VERSION "HNNBNNNYNNNNNNNNNNNNNNNNNNNNNNNNNNNNNNNNNN/4/%%%/4/'%**4NNN///"

NS_ :

BS_:

BU_: BAP_Tester FASFrontradar ICAS1_X_Gateway MFK MFK120 MIK MRR2023 NR_1 NR_2

BO_ 258 ESC_50: 48 ICAS1_X_Gateway
 SG_ ESC_50_CRC : 0|8@1+ (1,0) [0|255] ""  FASFrontradar,MFK,MFK120,MRR2023
 SG_ ESC_50_BZ : 8|4@1+ (1,0) [0|15] ""  FASFrontradar,MFK,MFK120,MRR2023
 SG_ ESP_QBit_Gierrate : 12|1@1+ (1.0,0.0) [0.0|1] ""  FASFrontradar,MFK,MFK120,MRR2023
 SG_ ESP_QBit_Laengsbeschl : 13|1@1+ (1.0,0.0) [0.0|1] ""  FASFrontradar,MFK,MFK120,MRR2023
 SG_ ESP_QBit_Querb : 14|1@1+ (1.0,0.0) [0.0|1] ""  FASFrontradar,MFK,MFK120,MRR2023
 SG_ ESP_Querbeschleunigung : 16|8@1+ (0.01,-1.27) [-1.27|1.27] "Unit_ForceOfGravi"  FASFrontradar,MFK,MFK120,MRR2023
 SG_ ESP_Laengsbeschl : 24|10@1+ (0.03125,-16) [-16.00000|15.90625] "Unit_MeterPerSeconSquar"  FASFrontradar,MFK,MFK120,MRR2023
 SG_ ESC_Motorstartverzoegerung : 34|1@1+ (1.0,0.0) [0.0|1] ""  Vector__XXX
 SG_ ESC_SeitenwindAssistent_Eingriff : 35|1@1+ (1.0,0.0) [0.0|1] ""  Vector__XXX
 SG_ ESP_Anschleppstart_Freigabe : 36|2@1+ (1.0,0.0) [0.0|3] ""  Vector__XXX
 SG_ ESC_Unterdruckmangel_erkannt : 38|1@1+ (1.0,0.0) [0.0|1] ""  Vector__XXX
 SG_ ESP_Gierrate : 40|14@1+ (0.01,0) [0.00|163.82] "Unit_DegreOfArcPerSecon"  FASFrontradar,MFK,MFK120,MRR2023
 SG_ ESP_VZ_Gierrate : 54|1@1+ (1.0,0.0) [0.0|1] ""  FASFrontradar,MFK,MFK120,MRR2023
 SG_ ESP_Notbremsanzeige : 55|1@1+ (1.0,0.0) [0.0|1] ""  Vector__XXX
 SG_ ESP_SpannungsAnf : 56|1@1+ (1.0,0.0) [0.0|1] ""  Vector__XXX
 SG_ ESP_PLA_Abbruch : 57|3@1+ (1.0,0.0) [0.0|7] ""  Vector__XXX
 SG_ ESP_Status_ESP_PLA : 60|4@1+ (1.0,0.0) [0.0|15] ""  Vector__XXX
 SG_ ESP_QBit_Bremsdruck : 76|1@1+ (1.0,0.0) [0.0|1] ""  FASFrontradar,MFK,MFK120,MRR2023
 SG_ ESP_QBit_Fahrer_bremst : 77|1@1+ (1.0,0.0) [0.0|1] ""  Vector__XXX
 SG_ ESP_Schwelle_Unterdruck : 78|2@1+ (1.0,0.0) [0.0|3] ""  Vector__XXX
 SG_ ESP_Bremsdruck : 80|10@1+ (0.3,-30) [-30.0|276.6] "Unit_Bar"  FASFrontradar,MFK,MFK120,MRR2023
 SG_ ESP_Fahrer_bremst : 90|1@1+ (1.0,0.0) [0.0|1] ""  MFK,MFK120,MRR2023
 SG_ ESP_Verz_TSK_aktiv : 91|1@1+ (1.0,0.0) [0.0|1] ""  Vector__XXX
 SG_ ESP_Lenkeingriff_ADS : 92|1@1+ (1.0,0.0) [0.0|1] ""  Vector__XXX
 SG_ ESP_Konsistenz_TSK : 93|1@1+ (1.0,0.0) [0.0|1] ""  Vector__XXX
 SG_ ESP_Bremsruck_AWV2 : 94|1@1+ (1.0,0.0) [0.0|1] ""  Vector__XXX
 SG_ ESP_Konsistenz_AWV2 : 95|1@1+ (1.0,0.0) [0.0|1] ""  Vector__XXX
 SG_ ECD_Fehler : 96|1@1+ (1.0,0.0) [0.0|1] ""  Vector__XXX
 SG_ ECD_nicht_verfuegbar : 97|1@1+ (1.0,0.0) [0.0|1] ""  Vector__XXX
 SG_ ESP_Status_Bremsentemp : 98|1@1+ (1.0,0.0) [0.0|1] ""  Vector__XXX
 SG_ ESP_Autohold_Standby : 99|1@1+ (1.0,0.0) [0.0|1] ""  FASFrontradar,MRR2023
 SG_ ESP_HDC_Standby : 100|1@1+ (1.0,0.0) [0.0|1] ""  Vector__XXX
 SG_ ESP_HBA_aktiv : 101|1@1+ (1.0,0.0) [0.0|1] ""  Vector__XXX
 SG_ ESP_Prefill_ausgeloest : 102|1@1+ (1.0,0.0) [0.0|1] ""  MFK,MFK120
 SG_ ESP_Rueckwaertsfahrt_erkannt : 103|1@1+ (1.0,0.0) [0.0|1] ""  Vector__XXX
 SG_ ESP_Status_Anfahrhilfe : 104|1@1+ (1.0,0.0) [0.0|1] ""  Vector__XXX
 SG_ ESP_HDC_aktiv : 105|1@1+ (1.0,0.0) [0.0|1] ""  Vector__XXX
 SG_ ESP_StartStopp_Info : 106|2@1+ (1.0,0.0) [0.0|3] ""  Vector__XXX
 SG_ ESP_Eingr_HL : 108|1@1+ (1.0,0.0) [0.0|1] ""  Vector__XXX
 SG_ ESP_Eingr_HR : 109|1@1+ (1.0,0.0) [0.0|1] ""  Vector__XXX
 SG_ ESP_Eingr_VL : 110|1@1+ (1.0,0.0) [0.0|1] ""  Vector__XXX
 SG_ ESP_Eingr_VR : 111|1@1+ (1.0,0.0) [0.0|1] ""  Vector__XXX
 SG_ ESP_BKV_Unterdruck : 112|8@1+ (4,0) [4|1012] "Unit_MilliBar"  Vector__XXX
 SG_ ESP_Autohold_aktiv : 120|1@1+ (1.0,0.0) [0.0|1] ""  Vector__XXX
 SG_ ESP_FStatus_Anfahrhilfe : 121|1@1+ (1.0,0.0) [0.0|1] ""  Vector__XXX
 SG_ ESP_Verz_EPB_aktiv : 122|1@1+ (1.0,0.0) [0.0|1] ""  Vector__XXX
 SG_ ECD_Bremslicht : 123|1@1+ (1.0,0.0) [0.0|1] ""  MFK,MFK120
 SG_ ESP_Verzoeg_EPB_verf : 124|1@1+ (1.0,0.0) [0.0|1] ""  Vector__XXX
 SG_ ESP_Status_Bremsdruck : 125|1@1+ (1.0,0.0) [0.0|1] ""  Vector__XXX
 SG_ ESP_Anforderung_EPB : 126|2@1+ (1.0,0.0) [0.0|3] ""  Vector__XXX
 SG_ ESC_Fahrerradbremswunschmoment : 128|12@1+ (6,-2400) [-2400|22158] "Unit_NewtoMeter"  Vector__XXX
 SG_ ESP_ANB_CM_Rueckk_Umsetz : 140|1@1+ (1.0,0.0) [0.0|1] ""  Vector__XXX
 SG_ ESP_Konsistenz_ACC_Botschaft : 141|1@1+ (1.0,0.0) [0.0|1] ""  Vector__XXX
 SG_ ESP_Stillstandsphase_erschoepft : 142|1@1+ (1.0,0.0) [0.0|1] ""  Vector__XXX
 SG_ ESP_ZT_Rueckk_Umsetz : 143|1@1+ (1.0,0.0) [0.0|1] ""  Vector__XXX
 SG_ ESP_Tuerkontakt_Fahrertuer : 144|1@1+ (1.0,0.0) [0.0|1] ""  Vector__XXX
 SG_ ESP_Abrutschen_Stillstand : 146|1@1+ (1.0,0.0) [0.0|1] ""  Vector__XXX
 SG_ ESP_Fahrer_tritt_ZBR_Schw : 147|1@1+ (1.0,0.0) [0.0|1] ""  Vector__XXX
 SG_ ESP_Systemstatus_03 : 148|2@1+ (1.0,0.0) [0.0|3] ""  MRR2023
 SG_ ASR_Systemstatus : 150|2@1+ (1.0,0.0) [0.0|3] ""  Vector__XXX
 SG_ ESP_QBit_v_ref : 169|1@1+ (1.0,0.0) [0.0|1] ""  MFK
 SG_ ESP_v_ref_Fahrtrichtung : 170|2@1+ (1.0,0.0) [0.0|3] ""  MFK
 SG_ ESC_Bremsdruckgradient : 172|8@1+ (10,0) [0|2500] "Unit_BarPerSecon"  Vector__XXX
 SG_ ESP_v_ref : 180|12@1+ (0.125,0) [0.000|511.500] "Unit_KiloMeterPerHour"  MFK
 SG_ ESP_HBA_Empfindlichkeit : 220|3@1+ (1.0,0.0) [0.0|7] ""  Vector__XXX
 SG_ ESC_Hydr_Fkt_aktiv : 223|2@1+ (1.0,0.0) [0.0|3] ""  Vector__XXX
 SG_ ESC_QBit_Fahrerbremswunsch : 225|1@1+ (1.0,0.0) [0.0|1] ""  FASFrontradar,MFK,MFK120,MRR2023
 SG_ ESC_Fahrerbremswunsch : 226|10@1+ (0.3,-30) [-30.0|276.6] "Unit_Bar"  FASFrontradar,MFK,MFK120,MRR2023
 SG_ ESCGeneratorSollMoment : 236|12@1+ (3,-12279) [-12279|0] ""  Vector__XXX
 SG_ ESC_Raddruck_max : 248|8@1+ (1,0) [0|250] "Unit_Bar"  Vector__XXX
 SG_ EPB_QBit_Pedalweg_Kuppl : 269|1@1+ (1.0,0.0) [0.0|1] ""  Vector__XXX
 SG_ EPB_Freig_Verzoeg_Anf : 271|1@1+ (1.0,0.0) [0.0|1] ""  Vector__XXX
 SG_ EPB_Verzoeg_Anf : 272|8@1+ (0.048,-7.968) [-7.968|4.224] "Unit_MeterPerSeconSquar"  Vector__XXX
 SG_ EPB_Pedalweg_Kuppl : 288|8@1+ (0.4,0) [8.0|92.0] "Unit_PerCent"  Vector__XXX
 SG_ EPB_DAA_Randbed_erf : 305|1@1+ (1.0,0.0) [0.0|1] ""  Vector__XXX
 SG_ EPB_Fehlerstatus_02 : 306|2@1+ (1.0,0.0) [0.0|3] ""  MFK120
 SG_ EPB_Schalterposition : 308|2@1+ (1.0,0.0) [0.0|3] ""  FASFrontradar,MFK,MFK120,MRR2023
 SG_ EPB_QBit_Schalterpos : 310|1@1+ (1.0,0.0) [0.0|1] ""  FASFrontradar,MFK120,MRR2023
 SG_ EPB_Spannkraft : 312|5@1+ (1,0) [0|29] "Unit_KiloNewto"  Vector__XXX
 SG_ EPB_Status_02 : 317|3@1+ (1.0,0.0) [0.0|7] ""  FASFrontradar,MRR2023
 SG_ EPB_Status : 320|2@1+ (1.0,0.0) [0.0|3] ""  Vector__XXX
 SG_ ESP_Status_Bremsentemp_02 : 322|2@1+ (1.0,0.0) [0.0|3] ""  FASFrontradar,MRR2023
 SG_ SOK_ESC_50_Signatur : 352|32@1+ (1,0) [0|4294967295] ""  Vector__XXX

BO_ 252 ESC_51_Auth: 64 ICAS1_X_Gateway
 SG_ ESC_51_CRC : 0|8@1+ (1,0) [0|255] ""  FASFrontradar,MRR2023
 SG_ ESC_51_BZ : 8|4@1+ (1,0) [0|15] ""  FASFrontradar,MRR2023
 SG_ ESC_aktBR_Modus_02 : 12|2@1+ (1.0,0.0) [0.0|3] ""  Vector__XXX
 SG_ ESC_Blending_Solldruck : 14|10@1+ (0.25,0) [0.00|250.00] "Unit_Bar"  Vector__XXX
 SG_ ESC_aktBr_Volumenstrom : 24|16@1+ (0.0078125,-252) [-252.0000000|252.0000000] "Unit_MilliLiterPerSec"  Vector__XXX
 SG_ ESC_EBKV_Kraftblending_Modus : 40|2@1+ (1.0,0.0) [0.0|3] ""  Vector__XXX
 SG_ ESC_Bremsdruck_Modell : 42|10@1+ (0.25,0) [0.00|250.00] "Unit_Bar"  Vector__XXX
 SG_ ESC_Bremsdruck_02 : 52|10@1+ (0.3,-30) [-30.0|276.6] "Unit_Bar"  Vector__XXX
 SG_ ESC_QBit_Bremsdruck_02 : 62|1@1+ (1.0,0.0) [0.0|1] ""  Vector__XXX
 SG_ ESC_Allradverteilung_aktiv : 63|1@1+ (1.0,0.0) [0.0|1] ""  Vector__XXX
 SG_ ESP_HL_Radgeschw_02 : 64|16@1+ (0.0075,0) [0.0000|491.4900] "Unit_KiloMeterPerHour"  FASFrontradar,MFK,MFK120,MRR2023
 SG_ ESP_HR_Radgeschw_02 : 80|16@1+ (0.0075,0) [0.0000|491.4900] "Unit_KiloMeterPerHour"  FASFrontradar,MFK,MFK120,MRR2023
 SG_ ESP_VL_Radgeschw_02 : 96|16@1+ (0.0075,0) [0.0000|491.4900] "Unit_KiloMeterPerHour"  FASFrontradar,MFK,MFK120,MRR2023
 SG_ ESP_VR_Radgeschw_02 : 112|16@1+ (0.0075,0) [0.0000|491.4900] "Unit_KiloMeterPerHour"  FASFrontradar,MFK,MFK120,MRR2023
 SG_ ESP_FZR_uebersteuern : 128|8@1+ (0.004,0) [0.000|1.000] ""  FASFrontradar,MRR2023
 SG_ ESP_FZR_untersteuern : 136|8@1+ (0.004,0) [0.000|1.000] ""  FASFrontradar,MRR2023
 SG_ ESC_Anf_Mindestreku : 144|1@1+ (1.0,0.0) [0.0|1] ""  Vector__XXX
 SG_ ESC_GMV_aktiv : 145|3@1+ (1.0,0.0) [0.0|7] ""  FASFrontradar,MRR2023
 SG_ ESC_GMV_nicht_verfuegbar : 148|1@1+ (1.0,0.0) [0.0|1] ""  MRR2023
 SG_ ESC_Status_vRef_Stuetzeingriff : 149|1@1+ (1.0,0.0) [0.0|1] ""  Vector__XXX
 SG_ FDR_Allradverteilung_aktiv : 150|1@1+ (1.0,0.0) [0.0|1] ""  Vector__XXX
 SG_ FDR_Anf_Allradbetrieb : 151|1@1+ (1.0,0.0) [0.0|1] ""  Vector__XXX
 SG_ ESP_HL_Bremsmoment : 152|8@1+ (20,0) [0|5060] "Unit_NewtoMeter"  Vector__XXX
 SG_ ESP_HR_Bremsmoment : 160|8@1+ (20,0) [0|5060] "Unit_NewtoMeter"  Vector__XXX
 SG_ ESP_VR_Bremsmoment : 168|8@1+ (40,0) [0|10120] "Unit_NewtoMeter"  Vector__XXX
 SG_ ESP_VL_Bremsmoment : 176|8@1+ (40,0) [0|10120] "Unit_NewtoMeter"  Vector__XXX
 SG_ ESP_FDR_uebersteuern : 184|8@1+ (0.004,0) [0.000|1.000] ""  Vector__XXX
 SG_ ESP_FDR_untersteuern : 192|8@1+ (0.004,0) [0.000|1.000] ""  Vector__XXX
 SG_ TSMomBegrenzung : 268|12@1+ (3,-12279) [-12279|0] ""  Vector__XXX
 SG_ ESC_Allrad_Anteil_max_sek : 280|9@1+ (0.2,0) [0.0|100.0] "Unit_PerCent"  Vector__XXX
 SG_ ESC_Allrad_Anteil_min_sek : 289|9@1+ (0.2,0) [0.0|100.0] "Unit_PerCent"  Vector__XXX
 SG_ ESC_Status_Eingriff : 298|2@1+ (1.0,0.0) [0.0|3] ""  MFK120
 SG_ ESC_Status_Eingriff_sek : 300|2@1+ (1.0,0.0) [0.0|3] ""  Vector__XXX
 SG_ ESC_MomRad_Eingriff : 302|13@1+ (3,-12279) [-12279|12279] "Unit_None"  Vector__XXX
 SG_ ESC_MomRad_Eingriff_sek : 315|13@1+ (3,-12279) [-12279|12279] "Unit_None"  Vector__XXX
 SG_ ESC_Achsdrehzahl_Max : 328|14@1+ (0.4,-800) [-800.0|5752.4] "Unit_MinutInver"  Vector__XXX
 SG_ ESC_Achsdrehzahl_Min : 342|14@1+ (0.4,-800) [-800.0|5752.4] "Unit_MinutInver"  Vector__XXX
 SG_ ESC_Achsdrehzahl_Max_sek : 356|14@1+ (0.4,-800) [-800.0|5752.4] "Unit_MinutInver"  Vector__XXX
 SG_ ESC_Achsdrehzahl_Min_sek : 370|14@1+ (0.4,-800) [-800.0|5752.4] "Unit_MinutInver"  Vector__XXX
 SG_ SOK_ESC_51_Signatur : 480|32@1+ (1,0) [0|4294967295] ""  Vector__XXX

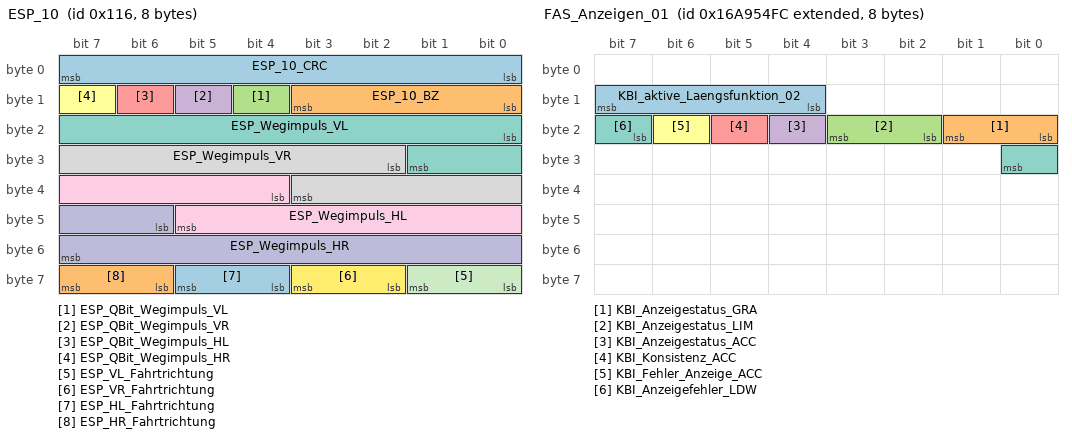
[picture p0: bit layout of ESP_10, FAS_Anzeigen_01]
BO_ 278 ESP_10: 8 ICAS1_X_Gateway
 SG_ ESP_10_CRC : 0|8@1+ (1,0) [0|255] ""  FASFrontradar,MRR2023
 SG_ ESP_10_BZ : 8|4@1+ (1,0) [0|15] ""  FASFrontradar,MRR2023
 SG_ ESP_QBit_Wegimpuls_VL : 12|1@1+ (1.0,0.0) [0.0|1] ""  FASFrontradar,MFK,MFK120,MRR2023
 SG_ ESP_QBit_Wegimpuls_VR : 13|1@1+ (1.0,0.0) [0.0|1] ""  FASFrontradar,MFK,MFK120,MRR2023
 SG_ ESP_QBit_Wegimpuls_HL : 14|1@1+ (1.0,0.0) [0.0|1] ""  FASFrontradar,MFK,MFK120,MRR2023
 SG_ ESP_QBit_Wegimpuls_HR : 15|1@1+ (1.0,0.0) [0.0|1] ""  FASFrontradar,MFK,MFK120,MRR2023
 SG_ ESP_Wegimpuls_VL : 16|10@1+ (1,0) [0|1000] ""  FASFrontradar,MFK,MFK120,MRR2023
 SG_ ESP_Wegimpuls_VR : 26|10@1+ (1,0) [0|1000] ""  FASFrontradar,MFK,MFK120,MRR2023
 SG_ ESP_Wegimpuls_HL : 36|10@1+ (1,0) [0|1000] ""  FASFrontradar,MFK,MFK120,MRR2023
 SG_ ESP_Wegimpuls_HR : 46|10@1+ (1,0) [0|1000] ""  FASFrontradar,MFK,MFK120,MRR2023
 SG_ ESP_VL_Fahrtrichtung : 56|2@1+ (1.0,0.0) [0.0|3] ""  FASFrontradar,MFK,MFK120,MRR2023
 SG_ ESP_VR_Fahrtrichtung : 58|2@1+ (1.0,0.0) [0.0|3] ""  FASFrontradar,MFK,MFK120,MRR2023
 SG_ ESP_HL_Fahrtrichtung : 60|2@1+ (1.0,0.0) [0.0|3] ""  FASFrontradar,MFK,MFK120,MRR2023
 SG_ ESP_HR_Fahrtrichtung : 62|2@1+ (1.0,0.0) [0.0|3] ""  FASFrontradar,MFK,MFK120,MRR2023

BO_ 1629 ESP_20: 8 ICAS1_X_Gateway
 SG_ ESP_20_CRC : 0|8@1+ (1,0) [0|255] ""  MRR2023
 SG_ ESP_20_BZ : 8|4@1+ (1,0) [0|15] ""  MRR2023
 SG_ BR_Systemart : 12|2@1+ (1.0,0.0) [0.0|3] ""  Vector__XXX
 SG_ ESP_SpannungsAnf_02 : 14|2@1+ (1.0,0.0) [0.0|3] ""  Vector__XXX
 SG_ ESP_Zaehnezahl : 16|8@1+ (1,0) [0|255] ""  FASFrontradar,MFK120,MRR2023
 SG_ ESP_Charisma_FahrPr : 24|4@1+ (1.0,0.0) [0.0|15] ""  Vector__XXX
 SG_ ESP_Charisma_Status : 28|2@1+ (1.0,0.0) [0.0|3] ""  Vector__XXX
 SG_ ESP_Wiederstart_Anz_01 : 30|1@1+ (1.0,0.0) [0.0|1] ""  Vector__XXX
 SG_ ESP_Wiederstart_Anz_02 : 31|1@1+ (1.0,0.0) [0.0|1] ""  Vector__XXX
 SG_ ESP_Wiederstart_Anz_03 : 32|1@1+ (1.0,0.0) [0.0|1] ""  Vector__XXX
 SG_ ESP_Wiederstart_Anz_04 : 33|1@1+ (1.0,0.0) [0.0|1] ""  Vector__XXX
 SG_ ESP_Stoppverbot_Anz_01 : 34|1@1+ (1.0,0.0) [0.0|1] ""  Vector__XXX
 SG_ ESP_Stoppverbot_Anz_02 : 35|1@1+ (1.0,0.0) [0.0|1] ""  Vector__XXX
 SG_ ESP_Stoppverbot_Anz_03 : 36|1@1+ (1.0,0.0) [0.0|1] ""  Vector__XXX
 SG_ ESP_Stoppverbot_Anz_04 : 37|1@1+ (1.0,0.0) [0.0|1] ""  Vector__XXX
 SG_ ESP_Stoppverbot_Anz_05 : 38|1@1+ (1.0,0.0) [0.0|1] ""  Vector__XXX
 SG_ ESP_Stoppverbot_Anz_06 : 39|1@1+ (1.0,0.0) [0.0|1] ""  Vector__XXX
 SG_ ESP_Stoppverbot_Anz_07 : 40|1@1+ (1.0,0.0) [0.0|1] ""  Vector__XXX
 SG_ ESP_Stoppverbot_Anz_Std : 41|1@1+ (1.0,0.0) [0.0|1] ""  Vector__XXX
 SG_ ESP_Dachrelingsensor : 42|2@1+ (1.0,0.0) [0.0|3] ""  Vector__XXX
 SG_ ESP_Stoppverbot_Anz_08 : 44|1@1+ (1.0,0.0) [0.0|1] ""  Vector__XXX
 SG_ HDC_Charisma_FahrPr : 45|4@1+ (1.0,0.0) [0.0|15] ""  Vector__XXX
 SG_ HDC_Charisma_Status : 49|2@1+ (1.0,0.0) [0.0|3] ""  Vector__XXX
 SG_ BR_QBit_Reifenumfang : 51|1@1+ (1.0,0.0) [0.0|1] ""  MFK,MFK120
 SG_ BR_Reifenumfang : 52|12@1+ (1,0) [0|4095] "Unit_MilliMeter"  MFK,MFK120

BO_ 253 ESP_21: 8 ICAS1_X_Gateway
 SG_ ESP_21_CRC : 0|8@1+ (1,0) [0|255] ""  FASFrontradar,MFK,MFK120,MRR2023
 SG_ ESP_21_BZ : 8|4@1+ (1,0) [0|15] ""  FASFrontradar,MFK,MFK120,MRR2023
 SG_ BR_Eingriffsmoment : 12|10@1+ (1,-509) [-509|509] ""  Vector__XXX
 SG_ ESP_PLA_Bremseingriff : 22|1@1+ (1.0,0.0) [0.0|1] ""  Vector__XXX
 SG_ ESP_Diagnose : 23|1@1+ (1.0,0.0) [0.0|1] ""  FASFrontradar,MRR2023
 SG_ ESC_Reku_Freigabe : 24|1@1+ (1.0,0.0) [0.0|1] ""  Vector__XXX
 SG_ ESC_v_Signal_Qualifier_High_Low : 25|3@1+ (1.0,0.0) [0.0|7] ""  FASFrontradar,MFK,MFK120,MIK,MRR2023
 SG_ ESP_Vorsteuerung : 28|1@1+ (1.0,0.0) [0.0|1] ""  FASFrontradar,MRR2023
 SG_ ESP_AWV3_Brems_aktiv : 29|1@1+ (1.0,0.0) [0.0|1] ""  Vector__XXX
 SG_ OBD_Schlechtweg : 30|1@1+ (1.0,0.0) [0.0|1] ""  Vector__XXX
 SG_ OBD_QBit_Schlechtweg : 31|1@1+ (1.0,0.0) [0.0|1] ""  Vector__XXX
 SG_ ESP_v_Signal : 32|16@1+ (0.01,0) [0.00|655.32] "Unit_KiloMeterPerHour"  FASFrontradar,MFK,MFK120,MIK,MRR2023
 SG_ ASR_Tastung_passiv : 48|1@1+ (1.0,0.0) [0.0|1] ""  FASFrontradar,MFK,MFK120,MRR2023
 SG_ ESP_Tastung_passiv : 49|1@1+ (1.0,0.0) [0.0|1] ""  FASFrontradar,MFK,MFK120,MRR2023
 SG_ ESP_Systemstatus : 50|1@1+ (1.0,0.0) [0.0|1] ""  FASFrontradar,MFK,MFK120,MRR2023
 SG_ ASR_Schalteingriff : 51|2@1+ (1.0,0.0) [0.0|3] ""  Vector__XXX
 SG_ ESP_Haltebestaetigung : 53|1@1+ (1.0,0.0) [0.0|1] ""  Vector__XXX
 SG_ ESP_MKB_Abbruch_Geschw : 54|1@1+ (1.0,0.0) [0.0|1] ""  Vector__XXX
 SG_ ESP_QBit_v_Signal : 55|1@1+ (1.0,0.0) [0.0|1] ""  FASFrontradar,MFK,MFK120,MIK,MRR2023
 SG_ ABS_Bremsung : 56|1@1+ (1.0,0.0) [0.0|1] ""  FASFrontradar,MFK,MFK120,MRR2023
 SG_ ASR_Anf : 57|1@1+ (1.0,0.0) [0.0|1] ""  FASFrontradar,MFK,MFK120,MRR2023
 SG_ MSR_Anf : 58|1@1+ (1.0,0.0) [0.0|1] ""  FASFrontradar,MFK,MFK120,MRR2023
 SG_ EBV_Eingriff : 59|1@1+ (1.0,0.0) [0.0|1] ""  FASFrontradar,MRR2023
 SG_ EDS_Eingriff : 60|1@1+ (1.0,0.0) [0.0|1] ""  FASFrontradar,MFK,MRR2023
 SG_ ESP_Eingriff : 61|1@1+ (1.0,0.0) [0.0|1] ""  FASFrontradar,MFK,MFK120,MRR2023
 SG_ ESP_ASP : 62|1@1+ (1.0,0.0) [0.0|1] ""  FASFrontradar,MFK,MFK120,MRR2023
 SG_ ESP_Anhaltevorgang_ACC_aktiv : 63|1@1+ (1.0,0.0) [0.0|1] ""  Vector__XXX

BO_ 2527679740 FAS_Anzeigen_01: 8 ICAS1_X_Gateway
 SG_ KBI_aktive_Laengsfunktion_02 : 12|4@1+ (1.0,0.0) [0.0|15] ""  FASFrontradar,MFK,MFK120,MRR2023
 SG_ KBI_Anzeigestatus_GRA : 16|2@1+ (1.0,0.0) [0.0|3] ""  Vector__XXX
 SG_ KBI_Anzeigestatus_LIM : 18|2@1+ (1.0,0.0) [0.0|3] ""  Vector__XXX
 SG_ KBI_Anzeigestatus_ACC : 20|1@1+ (1.0,0.0) [0.0|1] ""  FASFrontradar,MRR2023
 SG_ KBI_Konsistenz_ACC : 21|1@1+ (1.0,0.0) [0.0|1] ""  FASFrontradar,MRR2023
 SG_ KBI_Fehler_Anzeige_ACC : 22|1@1+ (1.0,0.0) [0.0|1] ""  FASFrontradar,MRR2023
 SG_ KBI_Anzeigefehler_LDW : 23|2@1+ (1.0,0.0) [0.0|3] ""  MFK

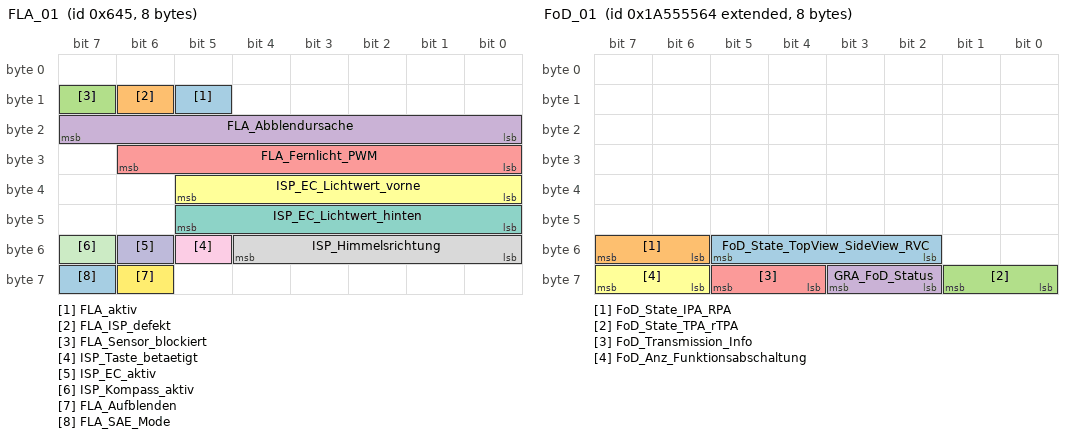
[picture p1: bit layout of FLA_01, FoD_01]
BO_ 1605 FLA_01: 8 MFK
 SG_ FLA_aktiv : 13|1@1+ (1.0,0.0) [0.0|1] ""  ICAS1_X_Gateway
 SG_ FLA_ISP_defekt : 14|1@1+ (1.0,0.0) [0.0|1] ""  ICAS1_X_Gateway
 SG_ FLA_Sensor_blockiert : 15|1@1+ (1.0,0.0) [0.0|1] ""  ICAS1_X_Gateway
 SG_ FLA_Abblendursache : 16|8@1+ (1.0,0.0) [0.0|255] ""  ICAS1_X_Gateway
 SG_ FLA_Fernlicht_PWM : 24|7@1+ (1,0) [0|100] "Unit_PerCent"  ICAS1_X_Gateway
 SG_ ISP_EC_Lichtwert_vorne : 32|6@1+ (1,0) [0|61] "Unit_None"  ICAS1_X_Gateway
 SG_ ISP_EC_Lichtwert_hinten : 40|6@1+ (1,0) [0|61] "Unit_None"  ICAS1_X_Gateway
 SG_ ISP_Himmelsrichtung : 48|5@1+ (12,0) [0|348] "Unit_DegreOfArc"  ICAS1_X_Gateway
 SG_ ISP_Taste_betaetigt : 53|1@1+ (1.0,0.0) [0.0|1] ""  ICAS1_X_Gateway
 SG_ ISP_EC_aktiv : 54|1@1+ (1.0,0.0) [0.0|1] ""  ICAS1_X_Gateway
 SG_ ISP_Kompass_aktiv : 55|1@1+ (1.0,0.0) [0.0|1] ""  ICAS1_X_Gateway
 SG_ FLA_Aufblenden : 62|1@1+ (1.0,0.0) [0.0|1] ""  ICAS1_X_Gateway
 SG_ FLA_SAE_Mode : 63|1@1+ (1.0,0.0) [0.0|1] ""  ICAS1_X_Gateway

BO_ 2589283684 FoD_01: 8 ICAS1_X_Gateway
 SG_ FoD_State_TopView_SideView_RVC : 50|4@1+ (1.0,0.0) [0.0|15] ""  Vector__XXX
 SG_ FoD_State_IPA_RPA : 54|2@1+ (1.0,0.0) [0.0|3] ""  Vector__XXX
 SG_ FoD_State_TPA_rTPA : 56|2@1+ (1.0,0.0) [0.0|3] ""  MFK,MFK120
 SG_ GRA_FoD_Status : 58|2@1+ (1.0,0.0) [0.0|3] ""  Vector__XXX
 SG_ FoD_Transmission_Info : 60|2@1+ (1.0,0.0) [0.0|3] ""  FASFrontradar,MFK,MRR2023
 SG_ FoD_Anz_Funktionsabschaltung : 62|2@1+ (1.0,0.0) [0.0|3] ""  Vector__XXX

BO_ 2549875543 FoD_ACC_Req: 8 ICAS1_X_Gateway
 SG_ FoD_ACC_Req_Data : 0|64@1+ (1.0,0.0) [0.0|18446744073709551615] ""  FASFrontradar,MRR2023

BO_ 2550006615 FoD_ACC_Resp: 8 FASFrontradar
 SG_ FoD_ACC_Resp_Data : 0|64@1+ (1.0,0.0) [0.0|18446744073709551615] ""  ICAS1_X_Gateway

BO_ 2549875535 FoD_Kamera_Req: 8 ICAS1_X_Gateway
 SG_ FoD_Kamera_Req_Data : 0|64@1+ (1.0,0.0) [0.0|18446744073709551615] ""  MFK,MFK120

BO_ 2550006607 FoD_Kamera_Resp: 8 MFK
 SG_ FoD_Kamera_Resp_Data : 0|64@1+ (1.0,0.0) [0.0|18446744073709551615] ""  ICAS1_X_Gateway

BO_ 987 Gateway_72: 8 ICAS1_X_Gateway
 SG_ BCM_01_alt : 0|1@1+ (1.0,0.0) [0.0|1] ""  FASFrontradar,MRR2023
 SG_ SMLS_01_alt : 1|1@1+ (1.0,0.0) [0.0|1] ""  Vector__XXX
 SG_ ZV_02_alt : 2|1@1+ (1.0,0.0) [0.0|1] ""  Vector__XXX
 SG_ Wischer_01_alt : 3|1@1+ (1.0,0.0) [0.0|1] ""  FASFrontradar,MFK,MRR2023
 SG_ Anhaenger_01_alt : 4|1@1+ (1.0,0.0) [0.0|1] ""  Vector__XXX
 SG_ Klima_Sensor_02_alt : 5|1@1+ (1.0,0.0) [0.0|1] ""  FASFrontradar,MFK,MRR2023
 SG_ Verdeck_01_alt : 6|1@1+ (1.0,0.0) [0.0|1] ""  Vector__XXX
 SG_ Klima_11_alt : 7|1@1+ (1.0,0.0) [0.0|1] ""  Vector__XXX
 SG_ WFS_01_alt : 8|1@1+ (1.0,0.0) [0.0|1] ""  Vector__XXX
 SG_ Licht_Anf_01_alt : 9|1@1+ (1.0,0.0) [0.0|1] ""  Vector__XXX
 SG_ ZV_verriegelt_extern_soll : 10|1@1+ (1.0,0.0) [0.0|1] ""  Vector__XXX
 SG_ BH_Lichthupe : 11|1@1+ (1.0,0.0) [0.0|1] ""  Vector__XXX
 SG_ WFS_Klemmenfreigabe : 12|1@1+ (1.0,0.0) [0.0|1] ""  Vector__XXX
 SG_ ZV_Tankklappe_offen : 13|1@1+ (1.0,0.0) [0.0|1] ""  Vector__XXX
 SG_ AAG_Anhaenger_abgesteckt : 14|1@1+ (1.0,0.0) [0.0|1] ""  Vector__XXX
 SG_ BCM1_LDS_Stellung : 15|3@1+ (1.0,0.0) [0.0|7] ""  Vector__XXX
 SG_ VS_Verdeck_Anf : 18|1@1+ (1.0,0.0) [0.0|1] ""  Vector__XXX
 SG_ VS_VD_entriegelt : 19|1@1+ (1.0,0.0) [0.0|1] ""  Vector__XXX
 SG_ ZV_HFS_offen : 20|1@1+ (1.0,0.0) [0.0|1] ""  Vector__XXX
 SG_ ZV_HBFS_offen : 21|1@1+ (1.0,0.0) [0.0|1] ""  Vector__XXX
 SG_ VS_VD_offen_ver : 22|1@1+ (1.0,0.0) [0.0|1] ""  Vector__XXX
 SG_ VS_VD_zu_ver : 23|1@1+ (1.0,0.0) [0.0|1] ""  Vector__XXX
 SG_ ZV_BT_offen : 24|1@1+ (1.0,0.0) [0.0|1] ""  Vector__XXX
 SG_ BCM1_Rueckfahrlicht_Schalter : 25|1@1+ (1.0,0.0) [0.0|1] ""  Vector__XXX
 SG_ ZV_FT_offen : 26|1@1+ (1.0,0.0) [0.0|1] ""  Vector__XXX
 SG_ Wischer_vorne_aktiv : 27|1@1+ (1.0,0.0) [0.0|1] ""  FASFrontradar,MFK,MFK120,MRR2023
 SG_ AAG_Anhaenger_erkannt : 28|1@1+ (1.0,0.0) [0.0|1] ""  Vector__XXX
 SG_ BCM1_MH_Schalter : 29|1@1+ (1.0,0.0) [0.0|1] ""  FASFrontradar,MRR2023
 SG_ ZV_HD_offen : 30|1@1+ (1.0,0.0) [0.0|1] ""  Vector__XXX
 SG_ Waschen_vorne_aktiv : 31|1@1+ (1.0,0.0) [0.0|1] ""  Vector__XXX
 SG_ KL_Thermomanagement : 32|2@1+ (1.0,0.0) [0.0|3] ""  Vector__XXX
 SG_ WFS_Schluessel_Fahrberecht : 34|4@1+ (1.0,0.0) [0.0|15] ""  Vector__XXX
 SG_ BCM_Rueckfahrlicht_Anf : 38|1@1+ (1.0,0.0) [0.0|1] ""  Vector__XXX
 SG_ WWSs_01_alt : 39|1@1+ (1.0,0.0) [0.0|1] ""  MFK
 SG_ BCM_Tankklappensteller_Fehler : 40|1@1+ (1.0,0.0) [0.0|1] ""  Vector__XXX
 SG_ AAG_LED_aktiv : 41|1@1+ (1.0,0.0) [0.0|1] ""  Vector__XXX
 SG_ ZV_verriegelt_soll : 42|2@1+ (1.0,0.0) [0.0|3] ""  Vector__XXX
 SG_ ZV_Schluessel_Zugang : 44|4@1+ (1.0,0.0) [0.0|15] ""  Vector__XXX
 SG_ WFS_ID_Geb_autorisiert_in_Kl15 : 48|1@1+ (1.0,0.0) [0.0|1] ""  Vector__XXX
 SG_ BH_Fernlicht : 49|1@1+ (1.0,0.0) [0.0|1] ""  Vector__XXX
 SG_ BH_Blinker_li : 50|1@1+ (1.0,0.0) [0.0|1] ""  Vector__XXX
 SG_ BH_Blinker_re : 51|1@1+ (1.0,0.0) [0.0|1] ""  Vector__XXX
 SG_ BCM1_OBD_FStatus_ATemp : 52|4@1+ (1.0,0.0) [0.0|15] ""  Vector__XXX
 SG_ BCM1_Aussen_Temp_ungef : 56|8@1+ (0.5,-50) [-50.0|76.0] "Unit_DegreCelsi"  FASFrontradar,MFK,MFK120,MRR2023

BO_ 988 Gateway_73: 8 ICAS1_X_Gateway
 SG_ Motor_12_alt : 0|1@1+ (1.0,0.0) [0.0|1] ""  FASFrontradar,MRR2023
 SG_ ESP_07_alt : 1|1@1+ (1.0,0.0) [0.0|1] ""  FASFrontradar,MRR2023
 SG_ Getriebe_11_alt : 2|1@1+ (1.0,0.0) [0.0|1] ""  FASFrontradar,MFK
 SG_ Getriebe_13_alt : 3|1@1+ (1.0,0.0) [0.0|1] ""  Vector__XXX
 SG_ Getriebe_17_alt : 4|1@1+ (1.0,0.0) [0.0|1] ""  Vector__XXX
 SG_ TSK_06_alt : 5|1@1+ (1.0,0.0) [0.0|1] ""  Vector__XXX
 SG_ Getriebe_14_alt : 6|1@1+ (1.0,0.0) [0.0|1] ""  Vector__XXX
 SG_ ESP_50_alt : 7|1@1+ (1.0,0.0) [0.0|1] ""  Vector__XXX
 SG_ MO_QBit_Drehzahl_01 : 8|1@1+ (1.0,0.0) [0.0|1] ""  FASFrontradar,MRR2023
 SG_ MKE_Texte : 9|2@1+ (1.0,0.0) [0.0|3] ""  Vector__XXX
 SG_ MKE_Stufe : 11|3@1+ (1.0,0.0) [0.0|7] ""  Vector__XXX
 SG_ TSK_Hauptschalter_GRA_ACC : 14|2@1+ (1.0,0.0) [0.0|3] ""  Vector__XXX
 SG_ MO_Drehzahl_01 : 16|16@1+ (0.25,0) [0.00|16383.00] "Unit_MinutInver"  Vector__XXX
 SG_ GE_Fahrstufe : 40|4@1+ (1.0,0.0) [0.0|15] ""  FASFrontradar,MFK
 SG_ GE_Ursache_Fahrstufe_N : 44|1@1+ (1.0,0.0) [0.0|1] ""  Vector__XXX
 SG_ GE_Notlauf : 45|1@1+ (1.0,0.0) [0.0|1] ""  Vector__XXX
 SG_ ESP_Rollenmodus_Deaktivieren : 46|1@1+ (1.0,0.0) [0.0|1] ""  FASFrontradar,MFK,MRR2023
 SG_ GE_Freilauf_Status : 47|3@1+ (1.0,0.0) [0.0|7] ""  Vector__XXX
 SG_ GE_Sperr_Info_WFS : 50|1@1+ (1.0,0.0) [0.0|1] ""  Vector__XXX
 SG_ TSK_Limiter_ausgewaehlt : 51|1@1+ (1.0,0.0) [0.0|1] ""  Vector__XXX
 SG_ EPB_Status_02 : 53|3@1+ (1.0,0.0) [0.0|7] ""  Vector__XXX
 SG_ ACC_Status_ACC : 56|3@1+ (1.0,0.0) [0.0|7] ""  Vector__XXX
 SG_ ACC_18_alt : 59|1@1+ (1.0,0.0) [0.0|1] ""  Vector__XXX
 SG_ ESP_Status_Bremsentemp_02 : 62|2@1+ (1.0,0.0) [0.0|3] ""  Vector__XXX

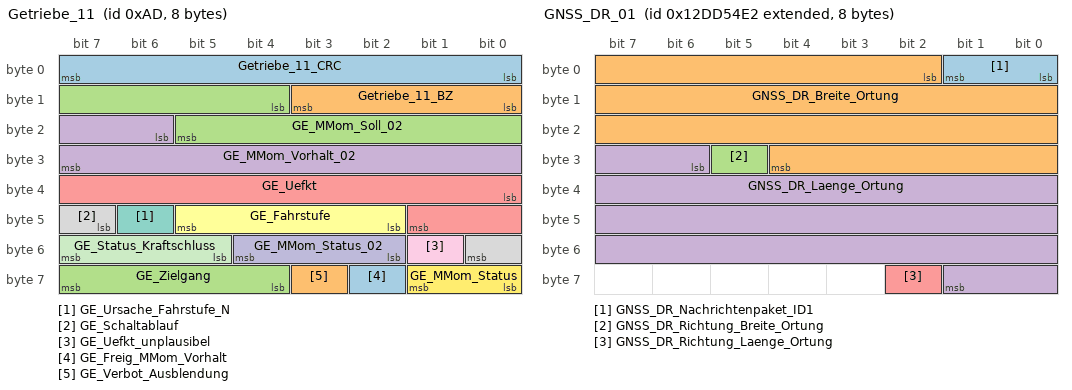
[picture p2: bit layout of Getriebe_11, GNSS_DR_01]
BO_ 173 Getriebe_11: 8 ICAS1_X_Gateway
 SG_ Getriebe_11_CRC : 0|8@1+ (1,0) [0|255] ""  Vector__XXX
 SG_ Getriebe_11_BZ : 8|4@1+ (1,0) [0|15] ""  Vector__XXX
 SG_ GE_MMom_Soll_02 : 12|10@1+ (1,-509) [-509|509] ""  Vector__XXX
 SG_ GE_MMom_Vorhalt_02 : 22|10@1+ (1,-509) [-509|509] ""  Vector__XXX
 SG_ GE_Uefkt : 32|10@1+ (0.1,0) [0.0|102.2] ""  Vector__XXX
 SG_ GE_Fahrstufe : 42|4@1+ (1.0,0.0) [0.0|15] ""  MFK120,MRR2023
 SG_ GE_Ursache_Fahrstufe_N : 46|1@1+ (1.0,0.0) [0.0|1] ""  Vector__XXX
 SG_ GE_Schaltablauf : 47|2@1+ (1.0,0.0) [0.0|3] ""  Vector__XXX
 SG_ GE_Uefkt_unplausibel : 49|1@1+ (1.0,0.0) [0.0|1] ""  Vector__XXX
 SG_ GE_MMom_Status_02 : 50|3@1+ (1.0,0.0) [0.0|7] ""  Vector__XXX
 SG_ GE_Status_Kraftschluss : 53|3@1+ (1.0,0.0) [0.0|7] ""  Vector__XXX
 SG_ GE_MMom_Status : 56|2@1+ (1.0,0.0) [0.0|3] ""  Vector__XXX
 SG_ GE_Freig_MMom_Vorhalt : 58|1@1+ (1.0,0.0) [0.0|1] ""  Vector__XXX
 SG_ GE_Verbot_Ausblendung : 59|1@1+ (1.0,0.0) [0.0|1] ""  Vector__XXX
 SG_ GE_Zielgang : 60|4@1+ (1.0,0.0) [0.0|15] ""  Vector__XXX

BO_ 2463978722 GNSS_DR_01: 8 ICAS1_X_Gateway
 SG_ GNSS_DR_Nachrichtenpaket_ID1 : 0|2@1+ (1,0) [0|3] "Unit_Bit"  Vector__XXX
 SG_ GNSS_DR_Breite_Ortung : 2|27@1+ (0.000001,0) [0.000000|90.000000] "Unit_DegreOfArc"  FASFrontradar,MRR2023
 SG_ GNSS_DR_Richtung_Breite_Ortung : 29|1@1+ (1.0,0.0) [0.0|1] ""  FASFrontradar,MRR2023
 SG_ GNSS_DR_Laenge_Ortung : 30|28@1+ (0.000001,0) [0.000000|180.000000] "Unit_DegreOfArc"  FASFrontradar,MRR2023
 SG_ GNSS_DR_Richtung_Laenge_Ortung : 58|1@1+ (1.0,0.0) [0.0|1] ""  FASFrontradar,MRR2023

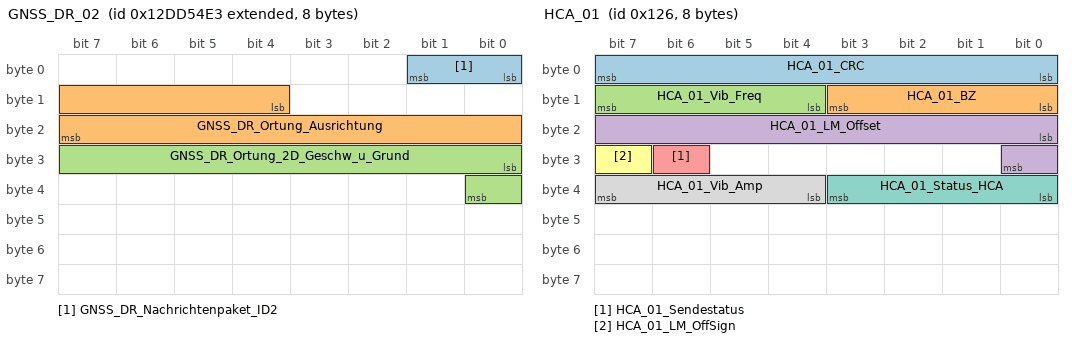
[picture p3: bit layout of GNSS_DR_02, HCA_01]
BO_ 2463978723 GNSS_DR_02: 8 ICAS1_X_Gateway
 SG_ GNSS_DR_Nachrichtenpaket_ID2 : 0|2@1+ (1,0) [0|3] "Unit_Bit"  Vector__XXX
 SG_ GNSS_DR_Ortung_Ausrichtung : 12|12@1+ (0.1,0) [0.0|359.9] "Unit_DegreOfArc"  FASFrontradar,MRR2023
 SG_ GNSS_DR_Ortung_2D_Geschw_u_Grund : 24|9@1+ (0.25,0) [0.00|125.00] "Unit_MeterPerSecon"  Vector__XXX

BO_ 299 GRA_ACC_01: 8 ICAS1_X_Gateway
 SG_ GRA_ACC_01_CRC : 0|8@1+ (1,0) [0|255] ""  FASFrontradar,MRR2023
 SG_ GRA_ACC_01_BZ : 8|4@1+ (1,0) [0|15] ""  FASFrontradar,MRR2023
 SG_ GRA_Hauptschalter : 12|1@1+ (1.0,0.0) [0.0|1] ""  FASFrontradar,MFK,MFK120,MRR2023
 SG_ GRA_Abbrechen : 13|1@1+ (1.0,0.0) [0.0|1] ""  FASFrontradar,MFK,MFK120,MRR2023
 SG_ GRA_Typ_Hauptschalter : 14|1@1+ (1.0,0.0) [0.0|1] ""  Vector__XXX
 SG_ GRA_Limiter : 15|1@1+ (1.0,0.0) [0.0|1] ""  Vector__XXX
 SG_ GRA_Tip_Setzen : 16|1@1+ (1.0,0.0) [0.0|1] ""  FASFrontradar,MFK,MFK120,MRR2023
 SG_ GRA_Tip_Hoch : 17|1@1+ (1.0,0.0) [0.0|1] ""  FASFrontradar,MFK,MFK120,MRR2023
 SG_ GRA_Tip_Runter : 18|1@1+ (1.0,0.0) [0.0|1] ""  FASFrontradar,MFK,MFK120,MRR2023
 SG_ GRA_Tip_Wiederaufnahme : 19|1@1+ (1.0,0.0) [0.0|1] ""  FASFrontradar,MFK,MFK120,MRR2023
 SG_ GRA_Verstellung_Zeitluecke : 20|2@1+ (1.0,0.0) [0.0|3] ""  FASFrontradar,MFK,MFK120,MRR2023
 SG_ GRA_Codierung : 22|2@1+ (1.0,0.0) [0.0|3] ""  FASFrontradar,MRR2023
 SG_ GRA_Fehler : 24|1@1+ (1.0,0.0) [0.0|1] ""  FASFrontradar,MRR2023
 SG_ GRA_LIM_Taste_verfuegbar : 25|1@1+ (1.0,0.0) [0.0|1] ""  Vector__XXX
 SG_ GRA_Tip_Stufe_2 : 26|1@1+ (1.0,0.0) [0.0|1] ""  FASFrontradar,MRR2023
 SG_ GRA_Typ_Bedienteil : 27|3@1+ (1.0,0.0) [0.0|7] ""  FASFrontradar,MRR2023
 SG_ GRA_TravelAssist : 30|1@1+ (1.0,0.0) [0.0|1] ""  FASFrontradar,MRR2023
 SG_ GRA_PIT_Limiter : 31|1@1+ (1.0,0.0) [0.0|1] ""  Vector__XXX
 SG_ GRA_reserveByte5 : 32|8@1+ (1.0,0.0) [0.0|255] ""  Vector__XXX
 SG_ GRA_reserveByte6 : 40|8@1+ (1.0,0.0) [0.0|255] ""  Vector__XXX
 SG_ GRA_reserveByte7 : 48|8@1+ (1.0,0.0) [0.0|255] ""  Vector__XXX
 SG_ GRA_reserveByte8 : 56|8@1+ (1.0,0.0) [0.0|255] ""  Vector__XXX

BO_ 294 HCA_01: 8 MFK
 SG_ HCA_01_CRC : 0|8@1+ (1,0) [0|255] ""  Vector__XXX
 SG_ HCA_01_BZ : 8|4@1+ (1,0) [0|15] ""  Vector__XXX
 SG_ HCA_01_Vib_Freq : 12|4@1+ (1,15) [15|30] "Unit_Hertz"  Vector__XXX
 SG_ HCA_01_LM_Offset : 16|9@1+ (0.01,0) [0.00|5.11] "Unit_NewtoMeter"  Vector__XXX
 SG_ HCA_01_Sendestatus : 30|1@1+ (1.0,0.0) [0.0|1] ""  Vector__XXX
 SG_ HCA_01_LM_OffSign : 31|1@1+ (1.0,0.0) [0.0|1] ""  Vector__XXX
 SG_ HCA_01_Status_HCA : 32|4@1+ (1.0,0.0) [0.0|15] ""  Vector__XXX
 SG_ HCA_01_Vib_Amp : 36|4@1+ (0.2,0) [0.0|3.0] "Unit_NewtoMeter"  Vector__XXX

BO_ 771 HCA_03: 24 MFK
 SG_ HCA_QFK_AnfStat : 12|4@1+ (1.0,0.0) [0.0|15] ""  ICAS1_X_Gateway
 SG_ HCA_QFK_Spuerb : 16|8@1+ (0.4,0) [0.0|100.0] "Unit_PerCent"  ICAS1_X_Gateway
 SG_ HCA_QFK_KruemmSoll : 24|15@1+ (0.0000067,0) [0E-7|0.2195389] "Unit_MeterInver"  ICAS1_X_Gateway
 SG_ HCA_QFK_KruemmSoll_VZ : 39|1@1+ (1.0,0.0) [0.0|1] ""  ICAS1_X_Gateway
 SG_ HCA_QFK_Signal1 : 40|10@1+ (1,0) [0|1023] ""  ICAS1_X_Gateway
 SG_ HCA_QFK_Art1 : 50|3@1+ (1,0) [0|7] ""  ICAS1_X_Gateway
 SG_ HCA_QFK_Art2 : 53|3@1+ (1,0) [0|7] ""  ICAS1_X_Gateway
 SG_ HCA_QFK_Signal2 : 56|10@1+ (1,0) [0|1023] ""  ICAS1_X_Gateway
 SG_ HCA_03_Sendestatus : 66|1@1+ (1.0,0.0) [0.0|1] ""  ICAS1_X_Gateway
 SG_ HCA_QFK_KrSoll_VZ : 67|1@1+ (1.0,0.0) [0.0|1] ""  ICAS1_X_Gateway
 SG_ FoD_DTC_TPA_rTPA_MFK : 68|2@1+ (1.0,0.0) [0.0|3] ""  ICAS1_X_Gateway
 SG_ HCA_QFK_KrSoll : 128|16@1+ (0.0000067,0) [0E-7|0.4390778] "Unit_MeterInver"  ICAS1_X_Gateway
 SG_ SOK_HCA_03_Signatur : 144|48@1+ (1,0) [0|281474976710655] "Unit_None"  ICAS1_X_Gateway

BO_TX_BU_ 1605 :MFK,MFK120;
BO_TX_BU_ 2550006615 :FASFrontradar,MRR2023;
BO_TX_BU_ 2550006607 :MFK,MFK120;
BO_TX_BU_ 771 :MFK,MFK120;
CM_ BO_ 1629 "neu im MQB";
CM_ BO_ 253 "Neue Momente im MQB
Struktur ab MQB mit CRC8 entstanden aus ESP_01";
CM_ BO_ 987 "Komfort -> Antrieb, Extended, Fahrwerk, Infotainment";
CM_ BO_ 988 "Antrieb, Fahrwerk -> Extended, Infotainment, Komfort";
CM_ BO_ 294 "für MQB verändertes Sendeverhalten
(nicht IL-kompatibel, da zwei Inaktiv-Werte im Signal HCA_01_Status_HCA)";

CM_ SG_ 258 ASR_Systemstatus "ASR-Systemstatus für Datenablage im EDR";
CM_ SG_ 258 ECD_Bremslicht "Bremslichtansteuerung durch ECD-Funktion";
CM_ SG_ 258 ECD_Fehler "ESP kann die Verzögerungsregelung/Bremsenregelung aufgrund eines internen Fehlers nicht ausführen, mit Fehlereintrag im ESP.
";
CM_ SG_ 258 ECD_nicht_verfuegbar "ESP kann die Verzögerungsregelung/Bremsenregelung temporär nicht ausführen (z.B. Netzwerkmanagement-Betriebe - KL15 Aus; v<18km/h; ESP in Diagnose, ...), ohne Fehlereintrag im ESP.

";
CM_ SG_ 258 EPB_DAA_Randbed_erf "Die Randbedingungen zum automatischen Öffnen der EPB (Funktion DAA) sind erfüllt und ein Betätigen des Fahrpedals führt zum Öffnen der EPB.";
CM_ SG_ 258 EPB_Fehlerstatus_02 "Anpassung der Texte an die  aktuellen Zustände für weitergehende Funktionen (Stillstandsmanager)";
CM_ SG_ 258 EPB_Freig_Verzoeg_Anf "Verzögerungsanforderung	";
CM_ SG_ 258 EPB_Pedalweg_Kuppl "Signal entspricht Tastverhältnis des PWM. Gesamtweg Kupplungspedal 10% bis 90%, damit zu erwartende Werte 25 bis 225. 25 bei Kupplungspedal nicht getreten, 225 bei Kupplungspedal voll durchgetreten.
2% Toleranz wird im Wertebereich ermöglicht (8%-92%).
";
CM_ SG_ 258 EPB_Schalterposition "Spiegelt die Schalterstellung wieder.

0x3 = Schalterfehler ";
CM_ SG_ 258 EPB_Spannkraft "Erzeugte Spannkraft. Bezieht sich auf die Aktuatoren.

MQB: Spannkraftwerte entsprechen nicht den tatsächlichen Spannkräften. Genauere Informationen bitte in der Fachabteilung erfragen! ";
CM_ SG_ 258 EPB_Status "Gibt den Zustand der EPB-Aktuatoren an.

Nur VW526/PAG E2: Wert 0x3 bedeutet 'unbekannt'

";
CM_ SG_ 258 EPB_Status_02 "Erweiterung der Zustände um ein genaueres Bild des aktuellen Zustandes zu erhalten für weitergehende Funktionen ( Stillstandsmanager)
";
CM_ SG_ 258 EPB_Verzoeg_Anf "Steuerungsanforderung an andere Systeme (z.B. ESP), um während der Fahrt, durch den Handbremsschalter ausgelöst, zu bremsen (ECD-Funktion)";
CM_ SG_ 258 ESC_50_BZ "4bit Botschaftszähler, wird mit jeder Sendebotschaft inkrementiert";
CM_ SG_ 258 ESC_50_CRC "Für MLB:
Berechnung siehe Lastenheft 'Kommunikationsabsicherung für FlexRay und CAN'
Ab MQB und MLBevo:
Berechnung siehe Lastenheft 'End-to-End Kommunikationsabsicherung'

Endwerte siehe Begleitdokument 'S-PDU Kennungsfolgen'";
CM_ SG_ 258 ESC_Bremsdruckgradient "Das Signal zeigt den vom Fahrer gedruckten Bremsdruckgradienten";
CM_ SG_ 258 ESC_Fahrerbremswunsch "PHEV: Berechneter Druck anhand des eBKV-Ausgangsstangenwegs sowie ESP-pMC. Reku nicht aktiv--> vergleichbar mit ESP_Bremsdruck; Reku aktiv --> virtueller Bremsdruck
Konv.: entspricht ESP_Bremsdruck";
CM_ SG_ 258 ESC_Fahrerradbremswunschmoment "Berechnetes Moment anhand des eBKV-Ausgangsstangenwegs, THZ-Druck, cp-Faktoren der Bremsen und Bremspedalbetätigung.
Reku nicht aktiv--> entspricht dem berechneten Moment auf Basis THZ-Druck; 
Reku aktiv --> entspricht dem berechneten Moment auf Basis v";
CM_ SG_ 258 ESC_Hydr_Fkt_aktiv "Info über die Aktivität von Druckaufbaufunktionen im ESC und Uebermittlung des Warnlevel an EBKV.";
CM_ SG_ 258 ESC_Motorstartverzoegerung "Mit dem Signal 'Motorstartverzögerung' wird den aktiven Teilnehmern ermöglicht, einen Motorstart durch die Start-Stop-Funktion zu verzögern.";
CM_ SG_ 258 ESC_QBit_Fahrerbremswunsch "Gesetzt bei Ersatzwert, Init oder Fehler.";
CM_ SG_ 258 ESC_Raddruck_max "Stellt den zahlenmäßig höchsten Druckwert der vier modellierten Raddrücke dar.";
CM_ SG_ 258 ESC_SeitenwindAssistent_Eingriff "Mit diesem Statusbit wird eine aktive Regelung durch den Seitenwindassistenten signalisiert.";
CM_ SG_ 258 ESC_Unterdruckmangel_erkannt "ESC hat einen Unterdruckmangel im Bremskraftverstärker festgestellt";
CM_ SG_ 258 ESCGeneratorSollMoment "In MLBevo Faktor in TS_Faktor_Radmomente beachten!

Verzögernd wirkender Antriebsstrangsollmomentenanteil aus Bremspedalbetätigung auf Summenradebene.";
CM_ SG_ 258 ESP_Abrutschen_Stillstand "Das ESP teilt über dieses Bit mit, dass ein Abrutschen im Stillstand erkannt wurde.

Im MQB wird das Signal nicht unterstützt!";
CM_ SG_ 258 ESP_ANB_CM_Rueckk_Umsetz "Das Signal dient als Rückmeldung zum ACC, dass eine angeforderte ANB-CM durchgeführt wird. Die positive Rückmeldung löst u.a. eine entsprechende Fahrerinformation im Kombiinstrument aus";
CM_ SG_ 258 ESP_Anforderung_EPB "ESP fordert von der EPB Öffnen bzw. Schliessen an. Notwendig wegen Autohold-Funktion.";
CM_ SG_ 258 ESP_Anschleppstart_Freigabe "Bilden einer Schleppstartfreigabe aus Fahrdynamiksicht. Schleppstartabbruch bei kritischer Fahrzeugstabilität";
CM_ SG_ 258 ESP_Autohold_aktiv "Rückmeldung an EPB, dass Autohold aktiv ist.";
CM_ SG_ 258 ESP_Autohold_Standby "Rückmeldung an EPB, dass der Fahrer die Funktion Autohold mindestens einmal angefordert hat. Im Fall eines ESP-Ausfalles oder einer Übernahmeaufforderung erfolgt die EPB-Zuschaltung nur nach Setzen dieses Bits. Bit wird gesetzt nach Betätigung des Autohol";
CM_ SG_ 258 ESP_BKV_Unterdruck "Der maximale Wert wird auf 1012 mbar begrenzt.
Dieses Signal wird im AU64x nicht unterstützt.

Hinweis: Auch bei nicht verbautem BKV-Unterdrucksensor könnte während der Initialisierung der Initialisierungswert gesendet werden.";
CM_ SG_ 258 ESP_Bremsdruck "Rohwert des Bremsdrucks
Für Fahrzeuge mit elektrischem Bremskraftverstärker gilt: Aus dem Signal ESP_Bremsdruck lässt sich kein Fahrerbremswunsch ableiten. Das Signal bildet lediglich den hydraulischen Anteil der Fahrzeugverzögerung ab. Der Rohwert des S";
CM_ SG_ 258 ESP_Bremsruck_AWV2 "Das Signal dient als Rückmeldung zum ACC, dass ein angeforderter AWV2-Bremsruck durchgeführt wird. Die positive Rückmeldung löst u.a. eine entsprechende Fahrerinformation im Kombiinstrument aus";
CM_ SG_ 258 ESP_Eingr_HL "wird von QSP und Neigungsanzeige verwendet

Flag wird vom ESP gesetzt, sobald aufgrund eines ESP-Eingriffs am Rad aktiv Druck aufgebaut wird.
Frühestens mit öffnen des Ventils und spätestens bei einem Bremsmoment von 100Nm. Flag bleibt solange gesetzt ";
CM_ SG_ 258 ESP_Eingr_HR "wird von QSP und Neigungsanzeige verwendet

Flag wird vom ESP gesetzt, sobald aufgrund eines ESP-Eingriffs am Rad aktiv Druck aufgebaut wird.
Frühestens mit öffnen des Ventils und spätestens bei einem Bremsmoment von 100Nm. Flag bleibt solange gesetzt ";
CM_ SG_ 258 ESP_Eingr_VL "wird von QSP und Neigungsanzeige verwendet

Flag wird vom ESP gesetzt, sobald aufgrund eines ESP-Eingriffs am Rad aktiv Druck aufgebaut wird.
Frühestens mit öffnen des Ventils und spätestens bei einem Bremsmoment von 100Nm. Flag bleibt solange gesetzt ";
CM_ SG_ 258 ESP_Eingr_VR "wird von QSP und Neigungsanzeige verwendet

Flag wird vom ESP gesetzt, sobald aufgrund eines ESP-Eingriffs am Rad aktiv Druck aufgebaut wird.
Frühestens mit öffnen des Ventils und spätestens bei einem Bremsmoment von 100Nm. Flag bleibt solange gesetzt ";
CM_ SG_ 258 ESP_Fahrer_bremst "Bit wird gesetzt beim Überschreiten der Bremsdruckschwelle

Weiterführende Informationen im Lastenheft spezifiziert und in der entsprechenden Fachabteilung zu erfragen.
";
CM_ SG_ 258 ESP_Fahrer_tritt_ZBR_Schw "Rückmeldung des ESP an AWV, ob der Fahrer die aktuell gültige ZBR-Schwelle übertritt";
CM_ SG_ 258 ESP_FStatus_Anfahrhilfe "Bei gesetztem Bit steht die Funktion Berganfahrassistent (Hillhold) nicht zur Verfügung";
CM_ SG_ 258 ESP_Gierrate "Winkelgeschwindigkeit um die z-Achse, ESP_VZ_Gierrate & ESP_QBit_Gierrate beachten !!!

MLB: gemessener Wert
tatsächliche Auflösung Bosch ESP: 0,27 Grad/s

Ab AU64x Auflösung wie die tatsächliche Skalierung 0,01. Im AU64x und AU57x wird bei ESP-Absch";
CM_ SG_ 258 ESP_HBA_aktiv "Verwendung/Bedienung ab D4
Signal gibt an, ob der hydraulische Bremsassistent im Regler aktiviert wurde

Im MQB wird das Signal nicht unterstützt!

";
CM_ SG_ 258 ESP_HBA_Empfindlichkeit "Signal gibt die aktuell gültige Auslöseempfindlichkeit des Hydraulischen Bremsassistenten an";
CM_ SG_ 258 ESP_HDC_aktiv "MQB und AU57x Allroad: Mit diesem Statusbit wird eine gerade aktive Regelung des Bergabfahrassistenten (Hill Descent Control) signalisiert.";
CM_ SG_ 258 ESP_HDC_Standby "Verwendung/Bedienung im MQB und AU57x Allroad:
Flag wird vom ESP gesetzt, wenn über den HDC-Taster die HDC-Funktion eingeschalten wurde";
CM_ SG_ 258 ESP_Konsistenz_ACC_Botschaft "Rückmeldung zum Sender der Verzögerungsanforderung ACC bezüglich Prüfung CHK/CRC, BZ und langer Timeout. Wird auch gesetzt bei einer Verzögerungsanforderung größer als eine applizierbare Schwelle.

Im D4/C7: Botschaft ACC_05
Im MQB: Botschaft ACC_07";
CM_ SG_ 258 ESP_Konsistenz_AWV2 "Rückmeldung zum Sender einer AWV-Anforderung (ACC-Steuergerät) bezüglich Prüfung der Checksumme, des Botschaftszählers, des langen Timeout und DLC.
";
CM_ SG_ 258 ESP_Konsistenz_TSK "Rückmeldung zum Sender einer Verzögerungsanforderung (Triebstrangskoordinator) bezüglich Prüfung der Checksumme, des Botschaftszählers, des langen Timeout und DLC. Wird auch gesetzt bei Verzögerungsanforderung größer einer applizierbaren Schwelle.
";
CM_ SG_ 258 ESP_Laengsbeschl "Beschleunigungswert in x-Achse

MLB: Im AU64x und AU57x erfolgt die Bereitstellung der Sensorwerte durch SARA-SG! Im AU64x und AU57x wird bei ESP-Abschaltung durch modellgestützte Überwachung das Signal weiterhin ausgegeben.

MQB: reines ABS schickt 0";
CM_ SG_ 258 ESP_Lenkeingriff_ADS "Im Falle eines fahrzeugstabilisierenden Lenkeingriffs des ADS-Systems soll ACC/GRA deaktiviert werden.

Im MQB wird dieses Signal nicht unterstützt!";
CM_ SG_ 258 ESP_Notbremsanzeige "ABS/ASR oder ESP hat Notbremssituation erkannt.
Weiterführende Informationen im Lastenheft spezifiziert und in der entsprechenden Fachabteilung zu erfragen.

";
CM_ SG_ 258 ESP_PLA_Abbruch "Wenn der Bremseingriff abgebrochen wurde, wird in diesem Signal der Grund des Abbruchs dargestellt.
Dies ist nur gültig, wenn der Status ESP_Status_ESP_PLA = '0xA' ist.";
CM_ SG_ 258 ESP_Prefill_ausgeloest "MLB: Verwendung/Bedienung ab D4
zeigt, ob die Funktion Prefill (aufgrund Fahrpedalgradient) ausgelöst wird; zeigt keinen Funktionszustand bezüglich Fehlerstilllegung

MQB: Wird gesetzt bei jeder Art von aktivem Prefill";
CM_ SG_ 258 ESP_QBit_Bremsdruck "QBit des Bremsdrucks. Gesetzt bei Ersatzwert, Init oder Fehler.";
CM_ SG_ 258 ESP_QBit_Fahrer_bremst "Gültigkeit der Bremsdruckschwelleninformation des Signals ESP_Fahrer_bremst vom ESP SG
0x1 = Druckschwelleninformation kann noch nicht oder aufgrund eines Fehlers nicht ausgegeben werden
";
CM_ SG_ 258 ESP_QBit_Gierrate "QBit der Gierrate. Gesetzt bei Ersatzwert, Init oder Fehler. 
";
CM_ SG_ 258 ESP_QBit_Laengsbeschl "QBit der Längsbeschleunigung. Gesetzt bei Ersatzwert, Init oder Fehler. 
";
CM_ SG_ 258 ESP_QBit_Querb "QBit der Querbeschleunigung. Gesetzt bei Ersatzwert, Init oder Fehler. ";
CM_ SG_ 258 ESP_QBit_v_ref "QBit der Referenzgeschwindigkeit ESP_v_ref. Gesetzt bei Ersatzwert, Init oder Fehler.
Detailinformationen zu dem Signal sind dem Lastenheft 'Signalexport - Funktionale Anforderungen an ESP' zu entnehmen - Signal ESP_St_v_fzg_ref";
CM_ SG_ 258 ESP_Querbeschleunigung "Beschleunigungswert in y-Achse

MLB: Gemessener Wert
0xFF = Fehler (wie bereits im Wertebereich spezifizert)
Bei ESP-Abschaltung durch modellgestützte Überwachung wird das Signal weiterhin ausgegeben.
Im AU64x und AU57x erfolgt die Bereitstellung der";
CM_ SG_ 258 ESP_Rueckwaertsfahrt_erkannt "nur bei AU57x und AU416 sowie Audi B8PA
Info, ob Rückwärtsfahrt über internen Algorithmus sicher erkannt

Im MQB wird das Signal nicht unterstützt!";
CM_ SG_ 258 ESP_Schwelle_Unterdruck "Verwendung im MQB für HBV-Projekte oder wenn für St/St ein Unterdrucksensor verbaut ist";
CM_ SG_ 258 ESP_SpannungsAnf "Die Rekuperation kann mit der Anforderung einer höheren Spannung eingeschränkt werden.";
CM_ SG_ 258 ESP_StartStopp_Info "Stopp-Freigabe und Start-Anforderung an den Start-Stopp-Koordinator";
CM_ SG_ 258 ESP_Status_Anfahrhilfe "Funktionsstatus des Berganfahrassistenten
MQB: Auswertung im Getriebe zwecks Standabkopplung";
CM_ SG_ 258 ESP_Status_Bremsdruck "MLB: Bei gesetztem Bit liegt p > ca. 2 bar an, hervorgerufen durch Fahrer, ASR, FZR, ECD, Bremsregler ... bei Abfall des Bits ist p < X bar, bei aktivem ECD-Eingriff Ende des Eingriffs 

Weiterführende Informationen im Lastenheft spezifiziert und in der";
CM_ SG_ 258 ESP_Status_Bremsentemp "ECD-Bremsscheibentemperaturmodell. Rückmeldung für Sender einer ECD Verzögerungsanforderung, ohne Fehlereintrag im ESP";
CM_ SG_ 258 ESP_Status_Bremsentemp_02 "Bremsscheibentemperaturmodell. Rückmeldung für Sender einer Verzögerungsanforderung";
CM_ SG_ 258 ESP_Status_ESP_PLA "Zustand der Statusmaschine der Bremse für die korrespondierende Statusmaschine in dem PLA-SG";
CM_ SG_ 258 ESP_Stillstandsphase_erschoepft "Rückmeldung vom ESP, dass eine angefordertes sicheres Halten im Stillstand nicht mehr länger möglich ist.";
CM_ SG_ 258 ESP_Systemstatus_03 "ESC-Status für Datenablage im EDR";
CM_ SG_ 258 ESP_Tuerkontakt_Fahrertuer "Logischer Pegel der HW-Leitung zum Türkontaktschalter im ESP-SG.
0 > Schalter geschlossen
1 > Schalter offen

Ungefilterter und unplausibilisierter Status der HW-Leitung vom Fahrertür-Türkontaktschalter zum ESP.
Redundanz für Systemsicherheit notwend";
CM_ SG_ 258 ESP_v_ref "MLBevo:
Signal wird nur von einem BOSCH ESP System zur Verfügung gestellt. Exklusives Signal vom BOSCH ESP zum BOSCH Airbag für ROSEII Funktion und für Fahrwerkregelsysteme. 
Verwendung nur nach vorheriger Abstimmung mit den verantwortlichen EF Fachbere";
CM_ SG_ 258 ESP_v_ref_Fahrtrichtung "Signal stellt die Informationen über die Fahrtrichtung des Fahrzeuges dar. Sie wird als Vorzeichen der Referenzgeschwindigkeit ESP_v_ref interpretiert und basiert auf den Drehrichtungen der Räder.
Detailinformationen zu dem Signal sind dem Lastenheft 'Si";
CM_ SG_ 258 ESP_Verz_EPB_aktiv "Bei gesetztem Bit wird die Verzögerungsanforderung von EPB umgesetzt.";
CM_ SG_ 258 ESP_Verz_TSK_aktiv "Rückmeldeinformation an den Triebsstrangkoordinator/ACC, dass die ECD-Verzögerungsanforderung aktuell umgesetzt wird";
CM_ SG_ 258 ESP_Verzoeg_EPB_verf "Bei gesetztem Bit ist der Verzögerungsregeler für EPB verfügbar.";
CM_ SG_ 258 ESP_VZ_Gierrate "Vorzeichen der Gierrate";
CM_ SG_ 258 ESP_ZT_Rueckk_Umsetz "Das Signal dient als Rückmeldung zum ACC, dass eine angeforderte Zielbremsung/Teilbremsung durchgeführt wird. Die positive Rückmeldung löst u.a. eine entsprechende Fahrerinformation im Kombiinstrument aus";
CM_ SG_ 258 SOK_ESC_50_Signatur "Signatur im Rahmen der durch SOK geschützten Broadcast-Kommunikation
Geschützte Funktionen: Airbag-Funktionen, EML, versch. Bremsfunktionen
Geschützte Botschaft: ESC_50";

CM_ SG_ 252 ESC_51_BZ "4bit Botschaftszähler, wird mit jeder Sendebotschaft inkrementiert";
CM_ SG_ 252 ESC_51_CRC "Für MLB:
Berechnung siehe Lastenheft 'Kommunikationsabsicherung für FlexRay und CAN'
Ab MQB und MLBevo:
Berechnung siehe Lastenheft 'End-to-End Kommunikationsabsicherung'

Endwerte siehe Begleitdokument 'S-PDU Kennungsfolgen'";
CM_ SG_ 252 ESC_Achsdrehzahl_Max "Limit Achsdrehzahl für die Primärachse";
CM_ SG_ 252 ESC_Achsdrehzahl_Max_sek "Limit Achsdrehzahl für die Sekundärachse";
CM_ SG_ 252 ESC_Achsdrehzahl_Min "Limit Achsdrehzahl für die Primärachse";
CM_ SG_ 252 ESC_Achsdrehzahl_Min_sek "Limit Achsdrehzahl für die Sekundärachse";
CM_ SG_ 252 ESC_aktBR_Modus_02 "Kontext des Signals ESC_aktBr_Modus_02:
0: AktivBremsung per eBKV nicht aktiv
1: ESC fordert eine schnelle Initialisierung vom eBKV beim Wecken
2: Aktivbremsung per eBKV aktiv
3: Aktivbremsung per eBKV aktiv ohne Begrenzung durch 'Fahrer bremst' Erken";
CM_ SG_ 252 ESC_aktBr_Volumenstrom "Volumenstromvorgabe für Aktivbremsung per eBKV,
Kontext des Volumenstroms wird im Signal ESC_aktBr_Modus übertragen";
CM_ SG_ 252 ESC_Allrad_Anteil_max_sek "Maximaler prozentualer Anteil der sekundären Antriebsachse am Gesamtmoment - wird soweit dies durch die Leistungsfähigkeit der Achse möglich ist eingehalten";
CM_ SG_ 252 ESC_Allrad_Anteil_min_sek "Minimaler prozentualer Anteil der sekundären Antriebsachse am Gesamtmoment - wird soweit dies durch die Leistungsfähigkeit der Achse möglich ist eingehalten";
CM_ SG_ 252 ESC_Allradverteilung_aktiv "Allradumverteilung aus BRS aktiv und vom ASG umzusetzen";
CM_ SG_ 252 ESC_Anf_Mindestreku "Bei Wert == 1 soll durch den Antrieb eine im Projekt definierte Mindestrekuperationsleistung des E-Antriebs zur Anforderung durch das Bremssystem schnellst möglich frei gegeben werden. Dies dient zur Entlastung der Reibbremse.";
CM_ SG_ 252 ESC_Blending_Solldruck "Zieldruck während Rekuperation. Das Signal ist spezifisch aufbereitet und wird für die Pedakraftkompensation im eBKV genutzt.

MQB/MQB2020: Wird nur von einem blendfähigen ESC unterstützt, wie es in mHEV und pHEV Fahrzeugen eingesetzt wird.";
CM_ SG_ 252 ESC_Bremsdruck_02 "Rohwert des Bremsdrucks
Für Fahrzeuge mit elektrischem Bremskraftverstärker gilt: Aus dem Signal ESC_Bremsdruck_02 lässt sich kein Fahrerbremswunsch ableiten. Das Signal bildet lediglich den hydraulischen Anteil der Fahrzeugverzögerung ab. Der Rohwert de";
CM_ SG_ 252 ESC_Bremsdruck_Modell "Virtueller, aus dem Wert 'EBKV_Stangenweg_Fahrerwunsch' berechneter Hauptzylinderdruck. Während einer hydraulischen Bremsung entspricht dieser Druck nahezu dem 'ESC_Bremsdruck_02'. Während einer Bremsung mit Rekuperation ist es ein berechneter Wert, der d";
CM_ SG_ 252 ESC_EBKV_Kraftblending_Modus "Freigabe der Pedalkraftkompensation (Funktion des eBKV)

MQB/MQB2020: Wird nur von einem blendfähigen ESC unterstützt, wie es in mHEV und pHEV Fahrzeugen eingesetzt wird.";
CM_ SG_ 252 ESC_GMV_aktiv "Rueckmeldung Giermomentvorgabe aktiv";
CM_ SG_ 252 ESC_GMV_nicht_verfuegbar "Rueckmeldung Giermomentvorgabe nicht verfuegbar";
CM_ SG_ 252 ESC_MomRad_Eingriff "Eingriffs-Momenten-Anforderung vom ESC an das ASG für die primäre Achse; auf Bezugsebene „Moment am Rad; Faktor in TS_Faktor_Radmomente beachten!";
CM_ SG_ 252 ESC_MomRad_Eingriff_sek "Eingriffs-Momenten-Anforderung vom ESC an das ASG für die sekundäre Achse; auf Bezugsebene „Moment am Rad; Faktor in TS_Faktor_Radmomente beachten! Signal ist nur relevant für mechanisch getrennte Achsantriebe (z. B. equattro)";
CM_ SG_ 252 ESC_QBit_Bremsdruck_02 "QBit des ESC_Bremsdruck_02. Gesetzt bei Ersatzwert, Init oder Fehler.";
CM_ SG_ 252 ESC_Status_Eingriff "Das Signal qualifiziert „ESC_MomRad_Eingriff“ und gibt an, wie dieses Signal umzusetzen ist";
CM_ SG_ 252 ESC_Status_Eingriff_sek "Das Signal qualifiziert „ESC_MomRad_Eingriff_sek“ und gibt an, wie dieses Signal umzusetzen ist";
CM_ SG_ 252 ESC_Status_vRef_Stuetzeingriff "Das Signal qualifiziert eine Momentenreduzierung an der Hinterachse zur Stützung der ESC Referenzgeschwindigkeit. Die Reduzierung erfolgt über die Signale ESC_MomRad_Eingriff bzw ESC_MomRad_Eingriff_sek";
CM_ SG_ 252 ESP_FDR_uebersteuern "Modularer Fahrdynamikregler erkennt Übersteuern.
Bei Integration modularer Fahrdynamikregler in ESC MEB: Verwendung durch eAllradfunktion in MSG.";
CM_ SG_ 252 ESP_FDR_untersteuern "Modularer Fahrdynamikregler erkennt Untersteuern.
Bei Integration modularer Fahrdynamikregler in ESC MEB: Verwendung durch eAllradfunktion in MSG.";
CM_ SG_ 252 ESP_FZR_uebersteuern "Fahrzeug erkennt uebersteuern";
CM_ SG_ 252 ESP_FZR_untersteuern "Fahrzeug erkennt untersteuern";
CM_ SG_ 252 ESP_HL_Bremsmoment "Bremsmoment HL
Ausgabe nach LAH: Ausgabe der internen Radbremsmomente / Radbremsdrücke / durch das ESP";
CM_ SG_ 252 ESP_HL_Radgeschw_02 "Radgeschwindigkeit hinten links";
CM_ SG_ 252 ESP_HR_Bremsmoment "Bremsmoment HR
Ausgabe nach LAH: Ausgabe der internen Radbremsmomente / Radbremsdrücke / durch das ESP";
CM_ SG_ 252 ESP_HR_Radgeschw_02 "Radgeschwindigkeit hinten rechts";
CM_ SG_ 252 ESP_VL_Bremsmoment "Bremsmoment VL
Ausgabe nach LAH: Ausgabe der internen Radbremsmomente / Radbremsdrücke / durch das ESP";
CM_ SG_ 252 ESP_VL_Radgeschw_02 "Radgeschwindigkeit vorne links";
CM_ SG_ 252 ESP_VR_Bremsmoment "Bremsmoment VR
Ausgabe nach LAH: Ausgabe der internen Radbremsmomente / Radbremsdrücke / durch das ESP";
CM_ SG_ 252 ESP_VR_Radgeschw_02 "Radgeschwindigkeit vorne rechts";
CM_ SG_ 252 FDR_Allradverteilung_aktiv "Allradumverteilung aus FDR aktiv und vom MSG umzusetzen";
CM_ SG_ 252 FDR_Anf_Allradbetrieb "Anforderung des Fahrdynamikreglers an MSG zur Aktivierung des Allradbetriebs.";
CM_ SG_ 252 SOK_ESC_51_Signatur "Signatur im Rahmen des SOK Authentic-Broadcast-Protokolls.

Geschützte Funktion: Lenkunterstützung
Geschützte Botschaft: ESC_51";
CM_ SG_ 252 TSMomBegrenzung "In MLBevo Faktor in TS_Faktor_Radmomente beachten!

Begrenzung des verzögernd wirkenden Antriebsstrangsollmomentenanteil auf Summenradebene";

CM_ SG_ 278 ESP_10_BZ "Botschaftszähler

Wird im Projekt D4 und D4Hybrid nicht verwendet!  Wird im D4 PA verwendet";
CM_ SG_ 278 ESP_10_CRC "Für MLB:
'Berechnung siehe Lastenheft 'Kommunikationsabsicherung für FlexRay und CAN''

Ab MQB und MLBevo:
'Berechnung siehe Lastenheft 'End-to-End Kommunikationsabsicherung''

Endwerte siehe Begleitdokument 'S-PDU Kennungsfolgen'

Wird im Projekt";
CM_ SG_ 278 ESP_HL_Fahrtrichtung "Drehrichtung Rad HL

Weiterführende Informationen im Lastenheft spezifiziert und in der entsprechenden Fachabteilung zu erfragen.

Wird im Projekt D4 und D4Hybrid nicht verwendet!  Wird im D4 PA verwendet";
CM_ SG_ 278 ESP_HR_Fahrtrichtung "Drehrichtung Rad HR

Weiterführende Informationen im Lastenheft spezifiziert und in der entsprechenden Fachabteilung zu erfragen.

Wird im Projekt D4 und D4Hybrid nicht verwendet!  Wird im D4 PA verwendet";
CM_ SG_ 278 ESP_QBit_Wegimpuls_HL "Qualifizierungsbit Wegimpulszähler HL

Wird im Projekt D4 und D4Hybrid nicht verwendet!  Wird im D4 PA verwendet";
CM_ SG_ 278 ESP_QBit_Wegimpuls_HR "Qualifizierungsbit Wegimpulszähler HR

Wird im Projekt D4 und D4Hybrid nicht verwendet!  Wird im D4 PA verwendet";
CM_ SG_ 278 ESP_QBit_Wegimpuls_VL "Qualifizierungsbit Wegimpulszähler VL

Wird im Projekt D4 und D4Hybrid nicht verwendet!  Wird im D4 PA verwendet";
CM_ SG_ 278 ESP_QBit_Wegimpuls_VR "Qualifizierungsbit Wegimpulszähler VR

Wird im Projekt D4 und D4Hybrid nicht verwendet!  Wird im D4 PA verwendet";
CM_ SG_ 278 ESP_VL_Fahrtrichtung "Drehrichtung Rad VL

Weiterführende Informationen im Lastenheft spezifiziert und in der entsprechenden Fachabteilung zu erfragen.

Wird im Projekt D4 und D4Hybrid nicht verwendet!  Wird im D4 PA verwendet";
CM_ SG_ 278 ESP_VR_Fahrtrichtung "Drehrichtung Rad VR

Weiterführende Informationen im Lastenheft spezifiziert und in der entsprechenden Fachabteilung zu erfragen.

Wird im Projekt D4 und D4Hybrid nicht verwendet!  Wird im D4 PA verwendet";
CM_ SG_ 278 ESP_Wegimpuls_HL "Wegimpulszähler HL.
Anzahl der Wegimpulse Hinterrad links (steigende und fallende Flanke)
Zähler läuft grundsätzlich vorwärts, auch bei Rückwärtsfahrt.
Nach SG-Reset ist immer, ohne Ausnahme, 1mal der Init Wert 1021 zu senden.

Wird im Projekt D4 und";
CM_ SG_ 278 ESP_Wegimpuls_HR "Wegimpulszähler HR.
Anzahl der Wegimpulse Hinterrad rechts (steigende und fallende Flanke)
Zähler läuft grundsätzlich vorwärts, auch bei Rückwärtsfahrt.
Nach SG-Reset ist immer, ohne Ausnahme, 1mal der Init Wert 1021 zu senden.

Wird im Projekt D4 un";
CM_ SG_ 278 ESP_Wegimpuls_VL "Wegimpulszähler VL.
Anzahl der Wegimpulse Vorderrad links (steigende und fallende Flanke)
Zähler läuft grundsätzlich vorwärts, auch bei Rückwärtsfahrt.
Nach SG-Reset ist immer, ohne Ausnahme, 1mal der Init Wert 1021 zu senden.

Wird im Projekt D4 und";
CM_ SG_ 278 ESP_Wegimpuls_VR "Wegimpulszähler VR.
Anzahl der Wegimpulse Vorderrad rechts (steigende und fallende Flanke)
Zähler läuft grundsätzlich vorwärts, auch bei Rückwärtsfahrt.
Nach SG-Reset ist immer, ohne Ausnahme, 1mal der Init Wert 1021 zu senden.

Wird im Projekt D4 un";

CM_ SG_ 1629 BR_QBit_Reifenumfang "Gesetzt bei Ersatzwert, Init oder Fehler.";
CM_ SG_ 1629 BR_Reifenumfang "Mittlerer Radumfang gerechnet in Millimeter.
Von der Bremse plausibilisierter Wert (Kopie von KBI_Reifenumfang wenn dieser plausibel) oder Ersatzwert aus Bremse wenn KBI_Reifenumfang unplausibel. Bitte das QBit beachten!

Im MEB wird das Signal KBI_Rei";
CM_ SG_ 1629 BR_Systemart "Identifikation des verbauten Bremssystems

Dient dem Kombi zur Plausibilisierung";
CM_ SG_ 1629 ESP_20_CRC "Für MLB:
'Berechnung siehe Lastenheft 'Kommunikationsabsicherung für FlexRay und CAN''

Ab MQB und MLBevo:
'Berechnung siehe Lastenheft 'End-to-End Kommunikationsabsicherung''

Endwerte siehe Begleitdokument 'S-PDU Kennungsfolgen'";
CM_ SG_ 1629 ESP_Charisma_FahrPr "MLBevo: Aktuelles Fahrprogramm des Charisma-Teilnehmers (siehe Systemlastenheft Drive Select)
MQB: Istwert der Kennlinie (siehe Systemlastenheft MQB FPA)";
CM_ SG_ 1629 ESP_Charisma_Status "Systemstatus des Charismateilnehmers

Wert 0x3 ist nur für Fahrzeuge ab MQB relevant";
CM_ SG_ 1629 ESP_Dachrelingsensor "Erkennung auf Verbau des Dachrelingsensors und Dachquerträger.";
CM_ SG_ 1629 ESP_SpannungsAnf_02 "Forderung des ESP-SG's zur Spannungsanhebung.";
CM_ SG_ 1629 ESP_Stoppverbot_Anz_01 "Dieses Signal gibt die detaillierte Begründung für ein Stoppverbot vom Bremsensteuergerät an.";
CM_ SG_ 1629 ESP_Stoppverbot_Anz_02 "Dieses Signal gibt die detaillierte Begründung für ein Stoppverbot vom Bremsensteuergerät an.";
CM_ SG_ 1629 ESP_Stoppverbot_Anz_03 "Dieses Signal gibt die detaillierte Begründung für ein Stoppverbot vom Bremsensteuergerät an.";
CM_ SG_ 1629 ESP_Stoppverbot_Anz_04 "Dieses Signal gibt die detaillierte Begründung für ein Stoppverbot vom Bremsensteuergerät an.";
CM_ SG_ 1629 ESP_Stoppverbot_Anz_05 "Dieses Signal gibt die detaillierte Begründung für ein Stoppverbot vom Bremsensteuergerät an.";
CM_ SG_ 1629 ESP_Stoppverbot_Anz_06 "Dieses Signal gibt die detaillierte Begründung für ein Stoppverbot vom Bremsensteuergerät an.";
CM_ SG_ 1629 ESP_Stoppverbot_Anz_07 "Dieses Signal gibt die detaillierte Begründung für ein Stoppverbot vom Bremsensteuergerät an.";
CM_ SG_ 1629 ESP_Stoppverbot_Anz_08 "Dieses Signal gibt die detaillierte Begründung für ein Stoppverbot vom Bremsensteuergerät an.";
CM_ SG_ 1629 ESP_Stoppverbot_Anz_Std "Dieses Signal gibt die detaillierte Begründung für ein Stoppverbot vom Bremsensteuergerät an.";
CM_ SG_ 1629 ESP_Wiederstart_Anz_01 "Dieses Signal gibt die detaillierte Begründung für einen Wiederstart vom Bremsensteuergerät an. ";
CM_ SG_ 1629 ESP_Wiederstart_Anz_02 "Dieses Signal gibt die detaillierte Begründung für einen Wiederstart vom Bremsensteuergerät an. ";
CM_ SG_ 1629 ESP_Wiederstart_Anz_03 "Dieses Signal gibt die detaillierte Begründung für einen Wiederstart vom Bremsensteuergerät an. ";
CM_ SG_ 1629 ESP_Wiederstart_Anz_04 "Dieses Signal gibt die detaillierte Begründung für einen Wiederstart vom Bremsensteuergerät an.";
CM_ SG_ 1629 ESP_Zaehnezahl "Konstanter Wert der Zähnezahl des verwendeten Impulsrades wird ausgegeben, jeder Empfänger der Wegimpulse muss die Zähnezahl einlesen, um eine volle Umdrehung des Rades zu erkennen. 

Weiterführende Informationen im Lastenheft spezifiziert und in der en";
CM_ SG_ 1629 HDC_Charisma_FahrPr "MLBevo: Aktuelles Fahrprogramm des Charisma-Teilnehmers (siehe Systemlastenheft Drive Select)
MQB: Istwert der Kennlinie (siehe Systemlastenheft MQB FPA)";
CM_ SG_ 1629 HDC_Charisma_Status "Systemstatus des Charismateilnehmers

Wert 0x3 ist nur für Fahrzeuge ab MQB relevant";

CM_ SG_ 253 ABS_Bremsung "Antiblockiersystem, Bit zeigt auch Druckabbau an (z.B. ESP hat zuviel Druck aufgebaut oder ungebremste Regelung auf Bahnübergang)
Weiterführende Informationen im Lastenheft spezifiziert und in der entsprechenden Fachabteilung zu erfragen.";
CM_ SG_ 253 ASR_Anf "MLB: Die Momentenanforderung 'ASR_MSR_Moment_schnell' und 'ASR_Moment_langsam' sind auszuführen
MQB: Die Momentenanforderung 'BR_Eingriffsmoment' ist auszuführen";
CM_ SG_ 253 ASR_Schalteingriff "Wunsch an das Getriebe während einer ASR Regelung

MLB: Es wird nur 0x0 und 0x1 genutzt

";
CM_ SG_ 253 ASR_Tastung_passiv "ASR deaktiviert oder Schwellen geändert (projektabhängig)
Weiterführende Informationen im Lastenheft spezifiziert und in der entsprechenden Fachabteilung zu erfragen.
";
CM_ SG_ 253 BR_Eingriffsmoment "Einheitenloser Wert! Faktor in MO_Faktor_Momente_02 in Motor_Code_01 beachten!
Schnelle reduzierende (ASR) oder erhöhende (MSR) Momentanforderung an den Motor.";
CM_ SG_ 253 EBV_Eingriff "Elektronische Bremskraftverteilung, aktueller Eingriff (Druckhalten, Druckabbau)

Im MLB: kein ABS / ESP-Eingriff ???";
CM_ SG_ 253 EDS_Eingriff "Elektronische Differentialsperre";
CM_ SG_ 253 ESC_Reku_Freigabe "Mit diesem Bit wird die Rekuperation im Motorsteuergerät erlaubt. Bei Ausfall ESC wird Rekuperation nicht freigegeben.

MQB/MQB2020: Wird nur von einem blendfähigen ESC unterstützt, wie es in mHEV und pHEV Fahrzeugen eingesetzt wird.";
CM_ SG_ 253 ESC_v_Signal_Qualifier_High_Low "Das Qualifizerungssignal ESC_v_Signal_Qualifier_High_Low gibt eine Information über die Güte der vom Bremsregelsystem ausgegebenen Geschwindigkeitsinformation 'mittlere Geschwindigkeit', wobei Vertrauensbereiche für das ausgegebene Geschwindigkeitssignal ";
CM_ SG_ 253 ESP_21_CRC "Für MLB:
'Berechnung siehe Lastenheft 'Kommunikationsabsicherung für FlexRay und CAN''

Ab MQB und MLBevo:
'Berechnung siehe Lastenheft 'End-to-End Kommunikationsabsicherung''

Endwerte siehe Begleitdokument 'S-PDU Kennungsfolgen'";
CM_ SG_ 253 ESP_Anhaltevorgang_ACC_aktiv "Zeigt an, ob ACC-Anhaltevorgang aktiv";
CM_ SG_ 253 ESP_ASP "MLB: Anhaenger-Stabilisierungs-Programm
MQB: Gespannstabilisierung";
CM_ SG_ 253 ESP_AWV3_Brems_aktiv "Teil-, Ziel- oder Notbremsung wird im ESP für AWV3 umgesetzt (das MSG nutzt diese Info für den Abwurf der GRA-Regelung).";
CM_ SG_ 253 ESP_Diagnose "MLB: Nach Diagnoseende wird ein SW-Reset ausgelöst welcher einen Kommunikatiosausfall für max. 150ms verursacht. Dies ist bei SG mit verschärfter Timeoutüberwachung (nicht nach Konzern-LH) zu beachten.

MQB: Weiterführende Informationen im Lastenheft sp";
CM_ SG_ 253 ESP_Eingriff "Eingriff des Fahrdynamikreglers";
CM_ SG_ 253 ESP_Haltebestaetigung "Rückmeldung vom ESP-SG, dass das Fahrzeug aufgrund einer externen Bremsanforderung (z. B. ACC, PLA, ANB, o. ä.) abgebremst wurde und im Stillstand gehalten wird.";
CM_ SG_ 253 ESP_MKB_Abbruch_Geschw "Im Falle einer Multikollisionsbremsung teilt das ESP den Abbruch der MKB aufgrund der unteren Geschwindigkeitsschwelle mit.";
CM_ SG_ 253 ESP_PLA_Bremseingriff "Signalisierung des aktiven Bremseingriffes des ESP aufgrund einer Bremsanforderung vom PLA.";
CM_ SG_ 253 ESP_QBit_v_Signal "Geschwindigkeit wird vom ABS/ASR oder ESP aus Ersatzwerten errechnet, wenn Bit gesetzt ist. Güte des Signals ist verändert.";
CM_ SG_ 253 ESP_Systemstatus "Fehler steht für Stillegung ESP mit Fehlereintrag.

MLB: Flag wird bei Unterspannung im Stand bis einmalig 6km/h (AU48x) oder 10 km/h (AU641, AU57x) überschritten nicht gesetzt (Ausblendung Startvorgang)
Im AU64x, AU57x gilt ESP D4 Funktionsanforderung";
CM_ SG_ 253 ESP_Tastung_passiv "ESP deaktiviert oder Schwellen geändert (projektabhängig)
Weiterführende Informationen im Lastenheft spezifiziert und in der entsprechenden Fachabteilung zu erfragen.";
CM_ SG_ 253 ESP_v_Signal "Geschwindigkeitssignal vom ABS/ASR oder ESP. Mittelwert der angetriebenen Räder.
Bei MSR oder ABS Eingriffen wird die ABS-Referenzgeschwindigkeit für >= 200ms eingespiegelt (Zeit wird mit Aktiv-Flanke der Funktionsbits getriggert)

MQB: Bei Frontantrie";
CM_ SG_ 253 ESP_Vorsteuerung "zur Unterscheidung zwischen ESP-Vorsteuermaßnahmen und ESP-Regeleingriffen";
CM_ SG_ 253 MSR_Anf "MLB: Die Momentenanforderung 'ASR_MSR_Moment_schnell' ist auszuführen.
MQB: Die Momentenanforderung 'BR_Eingriffsmoment' ist auszuführen";
CM_ SG_ 253 OBD_Schlechtweg "Für Ausblendung der Zündaussetzererkennung im Motorsteuergerät (Otto). Bit wird gesetzt, wenn Rad-Drehbeschleunigung im ESP > Grenzwert ist. Vorteil gegenüber Radgeschwindigkeiten, dass ESP alle 2 ms dynamisch die Rad-Drehbeschleunigung errechnet und dem ";

CM_ SG_ 2527679740 KBI_aktive_Laengsfunktion_02 "Auswahl, der vom Fahrer gewünschten Laengsregelfunktion";
CM_ SG_ 2527679740 KBI_Anzeigestatus_ACC "Status der ACC-Anzeige im nicht permanenten Displaybereich";
CM_ SG_ 2527679740 KBI_Anzeigestatus_GRA "Anzeigestatus der GRA High Wunschgeschwindigkeitsanzeige im Kombiinstrument.
Bei VW bedeutet 'nicht vorhanden' GRA-low fähig (LED immer verbaut).
0 = nicht vorhanden
1 = Wunschgeschwindigkeits-Anzeigemöglichkeit vorhanden
2 = reserviert
3 = Fehler (B";
CM_ SG_ 2527679740 KBI_Anzeigestatus_LIM "Anzeigestatus der Speedlimiter Wunschgeschwindigkeitsanzeige im Kombiinstrument (permanenter Anzeigebereich)
0 = nicht vorhanden
1 = Wunschgeschwindigkeits-Anzeigemöglichkeit vorhanden
2 = reserviert
3 = Fehler (Botschaftsüberwachung, Timeout, Akustik";
CM_ SG_ 2527679740 KBI_Fehler_Anzeige_ACC "Rückmeldung an ACC, dass mindestens eine der ACC-relevanten Anzeigen -rote Fahrerübernahme, Mitteldisplay, Gong - fehlerhaft sind.";
CM_ SG_ 2527679740 KBI_Konsistenz_ACC "Rückmeldung an ACC, dass die Botschaften zur Ansteuerung von Anzeigen nicht bzw. nicht konsistent empfangen wurden (Timeout-, BZ-, CHK- und DLC-Fehler)                                                                                                        ";

CM_ SG_ 1605 FLA_Abblendursache "FLA Abblendursache
(20ms Task)";
CM_ SG_ 1605 FLA_aktiv "FLA aktiv  (200ms Task)";
CM_ SG_ 1605 FLA_Aufblenden "FLA Aufblenden (20ms Task)";
CM_ SG_ 1605 FLA_Fernlicht_PWM "FLA PWM Vorgabe Fernlicht
(20ms Task)";
CM_ SG_ 1605 FLA_ISP_defekt "FLA defekt (Innenspiegelkamera oder Multifunktionskamera)
interner Fehler  (200ms Task)";
CM_ SG_ 1605 FLA_SAE_Mode "Rückmeldung an den Fahrer, über Wechsel in den SAE Modus --> wird nur für den amerikanischen Markt benötigt.";
CM_ SG_ 1605 FLA_Sensor_blockiert "FLA Sensor blockiert
Sichtbeeinträchtigung der Kamera  (200ms Task)";
CM_ SG_ 1605 ISP_EC_aktiv "Status Innenspiegel (EC-Spiegel)";
CM_ SG_ 1605 ISP_EC_Lichtwert_hinten "Innenspiegel: Lichtwert hinten
";
CM_ SG_ 1605 ISP_EC_Lichtwert_vorne "Innenspiegel: Lichtwert vorne
";
CM_ SG_ 1605 ISP_Himmelsrichtung "Himmelsrichtung Kompass im EC Spiegel
Wertebereich 0-29 (12°-Schritte, 0-348°)
";
CM_ SG_ 1605 ISP_Kompass_aktiv "Status Kompass Innenspiegel";
CM_ SG_ 1605 ISP_Taste_betaetigt "ISP Taste betätigt
(200ms Task)";

CM_ SG_ 2589283684 FoD_Anz_Funktionsabschaltung "Signal triggert Aufschaltung eines Popups, um dem Fahrer die Abschaltung einer Funktion zu melden.";
CM_ SG_ 2589283684 FoD_State_IPA_RPA "Function on Demand Activation State for IPA and RPA";
CM_ SG_ 2589283684 FoD_State_TopView_SideView_RVC "Function on Demand State for TopView and SideView and RearView";
CM_ SG_ 2589283684 FoD_State_TPA_rTPA "Function on Demand Activation State for TPA and rTPA from Function Master";
CM_ SG_ 2589283684 FoD_Transmission_Info "Mit dem Signal zeigt der FoD-Master allen FoD-Slaves den Beginn und das Ende eines Freischaltuebertragungszykluses (FS-ID-Zyklus) an.";
CM_ SG_ 2589283684 GRA_FoD_Status "Verortung des FOD-Slaves für die Funktion GRA erfolgt im Gateway. Signal übermittelt den FOD-Status an das MSG.";

CM_ SG_ 2549875543 FoD_ACC_Req_Data "FoD - Function On Demand
ISO-TP Datenkanal - FID2NA
Request Funktion 0x03 FoD-Master

FoD-Master an ACC/ FASFrontradar";

CM_ SG_ 2550006615 FoD_ACC_Resp_Data "FoD - Function On Demand
ISO-TP Datenkanal - FID2NA
Response Knoten 0x57 ACC/ FASFrontradar

ACC/FASFrontradar an FoD Master";

CM_ SG_ 2549875535 FoD_Kamera_Req_Data "FoD - Function On Demand
ISO-TP Datenkanal - FID2NA
Request Funktion 0x03 FoD-Master

FoD-Master an MFK";

CM_ SG_ 2550006607 FoD_Kamera_Resp_Data "FoD - Function On Demand
ISO-TP Datenkanal - FID2NA
Response Knoten 0x4F MFK

MFK an FoD Master";

CM_ SG_ 987 AAG_Anhaenger_abgesteckt "Anhaenger wurde bei Kl. 15 aus abgesteckt";
CM_ SG_ 987 AAG_Anhaenger_erkannt "Erkennung Anhaenger ";
CM_ SG_ 987 AAG_LED_aktiv "Dieses Signal sendet der Beleuchtungsart des Anhängers (LED oder Lampe)
Bei LED aktiv erfolgt kein Kaltüberwachung";
CM_ SG_ 987 BCM1_Aussen_Temp_ungef "ungefilterter Wert des Aussentemperatursensors
";
CM_ SG_ 987 BCM1_LDS_Stellung "Das Signal wird vom AFS / LWR Steuergerät empfangen und dient der Verifizierung der Lichtdrehschalterstellung. Intelligente Lichtfunktionen wie dyn. KL und gleitende Leuchtweite (GLW) nur bei LDS = 'AUTO'.";
CM_ SG_ 987 BCM1_MH_Schalter "Motorhaubenkontakt";
CM_ SG_ 987 BCM1_OBD_FStatus_ATemp "Fehlerstatus Umgebungstemperatursensor (OBD relevanter Sensor)
";
CM_ SG_ 987 BCM1_Rueckfahrlicht_Schalter "Rückfahrlichtschalter
ab MQB/ MLBevo: Die Ganginformation wird unentprellt übertragen, im AT-Getriebe wird evtl. kurzzeitig der R-Gang angezeigt. Eine Entprellung muß im Empfänger erfolgen (typisch 400ms).";
CM_ SG_ 987 BCM_Rueckfahrlicht_Anf "Anforderung Rückfahrlicht (Sollzustand). 
Das Signal wird entprellt (typisch 400ms) und bei KL15EIN gesendet. Das Signal ist unabhängig von der Position des Heckdeckels (kein Überhitzungsschutz).";
CM_ SG_ 987 BCM_Tankklappensteller_Fehler "Fehler: nicht Funktionalität des Tankklappenstellers";
CM_ SG_ 987 BH_Blinker_li "Blinkerhebel Richtung links";
CM_ SG_ 987 BH_Blinker_re "Blinkerhebel Richtung rechts";
CM_ SG_ 987 BH_Fernlicht "Betaetigung Fernlicht
";
CM_ SG_ 987 BH_Lichthupe "Betaetigung Lichthupe
";
CM_ SG_ 987 KL_Thermomanagement "Stufen des Thermomanagements;
Bei Klemme 15 AUS und erkannten Timeout zum Klimabedienteil (z.B. Klimabedienteil während des Motorsteuergeräte-Kommunikations-Nachlaufs bereits im NM-Zustand ¿Bus Sleep¿)
erfolgt keine Ansteuerung der Wasserpumpe durch die";
CM_ SG_ 987 VS_VD_entriegelt "Zustand des Verdeck entriegelt";
CM_ SG_ 987 VS_VD_offen_ver "Zustand des Verdecks verriegelt und offen";
CM_ SG_ 987 VS_VD_zu_ver "
";
CM_ SG_ 987 VS_Verdeck_Anf "Verdeckanforderung (Signalisierung der Bereitschaft zur Verdeckbetaetigung ueber Komfortfunktion)";
CM_ SG_ 987 Waschen_vorne_aktiv "Status: Waschen vorne aktiv";
CM_ SG_ 987 WFS_ID_Geb_autorisiert_in_Kl15 "Authorisierung des Schlüssels im aktiven Klemme-15-Zyklus";
CM_ SG_ 987 WFS_Klemmenfreigabe "Freigabe von der WFS zum Einschalten der Klemme 15 und Klemme S";
CM_ SG_ 987 WFS_Schluessel_Fahrberecht "Schlüsselnummer Fahrberechtigung
0 = ungueltig, xxxx = Schluessel-Nr.";
CM_ SG_ 987 Wischer_vorne_aktiv "Status: Wischer vorne";
CM_ SG_ 987 WWSs_01_alt "Veraltet Bit für die LIN-Botschaft WWSs_01.

Betroffene Signale:

Wischer_vorne_aktiv";
CM_ SG_ 987 ZV_BT_offen "gespiegeltes Bit BT_Tuer_geoeffnet TSG_BT_1 Botschaft";
CM_ SG_ 987 ZV_FT_offen "gespiegeltes Bit FT_Tuer_geoeffnet TSG_FT_1 Botschaft";
CM_ SG_ 987 ZV_HBFS_offen "gespiegeltes Bit HBFS_Tuer_geoeffnet TSG_HBFS_1 Botschaft";
CM_ SG_ 987 ZV_HD_offen "Status Heckdeckel
";
CM_ SG_ 987 ZV_HFS_offen "gespiegeltes Bit HFS_Tuer_geoeffnet TSG_HFS_1 Botschaft";
CM_ SG_ 987 ZV_Schluessel_Zugang "aktuelle Funkschlüsselnummer";
CM_ SG_ 987 ZV_Tankklappe_offen "Öffnungsstatus der Tankklappe";
CM_ SG_ 987 ZV_verriegelt_extern_soll "Sollzustand: Verriegelung Fahrzeug aussen
";
CM_ SG_ 987 ZV_verriegelt_soll "Fahrzeug Gesamtverriegelungsstatus Sollzustand für Ladestecker- und Ladeklappenverriegelung. ";

CM_ SG_ 988 ACC_18_alt "Veraltet-Bit";
CM_ SG_ 988 ACC_Status_ACC "'ACC OFF' bedeutet ACC-Hauptschalter ist 'Gerastet Aus

'ACC Reversibler Fehler' bedeutet, daß das ACC aktuell einen 
reversiblen Fehler im ACC-SG selbst oder in einem zum 
ACC-System gehörenden SG erkennt.

'ACC irreversibler Fehler' bedeutet, daß ";
CM_ SG_ 988 EPB_Status_02 "Erweiterung der Zustände um ein genaueres Bild des aktuellen Zustandes zu erhalten für weitergehende Funktionen ( Stillstandsmanager)
";
CM_ SG_ 988 ESP_50_alt "Veraltet-Bit";
CM_ SG_ 988 ESP_Rollenmodus_Deaktivieren "Zwang zum Abbruch des Rollenmodus mit anschließender ESP-Vollfunktion.
MQB: Zwang zum Abbruch des Rollenmodus in allen Funktionsteilnehmern (Empfänger) mit anschließender ESP-Vollfunktion (Sender).
Signal wird vom ESP dauerhaft mit gültigen Werten bedat";
CM_ SG_ 988 ESP_Status_Bremsentemp_02 "Bremsscheibentemperaturmodell. Rückmeldung für Sender einer Verzögerungsanforderung";
CM_ SG_ 988 GE_Fahrstufe "Fahrprogramm des Getriebes

Hinweis: Zwischenstellung '0x0' darf nur für Zustandswechsel P/R, R/N, N/D ausgegeben werden, nicht für D/S oder D/Tippgasse wegen Abschaltkriterium GRA/ACC";
CM_ SG_ 988 GE_Freilauf_Status "Freilauf-Status-Signal vom Frailauf-Master an aktive Freilauf-Teilnehmer. In diesem Signal zeigt der Freilauf-Master an, welchen aktuellen Status die Freilauf-Betriebsstrategie hat.";
CM_ SG_ 988 GE_Notlauf "AL/DL: Signalisiert wenn sich das Getriebe (bei DL ein Teilgetriebe) im Notlauf befindet.
VL: Wird gesetzt wenn kein Kraftschluss möglich ist.";
CM_ SG_ 988 GE_Sperr_Info_WFS "WFS-Sperrinformation";
CM_ SG_ 988 GE_Ursache_Fahrstufe_N "Zeigt an, warum Fahrstufe N angenommen wurde. So kann z.B. die Rollsicherung im Verlassenskonzept aktiv bleiben, wenn das Schalten nach N ohne Fahrerwunsch erfolgte (z.B. Fehlerreaktion).

ACHTUNG: Das Signal darf nur ausgewertet werden, wenn GE_Fahrstu";
CM_ SG_ 988 MKE_Stufe "Das Signal bildet die Müdigkeitsstufe im Kombi ab:
0 - deaktiviert
1 - nicht_verfügbar
2 - Stufe_1
3 - Stufe_2
4 - Stufe_3
5 - Stufe_4
6 - reserviert
7 - reserviert";
CM_ SG_ 988 MKE_Texte "Systemhinweis und Sicherheitshinweis für Anzeige im Kombi";
CM_ SG_ 988 MO_Drehzahl_01 "Im Fehlerfall wird die Motordrehzahl über die Nockenwellendrehzahl als Ersatzgrösse ausgegeben

Bei Parallelhybrid: Getriebeeingangsdrehzahl (=E-Maschinen Drehzahl)

Hinweis: 
Ehemaliger Fehlerwert 0xFFFF wird senderseitig nicht unterstützt. 
Diesen";
CM_ SG_ 988 MO_QBit_Drehzahl_01 "AUDI D4: Zykluszeit: 10ms (siehe Zykluszeit schnell/Cycletime Fast)

Achtung:
Reduktion der Zykluszeit Motor_03 auf 10ms geplant.
Projektabhängig soll künftig mit 10ms gesendet werden.
Empfänger die in weiteren Konzern-Projekten eingesetzt werden müs";
CM_ SG_ 988 TSK_06_alt "Veraltet-Bit für die BotschaftTSK_06_alt";
CM_ SG_ 988 TSK_Hauptschalter_GRA_ACC "Stellung des GRA/ACC Hauptschalters. Das Signal wird auch bei Fehlerabschaltungen von GRA/ACC weiterhin bedient und ermöglicht für ACC die Steuerung der ACC-Anzeige auch in Fehlerfällen.";
CM_ SG_ 988 TSK_Limiter_ausgewaehlt "ACC/GRA-Betrieb nur bei nicht ausgewähltem Limiter möglich";

CM_ SG_ 173 GE_Fahrstufe "Fahrprogramm des Getriebes

Hinweis: Zwischenstellung '0x0' darf nur für Zustandswechsel P/R, R/N, N/D ausgegeben werden, nicht für D/S oder D/Tippgasse wegen Abschaltkriterium GRA/ACC";
CM_ SG_ 173 GE_Freig_MMom_Vorhalt "Freigabe für die Anforderung einer Momentenreserve durch das Getriebe über das Signal
MLB: GE_MMom_Vorhalt
MQB/MLBevo: GE_MMom_Vorhalt_02";
CM_ SG_ 173 GE_MMom_Soll_02 "Momenteneingriff an den Motor.
Fordert vom MSG eine kurzfristige Reduzierung oder Anhebung des Moments.
Das Signal ist nur gültig in Kombination mit GE_MMom_Status (bei MQB) bzw. GE_MMom_Status_02 (bei MLBevo).

Achtung:
Einheitenloser Wert! Faktor i";
CM_ SG_ 173 GE_MMom_Status "Qualifiziert 
MLB: GE_MMom_Soll
MQB: GE_MMom_Soll_02";
CM_ SG_ 173 GE_MMom_Status_02 "Das Signal qualifiziert GE_MMom_Soll_02 und gibt an, wie der Wert aus GE_MMom_soll – vorbehaltlich der Umsetzbarkeit aufgrund motorinterner Restriktionen – umgesetzt werden soll.
Werte:
0= kein Eingriff
1=   absoluter reduzierender Eingriff auf Gesamt ";
CM_ SG_ 173 GE_MMom_Vorhalt_02 "Anforderung einer Momentenreserve durch das Getriebe, gilt nur mit Freigabe durch 
GE_Freig_MMom_Vorhalt

Anforderung wird als Absolut-Wert umgesetzt, nicht als Relativ-Wert/Delta zum aktuellen Ist-Moment (d. h. eine Momentenreserve wird eingestellt, w";
CM_ SG_ 173 GE_Schaltablauf "Das Signal zeigt den aktuellen Status eines Schaltvorgangs.

Bei Signal = 0 liegt kein Schaltvorgang vor.
Bei Signal =2 liegt die Befüllphase der zuschaltenden Kupplung bzw. 
                      die Vorbereitungsphase dazu vor.

Mit den unterschie";
CM_ SG_ 173 GE_Status_Kraftschluss "Zeigt den Ist-Status des Kraftschlusses im Getriebe.
(Anmerkung: meist wird damit der Zustand des Anfahrelements beschrieben, d.h. bei DL/DQ die Kupplung;  bei AQ/AL der Wandler incl. Überbrückungskupplung)
0 = offen, kein Kraftschluss
1 = offen mit Kr";
CM_ SG_ 173 GE_Uefkt "Übertragungsfunktion des Getriebes
Drehzahlverhältnis = Eingangsdrehzahl / Ausgangsdrehzahl

AL: Wandlerverstärkung x Drehzahlverhältnis
VL: Drehzahlverhältnis
DL: Drehzahlverhältnis der aktiven und kraftschluß führenden Welle zum Abtrieb, bei Schalt";
CM_ SG_ 173 GE_Uefkt_unplausibel "Das Signal darf nur im Reku-Manager in Hybrid-Varianten verwendet werden.
Zeigt an, ob die Plausibilisierung Momenten-Verhältnis zu Drehzahl-Verhältnis i.O. ist.
Ein gesetztes Signal meldet eine unplausible GE_Uefkt bzw. GE_Uefkt_02.";
CM_ SG_ 173 GE_Ursache_Fahrstufe_N "Zeigt an, warum Fahrstufe N angenommen wurde. So kann z.B. die Rollsicherung im Verlassenskonzept aktiv bleiben, wenn das Schalten nach N ohne Fahrerwunsch erfolgte (z.B. Fehlerreaktion).

ACHTUNG: Das Signal darf nur ausgewertet werden, wenn GE_Fahrstu";
CM_ SG_ 173 GE_Verbot_Ausblendung "Verbot Einspritzausblendung für komfortable Schaltungen";
CM_ SG_ 173 GE_Zielgang "VL-Getriebe:
Signalisiert den Zielgang im manuellen Modus während eines Schaltvorgangs bzw. die momentane simulierte Gangstufe wenn kein Schaltvorgang aktiv ist. In den Fahrprogrammen 'D' und 'S' ist die Übersetzung variabel und somit wird dauerhaft 'Ist";
CM_ SG_ 173 Getriebe_11_BZ "Botschaftszähler";
CM_ SG_ 173 Getriebe_11_CRC "Für MLB:
'Berechnung siehe Lastenheft 'Kommunikationsabsicherung für FlexRay und CAN''

Ab MQB und MLBevo:
'Berechnung siehe Lastenheft 'End-to-End Kommunikationsabsicherung''

Endwerte siehe Begleitdokument 'S-PDU Kennungsfolgen'";

CM_ SG_ 2463978722 GNSS_DR_Breite_Ortung "Dead Reckoning Breitengrad des Ortungsergebnisses nach WGS84 als Kombination von mehreren GNSSen";
CM_ SG_ 2463978722 GNSS_DR_Laenge_Ortung "Dead Reckoning Längengrad des Ortungsergebnisses nach WGS84 als Kombination von mehreren GNSSen";
CM_ SG_ 2463978722 GNSS_DR_Nachrichtenpaket_ID1 "+1 für jedes neue Paket. Zyklische ID-Vergabe (Zähler). Zur Identifizierung zusammenhängender Nachrichten, die die Daten derselben GNSS-Ortung enthalten und somit zum selben Zyklus gehören. D.h. Daten in den Nachrichten wurden zur selben Zeit erzeugt. Der";
CM_ SG_ 2463978722 GNSS_DR_Richtung_Breite_Ortung "Dead Reckoning Richtung des Breitengrads des Ortungsergebnisses nach WGS84 als Kombination von mehreren GNSSen";
CM_ SG_ 2463978722 GNSS_DR_Richtung_Laenge_Ortung "Dead Reckoning Richtung des Längengrads des Ortungsergebnisses nach WGS84 als Kombination von mehreren GNSSen";

CM_ SG_ 2463978723 GNSS_DR_Nachrichtenpaket_ID2 "+1 für jedes neue Paket. Zyklische ID-Vergabe (Zähler). Zur Identifizierung zusammenhängender Nachrichten, die die Daten derselben GNSS-Ortung enthalten und somit zum selben Zyklus gehören. D.h. Daten in den Nachrichten wurden zur selben Zeit erzeugt. Der";
CM_ SG_ 2463978723 GNSS_DR_Ortung_2D_Geschw_u_Grund "Dead Reckoning Geschwindigkeit in m pro Sekunde";
CM_ SG_ 2463978723 GNSS_DR_Ortung_Ausrichtung "Dead Reckoning Ausrichtung (Kurswinkel) der GNSS-Messung";

CM_ SG_ 299 GRA_Abbrechen "GRA : aus mit speichern
ACC : Soft aus";
CM_ SG_ 299 GRA_ACC_01_BZ "4bit Botschaftszaehler, wird mit jeder Sendebotschaft inkrementiert";
CM_ SG_ 299 GRA_ACC_01_CRC "Für MLB:
'Berechnung siehe Lastenheft 'Kommunikationsabsicherung für FlexRay und CAN''

Ab MQB und MLBevo:
'Berechnung siehe Lastenheft 'End-to-End Kommunikationsabsicherung''

Endwerte siehe Begleitdokument 'S-PDU Kennungsfolgen'";
CM_ SG_ 299 GRA_Codierung "Das Signal zeigt an, ob das Sende-SG (SMLS/MFL) auf GRA- oder ACC-Bedienteil codiert ist:
0: kein GRA- oder ACC Bedienteil
1: GRA-Bedienteil
2: ACC-Bedienteil
3: Limiter_Only-Bedienteil";
CM_ SG_ 299 GRA_Fehler "Das Signal zeigt an, dass das Sende-SG (SMLS/MFG) einen Defekt des GRA-Bedienteils erkannt hat und hierzu ein FSPE abgelegt wurde.";
CM_ SG_ 299 GRA_Hauptschalter "Stellung des GRA/ACC-Hauptschalters: 
Bei gerastetem Hauptschalter:
0: Hauptschalter aus
1: Hauptschalter ein
Bei getastetem Hauptschalter:
0: Taster nicht betätigt
1: Taster betätigt";
CM_ SG_ 299 GRA_LIM_Taste_verfuegbar "Das Signal zeigt an, ob eine Limiter-Umschalttaste am jeweiligen GRA/ACC-Bedienelement vorhanden ist.";
CM_ SG_ 299 GRA_Limiter "Stellung des Limiter-Tasters";
CM_ SG_ 299 GRA_PIT_Limiter "Stellung der Taste PIT-Speed-Limiter";
CM_ SG_ 299 GRA_reserveByte5 "Zweck: Befüllen der reservierten Bitpositionen mit 0 (wg. LIN-Teilnehmer MFL)";
CM_ SG_ 299 GRA_reserveByte6 "Zweck: Befüllen der reservierten Bitpositionen mit 0 (wg. LIN-Teilnehmer MFL)";
CM_ SG_ 299 GRA_reserveByte7 "Zweck: Befüllen der reservierten Bitpositionen mit 0 (wg. LIN-Teilnehmer MFL)";
CM_ SG_ 299 GRA_reserveByte8 "Zweck: Befüllen der reservierten Bitpositionen mit 0 (wg. LIN-Teilnehmer MFL)";
CM_ SG_ 299 GRA_Tip_Hoch "Tippschalter Tip Up / Geschwindigkeit erhöhen";
CM_ SG_ 299 GRA_Tip_Runter "Tippschalter Tip Down / Geschwindigkeit reduzieren";
CM_ SG_ 299 GRA_Tip_Setzen "Tippschalter Set";
CM_ SG_ 299 GRA_Tip_Stufe_2 "Signal zeigt an, dass der zweistufige GRA/ACC-Hebel (8_Positions_Bedienteil) in der 2. Tip-Stufe betätigt wird. Das Signal wird nur gleichzeitig mit dem Signal GRA_Tip_Hoch oder GRA_Tip_Runter gesetzt, wobei die Bits GRA_Tip_Hoch bzw. GRA_Tip_Runter die R";
CM_ SG_ 299 GRA_Tip_Wiederaufnahme "Tippschalter Wiederaufnahme";
CM_ SG_ 299 GRA_TravelAssist "Taste für TravelAssist";
CM_ SG_ 299 GRA_Typ_Bedienteil "Das Signal kennzeichnet die Variante des GRA/ACC-Bedienteils:
0: Init
1: 4-Positionen-Bedienteil (z.B. GRA im Blinkerhebel)
2: 6-Positionen-Bedienteil (GRA/ACC-Bedienteil mit separaten Stellungen für Set/Resume/TipUp/TipDown) 
3: 8-Positionen-Bediente";
CM_ SG_ 299 GRA_Typ_Hauptschalter "Variante des GRA/ACC-Hauptschalters:
0: gerasteter Hauptschalter (bzw. Taster mit Speicherung des Status im SMLS (PAG))
1: getasteter Hauptschalter, keine Speicherung des Status im SMLS";
CM_ SG_ 299 GRA_Verstellung_Zeitluecke "Verstellung der Zeitlücke für ACC

DIST -1 = Zeitluecke um 1 Stufe kleiner
DIST +1 = Zeitluecke um 1 Stufe groeßer
DIST Toggle = Zeitlücke um 1 Stufe kleiner, von kleinster Stufe auf größte Stufe";

CM_ SG_ 294 HCA_01_CRC "Für MLB:
'Berechnung siehe Lastenheft 'Kommunikationsabsicherung für Flexray und CAN''

Ab MQB und MLBevo:
'Berechnung siehe Lastenheft 'End-to-End Kommunikationsabsicherung'

Endwerte siehe Begleitdokument 'S-PDU Kennungsfolge'";
CM_ SG_ 294 HCA_01_LM_Offset "Von HCA angefordertes Lenkmoment (Betrag)";
CM_ SG_ 294 HCA_01_LM_OffSign "Vorzeichen des HCA-Lenkmoments";
CM_ SG_ 294 HCA_01_Sendestatus "Gibt den Sendestatus der HCA_01 an (notwendig für IL-Unterstützung)";
CM_ SG_ 294 HCA_01_Status_HCA "Statusinformation vom HCA und Manoevrierassistent für Handshakemechanismus mit der Lenkung";
CM_ SG_ 294 HCA_01_Vib_Amp "Momentenamplitude der Lenkradvibration";
CM_ SG_ 294 HCA_01_Vib_Freq "Frequenz der Lenkradvibration";

CM_ SG_ 771 FoD_DTC_TPA_rTPA_MFK "Function on Demand DTC for TPA and rTPA from MFK to Function Master";
CM_ SG_ 771 HCA_03_Sendestatus "Umschalten zwischen langsamem und schnellem Zyklus der HCA_03-Botschaft";
CM_ SG_ 771 HCA_QFK_AnfStat "Statusinformationen des Anforderers";
CM_ SG_ 771 HCA_QFK_Art1 "Auswahlsignal für HCA_QFK_Signal1";
CM_ SG_ 771 HCA_QFK_Art2 "Auswahlsignal für HCA_QFK_Signal2";
CM_ SG_ 771 HCA_QFK_KrSoll "Krümmungsanforderung";
CM_ SG_ 771 HCA_QFK_KrSoll_VZ "Vorzeichen für die Krümmungsanforderung";
CM_ SG_ 771 HCA_QFK_KruemmSoll "Krümmungsanforderung";
CM_ SG_ 771 HCA_QFK_KruemmSoll_VZ "Vorzeichen für die Krümmungsanforderung";
CM_ SG_ 771 HCA_QFK_Signal1 "Inhalt HCA_QFK_Signal1 wird durch das Signal HCA_QFK_Art1 gesteuert.
Nähere Informationen im LAH Querführungskoordinator.";
CM_ SG_ 771 HCA_QFK_Signal2 "Inhalt HCA_QFK_Signal2 wird durch das Signal HCA_QFK_Art2 gesteuert.
Nähere Informationen im LAH Querführungskoordinator.";
CM_ SG_ 771 HCA_QFK_Spuerb "Spürbarkeitsanforderung. Legt fest, mit welchem Handmoment die angeforderte Krümmung überlenkt werden muss.";
CM_ SG_ 771 SOK_HCA_03_Signatur "Signatur im Rahmen der durch SOK geschützen Broadcast-Kommunikation

Geschützte Funktion: LaneAssist/TravelAssist
Geschützte Botschaft: HCA_03";
BA_DEF_REL_ BU_SG_REL_  "GenSigTimeoutTime" INT 0 65535;
BA_DEF_ BO_  "DiagRequest" ENUM "No", "Yes";
BA_DEF_ BO_  "DiagResponse" ENUM "No", "Yes";
BA_DEF_ BO_  "DiagState" ENUM "No", "Yes";
BA_DEF_ BO_  "GenMsgChkConstant" HEX 0 4095;
BA_DEF_ BO_  "GenMsgCycleTime" INT 0 65535;
BA_DEF_ BO_  "GenMsgCycleTimeFast" INT 0 65535;
BA_DEF_ BO_  "GenMsgDelayTime" INT 0 100000;
BA_DEF_ BO_  "GenMsgILSupport" ENUM "No", "Yes";
BA_DEF_ BO_  "GenMsgNrOfRepetition" INT 0 100;
BA_DEF_ BO_  "GenMsgPDUConstants" STRING;
BA_DEF_ BO_  "GenMsgSendType" ENUM "Cyclic", "not_used", "not_used", "not_used", "not_used", "not_used", "not_used", "IfActive", "NoMsgSendType";
BA_DEF_ BO_  "GenMsgStartDelayTime" INT 0 100000;
BA_DEF_ BO_  "NmMessage" ENUM "No", "Yes";
BA_DEF_ BO_  "NmhMessage" ENUM "No", "Yes";
BA_DEF_ BO_  "MsgType" ENUM "Application", "NM ", "NMH", "TP2.0", "ISO-TP ", "BAP", "EID", "KS", "XCP_PRE_CONFIGURED", "XCP_RUNTIME_CONFIGURED";
BA_DEF_ BO_  "VAGTP20_API" HEX 0 255;
BA_DEF_ BO_  "VAGTP20_DynConnection" ENUM "No", "Yes";
BA_DEF_ BO_  "VAGTP20_DynSetup" ENUM "No", "Yes";
BA_DEF_ BO_  "VAGTP20_StatConnection" ENUM "No", "Yes";
BA_DEF_ BO_  "CANFD_BRS" ENUM "0", "1";
BA_DEF_ BO_  "VFrameFormat" ENUM "StandardCAN", "ExtendedCAN", "reserved", "reserved", "reserved", "reserved", "reserved", "reserved", "reserved", "reserved", "reserved", "reserved", "reserved", "reserved", "StandardCAN_FD", "ExtendedCAN_FD";
BA_DEF_ SG_  "GenSigActiveRepetitions" INT -2147483648 2147483647;
BA_DEF_ SG_  "GenSigInactiveValue" INT -2147483648 2147483647;
BA_DEF_ SG_  "GenSigSendType" ENUM "Cyclic", "OnWrite", "OnWriteWithRepetition", "OnChange", "OnChangeWithRepetition", "IfActive", "IfActiveWithRepetition", "NoSigSendType", "OnChangeAndIfActive", "OnChangeAndIfActiveWithRepetition";
BA_DEF_ SG_  "GenSigStartValue" INT -2147483648 2147483647;
BA_DEF_ SG_  "NWM-WakeupAllowed" ENUM "No", "Yes";
BA_DEF_ SG_  "GenSigFuncType" ENUM "NoFunction", "MsgCounter", "CRC-8", "XOR", "XOR-2", "DatedBit", "SW-Kl15", "CHK", "Constant", "Protocol", "CRC-8-SAE_J1850", "CRC-32", "DataLength", "DataID", "MsgCounter16", "SOK-Signatur", "Cluster";
BA_DEF_ SG_  "GenSigSwitchedByIgnition" ENUM "No", "Yes";
BA_DEF_ SG_  "Fehlerwert" HEX 0 2147483647;
BA_DEF_ SG_  "GenSigMissingSourceValue" HEX 0 2147483647;
BA_DEF_DEF_REL_  "GenSigTimeoutTime" 0;
BA_DEF_DEF_  "DiagRequest" "No";
BA_DEF_DEF_  "DiagResponse" "No";
BA_DEF_DEF_  "DiagState" "No";
BA_DEF_DEF_  "GenMsgChkConstant" 0;
BA_DEF_DEF_  "GenMsgCycleTime" 0;
BA_DEF_DEF_  "GenMsgCycleTimeFast" 0;
BA_DEF_DEF_  "GenMsgDelayTime" 0;
BA_DEF_DEF_  "GenMsgILSupport" "No";
BA_DEF_DEF_  "GenMsgNrOfRepetition" 0;
BA_DEF_DEF_  "GenMsgPDUConstants" "";
BA_DEF_DEF_  "GenMsgSendType" "NoMsgSendType";
BA_DEF_DEF_  "GenMsgStartDelayTime" 0;
BA_DEF_DEF_  "NmMessage" "No";
BA_DEF_DEF_  "NmhMessage" "No";
BA_DEF_DEF_  "MsgType" "Application";
BA_DEF_DEF_  "VAGTP20_API" 0;
BA_DEF_DEF_  "VAGTP20_DynConnection" "No";
BA_DEF_DEF_  "VAGTP20_DynSetup" "No";
BA_DEF_DEF_  "VAGTP20_StatConnection" "No";
BA_DEF_DEF_  "CANFD_BRS" "1";
BA_DEF_DEF_  "VFrameFormat" "StandardCAN";
BA_DEF_DEF_  "GenSigActiveRepetitions" 0;
BA_DEF_DEF_  "GenSigInactiveValue" 0;
BA_DEF_DEF_  "GenSigSendType" "NoSigSendType";
BA_DEF_DEF_  "GenSigStartValue" 0;
BA_DEF_DEF_  "NWM-WakeupAllowed" "No";
BA_DEF_DEF_  "GenSigFuncType" "NoFunction";
BA_DEF_DEF_  "GenSigSwitchedByIgnition" "Yes";
BA_DEF_DEF_  "Fehlerwert" 0;
BA_DEF_DEF_  "GenSigMissingSourceValue" 0;
BA_ "GenMsgCycleTime" BO_ 258 20;
BA_ "GenMsgILSupport" BO_ 258 1;
BA_ "GenMsgPDUConstants" BO_ 258 "0xd7,0x12,0x85,0x7e,0x0b,0x34,0xfa,0x16,0x7a,0x25,0x2d,0x8f,0x04,0x8e,0x5d,0x35";
BA_ "GenMsgSendType" BO_ 258 0;
BA_ "VFrameFormat" BO_ 258 14;
BA_ "GenMsgCycleTime" BO_ 252 10;
BA_ "GenMsgILSupport" BO_ 252 1;
BA_ "GenMsgPDUConstants" BO_ 252 "0x69,0xdc,0xf9,0x64,0x6a,0xce,0x55,0x2c,0xc4,0x38,0x8f,0xd1,0xc6,0x43,0xb4,0xb1";
BA_ "GenMsgSendType" BO_ 252 0;
BA_ "VFrameFormat" BO_ 252 14;
BA_ "GenMsgChkConstant" BO_ 278 172;
BA_ "GenMsgCycleTime" BO_ 278 20;
BA_ "GenMsgILSupport" BO_ 278 1;
BA_ "GenMsgPDUConstants" BO_ 278 "0xac,0xac,0xac,0xac,0xac,0xac,0xac,0xac,0xac,0xac,0xac,0xac,0xac,0xac,0xac,0xac";
BA_ "GenMsgSendType" BO_ 278 0;
BA_ "VFrameFormat" BO_ 278 14;
BA_ "GenMsgCycleTime" BO_ 1629 1000;
BA_ "GenMsgDelayTime" BO_ 1629 200;
BA_ "GenMsgILSupport" BO_ 1629 1;
BA_ "GenMsgPDUConstants" BO_ 1629 "0xac,0xb3,0xab,0xeb,0x7a,0xe1,0x3b,0xf7,0x73,0xba,0x7c,0x9e,0x06,0x5f,0x02,0xd9";
BA_ "GenMsgSendType" BO_ 1629 0;
BA_ "VFrameFormat" BO_ 1629 14;
BA_ "GenMsgCycleTime" BO_ 253 20;
BA_ "GenMsgILSupport" BO_ 253 1;
BA_ "GenMsgPDUConstants" BO_ 253 "0xb4,0xef,0xf8,0x49,0x1e,0xe5,0xc2,0xc0,0x97,0x19,0x3c,0xc9,0xf1,0x98,0xd6,0x61";
BA_ "GenMsgSendType" BO_ 253 0;
BA_ "VFrameFormat" BO_ 253 14;
BA_ "GenMsgCycleTime" BO_ 2527679740 200;
BA_ "GenMsgDelayTime" BO_ 2527679740 50;
BA_ "GenMsgILSupport" BO_ 2527679740 1;
BA_ "GenMsgSendType" BO_ 2527679740 0;
BA_ "VFrameFormat" BO_ 2527679740 15;
BA_ "GenMsgCycleTime" BO_ 1605 1000;
BA_ "GenMsgDelayTime" BO_ 1605 20;
BA_ "GenMsgILSupport" BO_ 1605 1;
BA_ "GenMsgSendType" BO_ 1605 0;
BA_ "VFrameFormat" BO_ 1605 14;
BA_ "GenMsgCycleTime" BO_ 2589283684 1000;
BA_ "GenMsgDelayTime" BO_ 2589283684 200;
BA_ "GenMsgILSupport" BO_ 2589283684 1;
BA_ "GenMsgSendType" BO_ 2589283684 0;
BA_ "VFrameFormat" BO_ 2589283684 15;
BA_ "MsgType" BO_ 2549875543 4;
BA_ "VFrameFormat" BO_ 2549875543 15;
BA_ "MsgType" BO_ 2550006615 4;
BA_ "VFrameFormat" BO_ 2550006615 15;
BA_ "MsgType" BO_ 2549875535 4;
BA_ "VFrameFormat" BO_ 2549875535 15;
BA_ "MsgType" BO_ 2550006607 4;
BA_ "VFrameFormat" BO_ 2550006607 15;
BA_ "GenMsgCycleTime" BO_ 987 100;
BA_ "GenMsgDelayTime" BO_ 987 10;
BA_ "GenMsgILSupport" BO_ 987 1;
BA_ "GenMsgSendType" BO_ 987 0;
BA_ "VFrameFormat" BO_ 987 14;
BA_ "GenMsgCycleTime" BO_ 988 50;
BA_ "GenMsgDelayTime" BO_ 988 10;
BA_ "GenMsgILSupport" BO_ 988 1;
BA_ "GenMsgSendType" BO_ 988 0;
BA_ "VFrameFormat" BO_ 988 14;
BA_ "GenMsgCycleTime" BO_ 173 50;
BA_ "GenMsgILSupport" BO_ 173 1;
BA_ "GenMsgPDUConstants" BO_ 173 "0x3f,0x69,0x39,0xdc,0x94,0xf9,0x14,0x64,0xd8,0x6a,0x34,0xce,0xa2,0x55,0xb5,0x2c";
BA_ "GenMsgSendType" BO_ 173 0;
BA_ "VFrameFormat" BO_ 173 14;
BA_ "GenMsgCycleTime" BO_ 2463978722 100;
BA_ "GenMsgILSupport" BO_ 2463978722 1;
BA_ "GenMsgSendType" BO_ 2463978722 0;
BA_ "VFrameFormat" BO_ 2463978722 15;
BA_ "GenMsgCycleTime" BO_ 2463978723 100;
BA_ "GenMsgILSupport" BO_ 2463978723 1;
BA_ "GenMsgSendType" BO_ 2463978723 0;
BA_ "VFrameFormat" BO_ 2463978723 15;
BA_ "GenMsgCycleTime" BO_ 299 30;
BA_ "GenMsgILSupport" BO_ 299 1;
BA_ "GenMsgPDUConstants" BO_ 299 "0x6a,0x38,0xb4,0x27,0x22,0xef,0xe1,0xbb,0xf8,0x80,0x84,0x49,0xc7,0x9e,0x1e,0x2b";
BA_ "GenMsgSendType" BO_ 299 0;
BA_ "VFrameFormat" BO_ 299 14;
BA_ "GenMsgChkConstant" BO_ 294 218;
BA_ "GenMsgCycleTime" BO_ 294 1000;
BA_ "GenMsgCycleTimeFast" BO_ 294 20;
BA_ "GenMsgILSupport" BO_ 294 1;
BA_ "GenMsgPDUConstants" BO_ 294 "0xda,0xda,0xda,0xda,0xda,0xda,0xda,0xda,0xda,0xda,0xda,0xda,0xda,0xda,0xda,0xda";
BA_ "GenMsgSendType" BO_ 294 0;
BA_ "VFrameFormat" BO_ 294 14;
BA_ "GenMsgCycleTime" BO_ 771 1000;
BA_ "GenMsgCycleTimeFast" BO_ 771 20;
BA_ "GenMsgILSupport" BO_ 771 1;
BA_ "GenMsgNrOfRepetition" BO_ 771 5;
BA_ "GenMsgSendType" BO_ 771 0;
BA_ "VFrameFormat" BO_ 771 14;
BA_ "GenSigSendType" SG_ 258 ASR_Systemstatus 0;
BA_ "GenSigStartValue" SG_ 258 ASR_Systemstatus 2;
BA_ "GenSigSwitchedByIgnition" SG_ 258 ASR_Systemstatus 0;
BA_ "GenSigSendType" SG_ 258 ECD_Bremslicht 0;
BA_ "GenSigSwitchedByIgnition" SG_ 258 ECD_Bremslicht 0;
BA_ "GenSigSendType" SG_ 258 ECD_Fehler 0;
BA_ "GenSigSwitchedByIgnition" SG_ 258 ECD_Fehler 0;
BA_ "GenSigSendType" SG_ 258 ECD_nicht_verfuegbar 0;
BA_ "GenSigStartValue" SG_ 258 ECD_nicht_verfuegbar 1;
BA_ "GenSigSwitchedByIgnition" SG_ 258 ECD_nicht_verfuegbar 0;
BA_ "GenSigSendType" SG_ 258 EPB_DAA_Randbed_erf 0;
BA_ "GenSigSwitchedByIgnition" SG_ 258 EPB_DAA_Randbed_erf 0;
BA_ "GenSigSendType" SG_ 258 EPB_Fehlerstatus_02 0;
BA_ "GenSigSwitchedByIgnition" SG_ 258 EPB_Fehlerstatus_02 0;
BA_ "GenSigSendType" SG_ 258 EPB_Freig_Verzoeg_Anf 0;
BA_ "GenSigSwitchedByIgnition" SG_ 258 EPB_Freig_Verzoeg_Anf 0;
BA_ "GenSigSendType" SG_ 258 EPB_Pedalweg_Kuppl 0;
BA_ "GenSigSwitchedByIgnition" SG_ 258 EPB_Pedalweg_Kuppl 0;
BA_ "Fehlerwert" SG_ 258 EPB_Pedalweg_Kuppl 255;
BA_ "GenSigSendType" SG_ 258 EPB_QBit_Pedalweg_Kuppl 0;
BA_ "GenSigStartValue" SG_ 258 EPB_QBit_Pedalweg_Kuppl 1;
BA_ "GenSigSwitchedByIgnition" SG_ 258 EPB_QBit_Pedalweg_Kuppl 0;
BA_ "GenSigSendType" SG_ 258 EPB_QBit_Schalterpos 0;
BA_ "GenSigStartValue" SG_ 258 EPB_QBit_Schalterpos 1;
BA_ "GenSigSwitchedByIgnition" SG_ 258 EPB_QBit_Schalterpos 0;
BA_ "GenSigSendType" SG_ 258 EPB_Schalterposition 0;
BA_ "GenSigSwitchedByIgnition" SG_ 258 EPB_Schalterposition 0;
BA_ "Fehlerwert" SG_ 258 EPB_Schalterposition 3;
BA_ "GenSigSendType" SG_ 258 EPB_Spannkraft 0;
BA_ "GenSigStartValue" SG_ 258 EPB_Spannkraft 30;
BA_ "GenSigSwitchedByIgnition" SG_ 258 EPB_Spannkraft 0;
BA_ "Fehlerwert" SG_ 258 EPB_Spannkraft 31;
BA_ "GenSigSendType" SG_ 258 EPB_Status 0;
BA_ "GenSigSwitchedByIgnition" SG_ 258 EPB_Status 0;
BA_ "GenSigSendType" SG_ 258 EPB_Status_02 0;
BA_ "GenSigStartValue" SG_ 258 EPB_Status_02 6;
BA_ "GenSigSwitchedByIgnition" SG_ 258 EPB_Status_02 0;
BA_ "GenSigSendType" SG_ 258 EPB_Verzoeg_Anf 0;
BA_ "GenSigStartValue" SG_ 258 EPB_Verzoeg_Anf 166;
BA_ "GenSigSwitchedByIgnition" SG_ 258 EPB_Verzoeg_Anf 0;
BA_ "GenSigSendType" SG_ 258 ESC_50_BZ 0;
BA_ "GenSigFuncType" SG_ 258 ESC_50_BZ 1;
BA_ "GenSigSwitchedByIgnition" SG_ 258 ESC_50_BZ 0;
BA_ "GenSigSendType" SG_ 258 ESC_50_CRC 0;
BA_ "GenSigFuncType" SG_ 258 ESC_50_CRC 2;
BA_ "GenSigSwitchedByIgnition" SG_ 258 ESC_50_CRC 0;
BA_ "GenSigSendType" SG_ 258 ESC_Bremsdruckgradient 0;
BA_ "GenSigStartValue" SG_ 258 ESC_Bremsdruckgradient 254;
BA_ "GenSigSwitchedByIgnition" SG_ 258 ESC_Bremsdruckgradient 0;
BA_ "Fehlerwert" SG_ 258 ESC_Bremsdruckgradient 255;
BA_ "GenSigSendType" SG_ 258 ESC_Fahrerbremswunsch 0;
BA_ "GenSigStartValue" SG_ 258 ESC_Fahrerbremswunsch 100;
BA_ "GenSigSwitchedByIgnition" SG_ 258 ESC_Fahrerbremswunsch 0;
BA_ "Fehlerwert" SG_ 258 ESC_Fahrerbremswunsch 1023;
BA_ "GenSigSendType" SG_ 258 ESC_Fahrerradbremswunschmoment 0;
BA_ "GenSigStartValue" SG_ 258 ESC_Fahrerradbremswunschmoment 4094;
BA_ "GenSigSwitchedByIgnition" SG_ 258 ESC_Fahrerradbremswunschmoment 0;
BA_ "Fehlerwert" SG_ 258 ESC_Fahrerradbremswunschmoment 4095;
BA_ "GenSigSendType" SG_ 258 ESC_Hydr_Fkt_aktiv 0;
BA_ "GenSigSwitchedByIgnition" SG_ 258 ESC_Hydr_Fkt_aktiv 0;
BA_ "GenSigSendType" SG_ 258 ESC_Motorstartverzoegerung 0;
BA_ "GenSigSwitchedByIgnition" SG_ 258 ESC_Motorstartverzoegerung 0;
BA_ "GenSigSendType" SG_ 258 ESC_QBit_Fahrerbremswunsch 0;
BA_ "GenSigStartValue" SG_ 258 ESC_QBit_Fahrerbremswunsch 1;
BA_ "GenSigSwitchedByIgnition" SG_ 258 ESC_QBit_Fahrerbremswunsch 0;
BA_ "GenSigSendType" SG_ 258 ESC_Raddruck_max 0;
BA_ "GenSigStartValue" SG_ 258 ESC_Raddruck_max 254;
BA_ "GenSigSwitchedByIgnition" SG_ 258 ESC_Raddruck_max 0;
BA_ "Fehlerwert" SG_ 258 ESC_Raddruck_max 255;
BA_ "GenSigSendType" SG_ 258 ESC_SeitenwindAssistent_Eingriff 0;
BA_ "GenSigSwitchedByIgnition" SG_ 258 ESC_SeitenwindAssistent_Eingriff 0;
BA_ "GenSigSendType" SG_ 258 ESC_Unterdruckmangel_erkannt 0;
BA_ "GenSigSwitchedByIgnition" SG_ 258 ESC_Unterdruckmangel_erkannt 0;
BA_ "GenSigSendType" SG_ 258 ESCGeneratorSollMoment 0;
BA_ "GenSigStartValue" SG_ 258 ESCGeneratorSollMoment 4094;
BA_ "GenSigSwitchedByIgnition" SG_ 258 ESCGeneratorSollMoment 0;
BA_ "Fehlerwert" SG_ 258 ESCGeneratorSollMoment 4095;
BA_ "GenSigSendType" SG_ 258 ESP_Abrutschen_Stillstand 0;
BA_ "GenSigSwitchedByIgnition" SG_ 258 ESP_Abrutschen_Stillstand 0;
BA_ "GenSigSendType" SG_ 258 ESP_ANB_CM_Rueckk_Umsetz 0;
BA_ "GenSigSwitchedByIgnition" SG_ 258 ESP_ANB_CM_Rueckk_Umsetz 0;
BA_ "GenSigSendType" SG_ 258 ESP_Anforderung_EPB 0;
BA_ "GenSigSwitchedByIgnition" SG_ 258 ESP_Anforderung_EPB 0;
BA_ "GenSigSendType" SG_ 258 ESP_Anschleppstart_Freigabe 0;
BA_ "GenSigSwitchedByIgnition" SG_ 258 ESP_Anschleppstart_Freigabe 0;
BA_ "GenSigSendType" SG_ 258 ESP_Autohold_aktiv 0;
BA_ "GenSigSwitchedByIgnition" SG_ 258 ESP_Autohold_aktiv 0;
BA_ "GenSigSendType" SG_ 258 ESP_Autohold_Standby 0;
BA_ "GenSigSwitchedByIgnition" SG_ 258 ESP_Autohold_Standby 0;
BA_ "GenSigSendType" SG_ 258 ESP_BKV_Unterdruck 0;
BA_ "GenSigStartValue" SG_ 258 ESP_BKV_Unterdruck 254;
BA_ "GenSigSwitchedByIgnition" SG_ 258 ESP_BKV_Unterdruck 0;
BA_ "Fehlerwert" SG_ 258 ESP_BKV_Unterdruck 255;
BA_ "GenSigSendType" SG_ 258 ESP_Bremsdruck 0;
BA_ "GenSigStartValue" SG_ 258 ESP_Bremsdruck 100;
BA_ "GenSigSwitchedByIgnition" SG_ 258 ESP_Bremsdruck 0;
BA_ "Fehlerwert" SG_ 258 ESP_Bremsdruck 1023;
BA_ "GenSigSendType" SG_ 258 ESP_Bremsruck_AWV2 0;
BA_ "GenSigSwitchedByIgnition" SG_ 258 ESP_Bremsruck_AWV2 0;
BA_ "GenSigSendType" SG_ 258 ESP_Eingr_HL 0;
BA_ "GenSigSwitchedByIgnition" SG_ 258 ESP_Eingr_HL 0;
BA_ "GenSigSendType" SG_ 258 ESP_Eingr_HR 0;
BA_ "GenSigSwitchedByIgnition" SG_ 258 ESP_Eingr_HR 0;
BA_ "GenSigSendType" SG_ 258 ESP_Eingr_VL 0;
BA_ "GenSigSwitchedByIgnition" SG_ 258 ESP_Eingr_VL 0;
BA_ "GenSigSendType" SG_ 258 ESP_Eingr_VR 0;
BA_ "GenSigSwitchedByIgnition" SG_ 258 ESP_Eingr_VR 0;
BA_ "GenSigSendType" SG_ 258 ESP_Fahrer_bremst 0;
BA_ "GenSigSwitchedByIgnition" SG_ 258 ESP_Fahrer_bremst 0;
BA_ "GenSigSendType" SG_ 258 ESP_Fahrer_tritt_ZBR_Schw 0;
BA_ "GenSigSwitchedByIgnition" SG_ 258 ESP_Fahrer_tritt_ZBR_Schw 0;
BA_ "GenSigSendType" SG_ 258 ESP_FStatus_Anfahrhilfe 0;
BA_ "GenSigSwitchedByIgnition" SG_ 258 ESP_FStatus_Anfahrhilfe 0;
BA_ "Fehlerwert" SG_ 258 ESP_FStatus_Anfahrhilfe 1;
BA_ "GenSigSendType" SG_ 258 ESP_Gierrate 0;
BA_ "GenSigSwitchedByIgnition" SG_ 258 ESP_Gierrate 0;
BA_ "Fehlerwert" SG_ 258 ESP_Gierrate 16383;
BA_ "GenSigSendType" SG_ 258 ESP_HBA_aktiv 0;
BA_ "GenSigSwitchedByIgnition" SG_ 258 ESP_HBA_aktiv 0;
BA_ "GenSigSendType" SG_ 258 ESP_HBA_Empfindlichkeit 0;
BA_ "GenSigSwitchedByIgnition" SG_ 258 ESP_HBA_Empfindlichkeit 0;
BA_ "Fehlerwert" SG_ 258 ESP_HBA_Empfindlichkeit 7;
BA_ "GenSigSendType" SG_ 258 ESP_HDC_aktiv 0;
BA_ "GenSigSwitchedByIgnition" SG_ 258 ESP_HDC_aktiv 0;
BA_ "GenSigSendType" SG_ 258 ESP_HDC_Standby 0;
BA_ "GenSigSwitchedByIgnition" SG_ 258 ESP_HDC_Standby 0;
BA_ "GenSigSendType" SG_ 258 ESP_Konsistenz_ACC_Botschaft 0;
BA_ "GenSigSwitchedByIgnition" SG_ 258 ESP_Konsistenz_ACC_Botschaft 0;
BA_ "GenSigSendType" SG_ 258 ESP_Konsistenz_AWV2 0;
BA_ "GenSigSwitchedByIgnition" SG_ 258 ESP_Konsistenz_AWV2 0;
BA_ "GenSigSendType" SG_ 258 ESP_Konsistenz_TSK 0;
BA_ "GenSigSwitchedByIgnition" SG_ 258 ESP_Konsistenz_TSK 0;
BA_ "GenSigSendType" SG_ 258 ESP_Laengsbeschl 0;
BA_ "GenSigStartValue" SG_ 258 ESP_Laengsbeschl 512;
BA_ "GenSigSwitchedByIgnition" SG_ 258 ESP_Laengsbeschl 0;
BA_ "Fehlerwert" SG_ 258 ESP_Laengsbeschl 1023;
BA_ "GenSigSendType" SG_ 258 ESP_Lenkeingriff_ADS 0;
BA_ "GenSigSwitchedByIgnition" SG_ 258 ESP_Lenkeingriff_ADS 0;
BA_ "GenSigSendType" SG_ 258 ESP_Notbremsanzeige 0;
BA_ "GenSigSwitchedByIgnition" SG_ 258 ESP_Notbremsanzeige 0;
BA_ "GenSigSendType" SG_ 258 ESP_PLA_Abbruch 0;
BA_ "GenSigSwitchedByIgnition" SG_ 258 ESP_PLA_Abbruch 0;
BA_ "GenSigSendType" SG_ 258 ESP_Prefill_ausgeloest 0;
BA_ "GenSigSwitchedByIgnition" SG_ 258 ESP_Prefill_ausgeloest 0;
BA_ "GenSigSendType" SG_ 258 ESP_QBit_Bremsdruck 0;
BA_ "GenSigStartValue" SG_ 258 ESP_QBit_Bremsdruck 1;
BA_ "GenSigSwitchedByIgnition" SG_ 258 ESP_QBit_Bremsdruck 0;
BA_ "GenSigSendType" SG_ 258 ESP_QBit_Fahrer_bremst 0;
BA_ "GenSigStartValue" SG_ 258 ESP_QBit_Fahrer_bremst 1;
BA_ "GenSigSwitchedByIgnition" SG_ 258 ESP_QBit_Fahrer_bremst 0;
BA_ "GenSigSendType" SG_ 258 ESP_QBit_Gierrate 0;
BA_ "GenSigStartValue" SG_ 258 ESP_QBit_Gierrate 1;
BA_ "GenSigSwitchedByIgnition" SG_ 258 ESP_QBit_Gierrate 0;
BA_ "GenSigSendType" SG_ 258 ESP_QBit_Laengsbeschl 0;
BA_ "GenSigStartValue" SG_ 258 ESP_QBit_Laengsbeschl 1;
BA_ "GenSigSwitchedByIgnition" SG_ 258 ESP_QBit_Laengsbeschl 0;
BA_ "GenSigSendType" SG_ 258 ESP_QBit_Querb 0;
BA_ "GenSigStartValue" SG_ 258 ESP_QBit_Querb 1;
BA_ "GenSigSwitchedByIgnition" SG_ 258 ESP_QBit_Querb 0;
BA_ "GenSigSendType" SG_ 258 ESP_QBit_v_ref 0;
BA_ "GenSigStartValue" SG_ 258 ESP_QBit_v_ref 1;
BA_ "GenSigSwitchedByIgnition" SG_ 258 ESP_QBit_v_ref 0;
BA_ "GenSigSendType" SG_ 258 ESP_Querbeschleunigung 0;
BA_ "GenSigStartValue" SG_ 258 ESP_Querbeschleunigung 127;
BA_ "GenSigSwitchedByIgnition" SG_ 258 ESP_Querbeschleunigung 0;
BA_ "Fehlerwert" SG_ 258 ESP_Querbeschleunigung 255;
BA_ "GenSigSendType" SG_ 258 ESP_Rueckwaertsfahrt_erkannt 0;
BA_ "GenSigSwitchedByIgnition" SG_ 258 ESP_Rueckwaertsfahrt_erkannt 0;
BA_ "GenSigSendType" SG_ 258 ESP_Schwelle_Unterdruck 0;
BA_ "GenSigSwitchedByIgnition" SG_ 258 ESP_Schwelle_Unterdruck 0;
BA_ "GenSigSendType" SG_ 258 ESP_SpannungsAnf 0;
BA_ "GenSigSwitchedByIgnition" SG_ 258 ESP_SpannungsAnf 0;
BA_ "GenSigSendType" SG_ 258 ESP_StartStopp_Info 0;
BA_ "GenSigSwitchedByIgnition" SG_ 258 ESP_StartStopp_Info 0;
BA_ "GenSigSendType" SG_ 258 ESP_Status_Anfahrhilfe 0;
BA_ "GenSigSwitchedByIgnition" SG_ 258 ESP_Status_Anfahrhilfe 0;
BA_ "GenSigSendType" SG_ 258 ESP_Status_Bremsdruck 0;
BA_ "GenSigSwitchedByIgnition" SG_ 258 ESP_Status_Bremsdruck 0;
BA_ "GenSigSendType" SG_ 258 ESP_Status_Bremsentemp 0;
BA_ "GenSigSwitchedByIgnition" SG_ 258 ESP_Status_Bremsentemp 0;
BA_ "GenSigSendType" SG_ 258 ESP_Status_Bremsentemp_02 0;
BA_ "GenSigSwitchedByIgnition" SG_ 258 ESP_Status_Bremsentemp_02 0;
BA_ "GenSigSendType" SG_ 258 ESP_Status_ESP_PLA 0;
BA_ "GenSigSwitchedByIgnition" SG_ 258 ESP_Status_ESP_PLA 0;
BA_ "GenSigSendType" SG_ 258 ESP_Stillstandsphase_erschoepft 0;
BA_ "GenSigSwitchedByIgnition" SG_ 258 ESP_Stillstandsphase_erschoepft 0;
BA_ "GenSigSendType" SG_ 258 ESP_Systemstatus_03 0;
BA_ "GenSigStartValue" SG_ 258 ESP_Systemstatus_03 2;
BA_ "GenSigSwitchedByIgnition" SG_ 258 ESP_Systemstatus_03 0;
BA_ "Fehlerwert" SG_ 258 ESP_Systemstatus_03 3;
BA_ "GenSigSendType" SG_ 258 ESP_Tuerkontakt_Fahrertuer 0;
BA_ "GenSigSwitchedByIgnition" SG_ 258 ESP_Tuerkontakt_Fahrertuer 0;
BA_ "GenSigSendType" SG_ 258 ESP_v_ref 0;
BA_ "GenSigStartValue" SG_ 258 ESP_v_ref 4094;
BA_ "GenSigSwitchedByIgnition" SG_ 258 ESP_v_ref 0;
BA_ "Fehlerwert" SG_ 258 ESP_v_ref 4095;
BA_ "GenSigSendType" SG_ 258 ESP_v_ref_Fahrtrichtung 0;
BA_ "GenSigSwitchedByIgnition" SG_ 258 ESP_v_ref_Fahrtrichtung 0;
BA_ "GenSigSendType" SG_ 258 ESP_Verz_EPB_aktiv 0;
BA_ "GenSigSwitchedByIgnition" SG_ 258 ESP_Verz_EPB_aktiv 0;
BA_ "GenSigSendType" SG_ 258 ESP_Verz_TSK_aktiv 0;
BA_ "GenSigSwitchedByIgnition" SG_ 258 ESP_Verz_TSK_aktiv 0;
BA_ "GenSigSendType" SG_ 258 ESP_Verzoeg_EPB_verf 0;
BA_ "GenSigSwitchedByIgnition" SG_ 258 ESP_Verzoeg_EPB_verf 0;
BA_ "GenSigSendType" SG_ 258 ESP_VZ_Gierrate 0;
BA_ "GenSigSwitchedByIgnition" SG_ 258 ESP_VZ_Gierrate 0;
BA_ "GenSigSendType" SG_ 258 ESP_ZT_Rueckk_Umsetz 0;
BA_ "GenSigSwitchedByIgnition" SG_ 258 ESP_ZT_Rueckk_Umsetz 0;
BA_ "GenSigSendType" SG_ 258 SOK_ESC_50_Signatur 0;
BA_ "GenSigFuncType" SG_ 258 SOK_ESC_50_Signatur 15;
BA_ "GenSigSwitchedByIgnition" SG_ 258 SOK_ESC_50_Signatur 0;
BA_ "GenSigSendType" SG_ 252 ESC_51_BZ 0;
BA_ "GenSigFuncType" SG_ 252 ESC_51_BZ 1;
BA_ "GenSigSwitchedByIgnition" SG_ 252 ESC_51_BZ 0;
BA_ "GenSigSendType" SG_ 252 ESC_51_CRC 0;
BA_ "GenSigFuncType" SG_ 252 ESC_51_CRC 2;
BA_ "GenSigSwitchedByIgnition" SG_ 252 ESC_51_CRC 0;
BA_ "GenSigSendType" SG_ 252 ESC_Achsdrehzahl_Max 0;
BA_ "GenSigStartValue" SG_ 252 ESC_Achsdrehzahl_Max 16382;
BA_ "GenSigSwitchedByIgnition" SG_ 252 ESC_Achsdrehzahl_Max 0;
BA_ "Fehlerwert" SG_ 252 ESC_Achsdrehzahl_Max 16383;
BA_ "GenSigSendType" SG_ 252 ESC_Achsdrehzahl_Max_sek 0;
BA_ "GenSigStartValue" SG_ 252 ESC_Achsdrehzahl_Max_sek 16382;
BA_ "GenSigSwitchedByIgnition" SG_ 252 ESC_Achsdrehzahl_Max_sek 0;
BA_ "Fehlerwert" SG_ 252 ESC_Achsdrehzahl_Max_sek 16383;
BA_ "GenSigSendType" SG_ 252 ESC_Achsdrehzahl_Min 0;
BA_ "GenSigStartValue" SG_ 252 ESC_Achsdrehzahl_Min 16382;
BA_ "GenSigSwitchedByIgnition" SG_ 252 ESC_Achsdrehzahl_Min 0;
BA_ "Fehlerwert" SG_ 252 ESC_Achsdrehzahl_Min 16383;
BA_ "GenSigSendType" SG_ 252 ESC_Achsdrehzahl_Min_sek 0;
BA_ "GenSigStartValue" SG_ 252 ESC_Achsdrehzahl_Min_sek 16382;
BA_ "GenSigSwitchedByIgnition" SG_ 252 ESC_Achsdrehzahl_Min_sek 0;
BA_ "Fehlerwert" SG_ 252 ESC_Achsdrehzahl_Min_sek 16383;
BA_ "GenSigSendType" SG_ 252 ESC_aktBR_Modus_02 0;
BA_ "GenSigSwitchedByIgnition" SG_ 252 ESC_aktBR_Modus_02 0;
BA_ "GenSigSendType" SG_ 252 ESC_aktBr_Volumenstrom 0;
BA_ "GenSigStartValue" SG_ 252 ESC_aktBr_Volumenstrom 32256;
BA_ "GenSigSwitchedByIgnition" SG_ 252 ESC_aktBr_Volumenstrom 0;
BA_ "GenSigSendType" SG_ 252 ESC_Allrad_Anteil_max_sek 0;
BA_ "GenSigStartValue" SG_ 252 ESC_Allrad_Anteil_max_sek 510;
BA_ "GenSigSwitchedByIgnition" SG_ 252 ESC_Allrad_Anteil_max_sek 0;
BA_ "Fehlerwert" SG_ 252 ESC_Allrad_Anteil_max_sek 511;
BA_ "GenSigSendType" SG_ 252 ESC_Allrad_Anteil_min_sek 0;
BA_ "GenSigStartValue" SG_ 252 ESC_Allrad_Anteil_min_sek 510;
BA_ "GenSigSwitchedByIgnition" SG_ 252 ESC_Allrad_Anteil_min_sek 0;
BA_ "Fehlerwert" SG_ 252 ESC_Allrad_Anteil_min_sek 511;
BA_ "GenSigSendType" SG_ 252 ESC_Allradverteilung_aktiv 0;
BA_ "GenSigSwitchedByIgnition" SG_ 252 ESC_Allradverteilung_aktiv 0;
BA_ "GenSigSendType" SG_ 252 ESC_Anf_Mindestreku 0;
BA_ "GenSigSwitchedByIgnition" SG_ 252 ESC_Anf_Mindestreku 0;
BA_ "GenSigSendType" SG_ 252 ESC_Blending_Solldruck 0;
BA_ "GenSigStartValue" SG_ 252 ESC_Blending_Solldruck 1022;
BA_ "GenSigSwitchedByIgnition" SG_ 252 ESC_Blending_Solldruck 0;
BA_ "Fehlerwert" SG_ 252 ESC_Blending_Solldruck 1023;
BA_ "GenSigSendType" SG_ 252 ESC_Bremsdruck_02 0;
BA_ "GenSigStartValue" SG_ 252 ESC_Bremsdruck_02 100;
BA_ "GenSigSwitchedByIgnition" SG_ 252 ESC_Bremsdruck_02 0;
BA_ "Fehlerwert" SG_ 252 ESC_Bremsdruck_02 1023;
BA_ "GenSigSendType" SG_ 252 ESC_Bremsdruck_Modell 0;
BA_ "GenSigStartValue" SG_ 252 ESC_Bremsdruck_Modell 1022;
BA_ "GenSigSwitchedByIgnition" SG_ 252 ESC_Bremsdruck_Modell 0;
BA_ "Fehlerwert" SG_ 252 ESC_Bremsdruck_Modell 1023;
BA_ "GenSigSendType" SG_ 252 ESC_EBKV_Kraftblending_Modus 0;
BA_ "GenSigSwitchedByIgnition" SG_ 252 ESC_EBKV_Kraftblending_Modus 0;
BA_ "GenSigSendType" SG_ 252 ESC_GMV_aktiv 0;
BA_ "GenSigSwitchedByIgnition" SG_ 252 ESC_GMV_aktiv 0;
BA_ "GenSigSendType" SG_ 252 ESC_GMV_nicht_verfuegbar 0;
BA_ "GenSigStartValue" SG_ 252 ESC_GMV_nicht_verfuegbar 1;
BA_ "GenSigSwitchedByIgnition" SG_ 252 ESC_GMV_nicht_verfuegbar 0;
BA_ "GenSigSendType" SG_ 252 ESC_MomRad_Eingriff 0;
BA_ "GenSigStartValue" SG_ 252 ESC_MomRad_Eingriff 8190;
BA_ "GenSigSwitchedByIgnition" SG_ 252 ESC_MomRad_Eingriff 0;
BA_ "Fehlerwert" SG_ 252 ESC_MomRad_Eingriff 8191;
BA_ "GenSigSendType" SG_ 252 ESC_MomRad_Eingriff_sek 0;
BA_ "GenSigStartValue" SG_ 252 ESC_MomRad_Eingriff_sek 8190;
BA_ "GenSigSwitchedByIgnition" SG_ 252 ESC_MomRad_Eingriff_sek 0;
BA_ "Fehlerwert" SG_ 252 ESC_MomRad_Eingriff_sek 8191;
BA_ "GenSigSendType" SG_ 252 ESC_QBit_Bremsdruck_02 0;
BA_ "GenSigStartValue" SG_ 252 ESC_QBit_Bremsdruck_02 1;
BA_ "GenSigSwitchedByIgnition" SG_ 252 ESC_QBit_Bremsdruck_02 0;
BA_ "GenSigSendType" SG_ 252 ESC_Status_Eingriff 0;
BA_ "GenSigSwitchedByIgnition" SG_ 252 ESC_Status_Eingriff 0;
BA_ "GenSigSendType" SG_ 252 ESC_Status_Eingriff_sek 0;
BA_ "GenSigSwitchedByIgnition" SG_ 252 ESC_Status_Eingriff_sek 0;
BA_ "GenSigSendType" SG_ 252 ESC_Status_vRef_Stuetzeingriff 0;
BA_ "GenSigSwitchedByIgnition" SG_ 252 ESC_Status_vRef_Stuetzeingriff 0;
BA_ "GenSigSendType" SG_ 252 ESP_FDR_uebersteuern 0;
BA_ "GenSigStartValue" SG_ 252 ESP_FDR_uebersteuern 254;
BA_ "GenSigSwitchedByIgnition" SG_ 252 ESP_FDR_uebersteuern 0;
BA_ "Fehlerwert" SG_ 252 ESP_FDR_uebersteuern 255;
BA_ "GenSigSendType" SG_ 252 ESP_FDR_untersteuern 0;
BA_ "GenSigStartValue" SG_ 252 ESP_FDR_untersteuern 254;
BA_ "GenSigSwitchedByIgnition" SG_ 252 ESP_FDR_untersteuern 0;
BA_ "Fehlerwert" SG_ 252 ESP_FDR_untersteuern 255;
BA_ "GenSigSendType" SG_ 252 ESP_FZR_uebersteuern 0;
BA_ "GenSigStartValue" SG_ 252 ESP_FZR_uebersteuern 254;
BA_ "NWM-WakeupAllowed" SG_ 252 ESP_FZR_uebersteuern 1;
BA_ "GenSigSwitchedByIgnition" SG_ 252 ESP_FZR_uebersteuern 0;
BA_ "Fehlerwert" SG_ 252 ESP_FZR_uebersteuern 255;
BA_ "GenSigMissingSourceValue" SG_ 252 ESP_FZR_uebersteuern 254;
BA_ "GenSigSendType" SG_ 252 ESP_FZR_untersteuern 0;
BA_ "GenSigStartValue" SG_ 252 ESP_FZR_untersteuern 254;
BA_ "NWM-WakeupAllowed" SG_ 252 ESP_FZR_untersteuern 1;
BA_ "GenSigSwitchedByIgnition" SG_ 252 ESP_FZR_untersteuern 0;
BA_ "Fehlerwert" SG_ 252 ESP_FZR_untersteuern 255;
BA_ "GenSigMissingSourceValue" SG_ 252 ESP_FZR_untersteuern 254;
BA_ "GenSigSendType" SG_ 252 ESP_HL_Bremsmoment 0;
BA_ "GenSigStartValue" SG_ 252 ESP_HL_Bremsmoment 254;
BA_ "Fehlerwert" SG_ 252 ESP_HL_Bremsmoment 255;
BA_ "GenSigSendType" SG_ 252 ESP_HL_Radgeschw_02 0;
BA_ "GenSigStartValue" SG_ 252 ESP_HL_Radgeschw_02 65534;
BA_ "GenSigSwitchedByIgnition" SG_ 252 ESP_HL_Radgeschw_02 0;
BA_ "Fehlerwert" SG_ 252 ESP_HL_Radgeschw_02 65535;
BA_ "GenSigSendType" SG_ 252 ESP_HR_Bremsmoment 0;
BA_ "GenSigStartValue" SG_ 252 ESP_HR_Bremsmoment 254;
BA_ "Fehlerwert" SG_ 252 ESP_HR_Bremsmoment 255;
BA_ "GenSigSendType" SG_ 252 ESP_HR_Radgeschw_02 0;
BA_ "GenSigStartValue" SG_ 252 ESP_HR_Radgeschw_02 65534;
BA_ "GenSigSwitchedByIgnition" SG_ 252 ESP_HR_Radgeschw_02 0;
BA_ "Fehlerwert" SG_ 252 ESP_HR_Radgeschw_02 65535;
BA_ "GenSigSendType" SG_ 252 ESP_VL_Bremsmoment 0;
BA_ "GenSigStartValue" SG_ 252 ESP_VL_Bremsmoment 254;
BA_ "Fehlerwert" SG_ 252 ESP_VL_Bremsmoment 255;
BA_ "GenSigSendType" SG_ 252 ESP_VL_Radgeschw_02 0;
BA_ "GenSigStartValue" SG_ 252 ESP_VL_Radgeschw_02 65534;
BA_ "GenSigSwitchedByIgnition" SG_ 252 ESP_VL_Radgeschw_02 0;
BA_ "Fehlerwert" SG_ 252 ESP_VL_Radgeschw_02 65535;
BA_ "GenSigSendType" SG_ 252 ESP_VR_Bremsmoment 0;
BA_ "GenSigStartValue" SG_ 252 ESP_VR_Bremsmoment 254;
BA_ "Fehlerwert" SG_ 252 ESP_VR_Bremsmoment 255;
BA_ "GenSigSendType" SG_ 252 ESP_VR_Radgeschw_02 0;
BA_ "GenSigStartValue" SG_ 252 ESP_VR_Radgeschw_02 65534;
BA_ "GenSigSwitchedByIgnition" SG_ 252 ESP_VR_Radgeschw_02 0;
BA_ "Fehlerwert" SG_ 252 ESP_VR_Radgeschw_02 65535;
BA_ "GenSigSendType" SG_ 252 FDR_Allradverteilung_aktiv 0;
BA_ "GenSigSwitchedByIgnition" SG_ 252 FDR_Allradverteilung_aktiv 0;
BA_ "GenSigSendType" SG_ 252 FDR_Anf_Allradbetrieb 0;
BA_ "GenSigSwitchedByIgnition" SG_ 252 FDR_Anf_Allradbetrieb 0;
BA_ "GenSigSendType" SG_ 252 SOK_ESC_51_Signatur 0;
BA_ "GenSigFuncType" SG_ 252 SOK_ESC_51_Signatur 15;
BA_ "GenSigSendType" SG_ 252 TSMomBegrenzung 0;
BA_ "GenSigStartValue" SG_ 252 TSMomBegrenzung 4094;
BA_ "GenSigSwitchedByIgnition" SG_ 252 TSMomBegrenzung 0;
BA_ "Fehlerwert" SG_ 252 TSMomBegrenzung 4095;
BA_ "GenSigSendType" SG_ 278 ESP_10_BZ 0;
BA_ "GenSigFuncType" SG_ 278 ESP_10_BZ 1;
BA_ "GenSigSwitchedByIgnition" SG_ 278 ESP_10_BZ 0;
BA_ "GenSigSendType" SG_ 278 ESP_10_CRC 0;
BA_ "GenSigFuncType" SG_ 278 ESP_10_CRC 2;
BA_ "GenSigSwitchedByIgnition" SG_ 278 ESP_10_CRC 0;
BA_ "GenSigSendType" SG_ 278 ESP_HL_Fahrtrichtung 0;
BA_ "GenSigStartValue" SG_ 278 ESP_HL_Fahrtrichtung 2;
BA_ "GenSigSwitchedByIgnition" SG_ 278 ESP_HL_Fahrtrichtung 0;
BA_ "GenSigSendType" SG_ 278 ESP_HR_Fahrtrichtung 0;
BA_ "GenSigStartValue" SG_ 278 ESP_HR_Fahrtrichtung 2;
BA_ "GenSigSwitchedByIgnition" SG_ 278 ESP_HR_Fahrtrichtung 0;
BA_ "GenSigSendType" SG_ 278 ESP_QBit_Wegimpuls_HL 0;
BA_ "GenSigStartValue" SG_ 278 ESP_QBit_Wegimpuls_HL 1;
BA_ "GenSigSwitchedByIgnition" SG_ 278 ESP_QBit_Wegimpuls_HL 0;
BA_ "GenSigSendType" SG_ 278 ESP_QBit_Wegimpuls_HR 0;
BA_ "GenSigStartValue" SG_ 278 ESP_QBit_Wegimpuls_HR 1;
BA_ "GenSigSwitchedByIgnition" SG_ 278 ESP_QBit_Wegimpuls_HR 0;
BA_ "GenSigSendType" SG_ 278 ESP_QBit_Wegimpuls_VL 0;
BA_ "GenSigStartValue" SG_ 278 ESP_QBit_Wegimpuls_VL 1;
BA_ "GenSigSwitchedByIgnition" SG_ 278 ESP_QBit_Wegimpuls_VL 0;
BA_ "GenSigSendType" SG_ 278 ESP_QBit_Wegimpuls_VR 0;
BA_ "GenSigStartValue" SG_ 278 ESP_QBit_Wegimpuls_VR 1;
BA_ "GenSigSwitchedByIgnition" SG_ 278 ESP_QBit_Wegimpuls_VR 0;
BA_ "GenSigSendType" SG_ 278 ESP_VL_Fahrtrichtung 0;
BA_ "GenSigStartValue" SG_ 278 ESP_VL_Fahrtrichtung 2;
BA_ "GenSigSwitchedByIgnition" SG_ 278 ESP_VL_Fahrtrichtung 0;
BA_ "GenSigSendType" SG_ 278 ESP_VR_Fahrtrichtung 0;
BA_ "GenSigStartValue" SG_ 278 ESP_VR_Fahrtrichtung 2;
BA_ "GenSigSwitchedByIgnition" SG_ 278 ESP_VR_Fahrtrichtung 0;
BA_ "GenSigSendType" SG_ 278 ESP_Wegimpuls_HL 0;
BA_ "GenSigStartValue" SG_ 278 ESP_Wegimpuls_HL 1021;
BA_ "GenSigSwitchedByIgnition" SG_ 278 ESP_Wegimpuls_HL 0;
BA_ "Fehlerwert" SG_ 278 ESP_Wegimpuls_HL 1023;
BA_ "GenSigSendType" SG_ 278 ESP_Wegimpuls_HR 0;
BA_ "GenSigStartValue" SG_ 278 ESP_Wegimpuls_HR 1021;
BA_ "GenSigSwitchedByIgnition" SG_ 278 ESP_Wegimpuls_HR 0;
BA_ "Fehlerwert" SG_ 278 ESP_Wegimpuls_HR 1023;
BA_ "GenSigSendType" SG_ 278 ESP_Wegimpuls_VL 0;
BA_ "GenSigStartValue" SG_ 278 ESP_Wegimpuls_VL 1021;
BA_ "GenSigSwitchedByIgnition" SG_ 278 ESP_Wegimpuls_VL 0;
BA_ "Fehlerwert" SG_ 278 ESP_Wegimpuls_VL 1023;
BA_ "GenSigSendType" SG_ 278 ESP_Wegimpuls_VR 0;
BA_ "GenSigStartValue" SG_ 278 ESP_Wegimpuls_VR 1021;
BA_ "GenSigSwitchedByIgnition" SG_ 278 ESP_Wegimpuls_VR 0;
BA_ "Fehlerwert" SG_ 278 ESP_Wegimpuls_VR 1023;
BA_ "GenSigSendType" SG_ 1629 BR_QBit_Reifenumfang 0;
BA_ "GenSigStartValue" SG_ 1629 BR_QBit_Reifenumfang 1;
BA_ "GenSigSwitchedByIgnition" SG_ 1629 BR_QBit_Reifenumfang 0;
BA_ "GenSigSendType" SG_ 1629 BR_Reifenumfang 0;
BA_ "GenSigSwitchedByIgnition" SG_ 1629 BR_Reifenumfang 0;
BA_ "GenSigSendType" SG_ 1629 BR_Systemart 0;
BA_ "GenSigFuncType" SG_ 1629 BR_Systemart 8;
BA_ "GenSigSwitchedByIgnition" SG_ 1629 BR_Systemart 0;
BA_ "GenSigSendType" SG_ 1629 ESP_20_BZ 0;
BA_ "GenSigFuncType" SG_ 1629 ESP_20_BZ 1;
BA_ "GenSigSwitchedByIgnition" SG_ 1629 ESP_20_BZ 0;
BA_ "GenSigSendType" SG_ 1629 ESP_20_CRC 0;
BA_ "GenSigFuncType" SG_ 1629 ESP_20_CRC 2;
BA_ "GenSigSwitchedByIgnition" SG_ 1629 ESP_20_CRC 0;
BA_ "GenSigSendType" SG_ 1629 ESP_Charisma_FahrPr 3;
BA_ "GenSigSwitchedByIgnition" SG_ 1629 ESP_Charisma_FahrPr 0;
BA_ "GenSigSendType" SG_ 1629 ESP_Charisma_Status 3;
BA_ "GenSigSwitchedByIgnition" SG_ 1629 ESP_Charisma_Status 0;
BA_ "GenSigSendType" SG_ 1629 ESP_Dachrelingsensor 0;
BA_ "GenSigSwitchedByIgnition" SG_ 1629 ESP_Dachrelingsensor 0;
BA_ "Fehlerwert" SG_ 1629 ESP_Dachrelingsensor 3;
BA_ "GenSigSendType" SG_ 1629 ESP_SpannungsAnf_02 3;
BA_ "GenSigSwitchedByIgnition" SG_ 1629 ESP_SpannungsAnf_02 0;
BA_ "GenSigSendType" SG_ 1629 ESP_Stoppverbot_Anz_01 3;
BA_ "GenSigSwitchedByIgnition" SG_ 1629 ESP_Stoppverbot_Anz_01 0;
BA_ "GenSigSendType" SG_ 1629 ESP_Stoppverbot_Anz_02 3;
BA_ "GenSigSwitchedByIgnition" SG_ 1629 ESP_Stoppverbot_Anz_02 0;
BA_ "GenSigSendType" SG_ 1629 ESP_Stoppverbot_Anz_03 3;
BA_ "GenSigSwitchedByIgnition" SG_ 1629 ESP_Stoppverbot_Anz_03 0;
BA_ "GenSigSendType" SG_ 1629 ESP_Stoppverbot_Anz_04 3;
BA_ "GenSigSwitchedByIgnition" SG_ 1629 ESP_Stoppverbot_Anz_04 0;
BA_ "GenSigSendType" SG_ 1629 ESP_Stoppverbot_Anz_05 3;
BA_ "GenSigSwitchedByIgnition" SG_ 1629 ESP_Stoppverbot_Anz_05 0;
BA_ "GenSigSendType" SG_ 1629 ESP_Stoppverbot_Anz_06 3;
BA_ "GenSigSwitchedByIgnition" SG_ 1629 ESP_Stoppverbot_Anz_06 0;
BA_ "GenSigSendType" SG_ 1629 ESP_Stoppverbot_Anz_07 3;
BA_ "GenSigSwitchedByIgnition" SG_ 1629 ESP_Stoppverbot_Anz_07 0;
BA_ "GenSigSendType" SG_ 1629 ESP_Stoppverbot_Anz_08 3;
BA_ "GenSigSwitchedByIgnition" SG_ 1629 ESP_Stoppverbot_Anz_08 0;
BA_ "GenSigSendType" SG_ 1629 ESP_Stoppverbot_Anz_Std 3;
BA_ "GenSigSwitchedByIgnition" SG_ 1629 ESP_Stoppverbot_Anz_Std 0;
BA_ "GenSigSendType" SG_ 1629 ESP_Wiederstart_Anz_01 3;
BA_ "GenSigSwitchedByIgnition" SG_ 1629 ESP_Wiederstart_Anz_01 0;
BA_ "GenSigSendType" SG_ 1629 ESP_Wiederstart_Anz_02 3;
BA_ "GenSigSwitchedByIgnition" SG_ 1629 ESP_Wiederstart_Anz_02 0;
BA_ "GenSigSendType" SG_ 1629 ESP_Wiederstart_Anz_03 3;
BA_ "GenSigSwitchedByIgnition" SG_ 1629 ESP_Wiederstart_Anz_03 0;
BA_ "GenSigSendType" SG_ 1629 ESP_Wiederstart_Anz_04 3;
BA_ "GenSigSwitchedByIgnition" SG_ 1629 ESP_Wiederstart_Anz_04 0;
BA_ "GenSigSendType" SG_ 1629 ESP_Zaehnezahl 0;
BA_ "GenSigFuncType" SG_ 1629 ESP_Zaehnezahl 8;
BA_ "GenSigSwitchedByIgnition" SG_ 1629 ESP_Zaehnezahl 0;
BA_ "GenSigSendType" SG_ 1629 HDC_Charisma_FahrPr 3;
BA_ "GenSigSwitchedByIgnition" SG_ 1629 HDC_Charisma_FahrPr 0;
BA_ "GenSigSendType" SG_ 1629 HDC_Charisma_Status 3;
BA_ "GenSigSwitchedByIgnition" SG_ 1629 HDC_Charisma_Status 0;
BA_ "GenSigSendType" SG_ 253 ABS_Bremsung 0;
BA_ "GenSigSwitchedByIgnition" SG_ 253 ABS_Bremsung 0;
BA_ "GenSigSendType" SG_ 253 ASR_Anf 0;
BA_ "GenSigSwitchedByIgnition" SG_ 253 ASR_Anf 0;
BA_ "GenSigSendType" SG_ 253 ASR_Schalteingriff 0;
BA_ "GenSigSwitchedByIgnition" SG_ 253 ASR_Schalteingriff 0;
BA_ "GenSigSendType" SG_ 253 ASR_Tastung_passiv 0;
BA_ "GenSigSwitchedByIgnition" SG_ 253 ASR_Tastung_passiv 0;
BA_ "GenSigSendType" SG_ 253 BR_Eingriffsmoment 0;
BA_ "GenSigStartValue" SG_ 253 BR_Eingriffsmoment 1022;
BA_ "GenSigSwitchedByIgnition" SG_ 253 BR_Eingriffsmoment 0;
BA_ "Fehlerwert" SG_ 253 BR_Eingriffsmoment 1023;
BA_ "GenSigSendType" SG_ 253 EBV_Eingriff 0;
BA_ "GenSigSwitchedByIgnition" SG_ 253 EBV_Eingriff 0;
BA_ "GenSigSendType" SG_ 253 EDS_Eingriff 0;
BA_ "GenSigSwitchedByIgnition" SG_ 253 EDS_Eingriff 0;
BA_ "GenSigSendType" SG_ 253 ESC_Reku_Freigabe 0;
BA_ "GenSigSwitchedByIgnition" SG_ 253 ESC_Reku_Freigabe 0;
BA_ "GenSigSendType" SG_ 253 ESC_v_Signal_Qualifier_High_Low 0;
BA_ "GenSigStartValue" SG_ 253 ESC_v_Signal_Qualifier_High_Low 6;
BA_ "GenSigSwitchedByIgnition" SG_ 253 ESC_v_Signal_Qualifier_High_Low 0;
BA_ "Fehlerwert" SG_ 253 ESC_v_Signal_Qualifier_High_Low 7;
BA_ "GenSigSendType" SG_ 253 ESP_21_BZ 0;
BA_ "GenSigFuncType" SG_ 253 ESP_21_BZ 1;
BA_ "GenSigSwitchedByIgnition" SG_ 253 ESP_21_BZ 0;
BA_ "GenSigSendType" SG_ 253 ESP_21_CRC 0;
BA_ "GenSigFuncType" SG_ 253 ESP_21_CRC 2;
BA_ "GenSigSwitchedByIgnition" SG_ 253 ESP_21_CRC 0;
BA_ "GenSigSendType" SG_ 253 ESP_Anhaltevorgang_ACC_aktiv 0;
BA_ "GenSigSwitchedByIgnition" SG_ 253 ESP_Anhaltevorgang_ACC_aktiv 0;
BA_ "GenSigSendType" SG_ 253 ESP_ASP 0;
BA_ "GenSigSwitchedByIgnition" SG_ 253 ESP_ASP 0;
BA_ "GenSigSendType" SG_ 253 ESP_AWV3_Brems_aktiv 0;
BA_ "GenSigSwitchedByIgnition" SG_ 253 ESP_AWV3_Brems_aktiv 0;
BA_ "GenSigSendType" SG_ 253 ESP_Diagnose 0;
BA_ "GenSigSwitchedByIgnition" SG_ 253 ESP_Diagnose 0;
BA_ "GenSigSendType" SG_ 253 ESP_Eingriff 0;
BA_ "GenSigSwitchedByIgnition" SG_ 253 ESP_Eingriff 0;
BA_ "GenSigSendType" SG_ 253 ESP_Haltebestaetigung 0;
BA_ "GenSigSwitchedByIgnition" SG_ 253 ESP_Haltebestaetigung 0;
BA_ "GenSigSendType" SG_ 253 ESP_MKB_Abbruch_Geschw 0;
BA_ "GenSigSwitchedByIgnition" SG_ 253 ESP_MKB_Abbruch_Geschw 0;
BA_ "GenSigSendType" SG_ 253 ESP_PLA_Bremseingriff 0;
BA_ "GenSigSwitchedByIgnition" SG_ 253 ESP_PLA_Bremseingriff 0;
BA_ "GenSigSendType" SG_ 253 ESP_QBit_v_Signal 0;
BA_ "GenSigStartValue" SG_ 253 ESP_QBit_v_Signal 1;
BA_ "GenSigSwitchedByIgnition" SG_ 253 ESP_QBit_v_Signal 0;
BA_ "GenSigSendType" SG_ 253 ESP_Systemstatus 0;
BA_ "GenSigSwitchedByIgnition" SG_ 253 ESP_Systemstatus 0;
BA_ "GenSigSendType" SG_ 253 ESP_Tastung_passiv 0;
BA_ "GenSigSwitchedByIgnition" SG_ 253 ESP_Tastung_passiv 0;
BA_ "GenSigSendType" SG_ 253 ESP_v_Signal 0;
BA_ "GenSigStartValue" SG_ 253 ESP_v_Signal 65534;
BA_ "GenSigSwitchedByIgnition" SG_ 253 ESP_v_Signal 0;
BA_ "Fehlerwert" SG_ 253 ESP_v_Signal 65535;
BA_ "GenSigMissingSourceValue" SG_ 253 ESP_v_Signal 65534;
BA_ "GenSigSendType" SG_ 253 ESP_Vorsteuerung 0;
BA_ "GenSigSwitchedByIgnition" SG_ 253 ESP_Vorsteuerung 0;
BA_ "GenSigSendType" SG_ 253 MSR_Anf 0;
BA_ "GenSigSwitchedByIgnition" SG_ 253 MSR_Anf 0;
BA_ "GenSigSendType" SG_ 253 OBD_QBit_Schlechtweg 0;
BA_ "GenSigStartValue" SG_ 253 OBD_QBit_Schlechtweg 1;
BA_ "GenSigSwitchedByIgnition" SG_ 253 OBD_QBit_Schlechtweg 0;
BA_ "GenSigSendType" SG_ 253 OBD_Schlechtweg 0;
BA_ "GenSigSwitchedByIgnition" SG_ 253 OBD_Schlechtweg 0;
BA_ "GenSigSendType" SG_ 2527679740 KBI_aktive_Laengsfunktion_02 3;
BA_ "GenSigSendType" SG_ 2527679740 KBI_Anzeigefehler_LDW 3;
BA_ "GenSigSwitchedByIgnition" SG_ 2527679740 KBI_Anzeigefehler_LDW 0;
BA_ "GenSigSendType" SG_ 2527679740 KBI_Anzeigestatus_ACC 3;
BA_ "GenSigSwitchedByIgnition" SG_ 2527679740 KBI_Anzeigestatus_ACC 0;
BA_ "GenSigSendType" SG_ 2527679740 KBI_Anzeigestatus_GRA 3;
BA_ "GenSigSwitchedByIgnition" SG_ 2527679740 KBI_Anzeigestatus_GRA 0;
BA_ "Fehlerwert" SG_ 2527679740 KBI_Anzeigestatus_GRA 3;
BA_ "GenSigSendType" SG_ 2527679740 KBI_Anzeigestatus_LIM 3;
BA_ "GenSigSwitchedByIgnition" SG_ 2527679740 KBI_Anzeigestatus_LIM 0;
BA_ "Fehlerwert" SG_ 2527679740 KBI_Anzeigestatus_LIM 3;
BA_ "GenSigSendType" SG_ 2527679740 KBI_Fehler_Anzeige_ACC 3;
BA_ "GenSigSwitchedByIgnition" SG_ 2527679740 KBI_Fehler_Anzeige_ACC 0;
BA_ "GenSigSendType" SG_ 2527679740 KBI_Konsistenz_ACC 3;
BA_ "GenSigSwitchedByIgnition" SG_ 2527679740 KBI_Konsistenz_ACC 0;
BA_ "GenSigSendType" SG_ 1605 FLA_Abblendursache 3;
BA_ "Fehlerwert" SG_ 1605 FLA_Abblendursache 255;
BA_ "GenSigSendType" SG_ 1605 FLA_aktiv 3;
BA_ "GenSigSendType" SG_ 1605 FLA_Aufblenden 3;
BA_ "GenSigSendType" SG_ 1605 FLA_Fernlicht_PWM 3;
BA_ "GenSigStartValue" SG_ 1605 FLA_Fernlicht_PWM 100;
BA_ "Fehlerwert" SG_ 1605 FLA_Fernlicht_PWM 127;
BA_ "GenSigSendType" SG_ 1605 FLA_ISP_defekt 3;
BA_ "GenSigSendType" SG_ 1605 FLA_SAE_Mode 3;
BA_ "GenSigSendType" SG_ 1605 FLA_Sensor_blockiert 3;
BA_ "GenSigSendType" SG_ 1605 ISP_EC_aktiv 3;
BA_ "GenSigStartValue" SG_ 1605 ISP_EC_aktiv 1;
BA_ "GenSigSendType" SG_ 1605 ISP_EC_Lichtwert_hinten 3;
BA_ "GenSigStartValue" SG_ 1605 ISP_EC_Lichtwert_hinten 62;
BA_ "Fehlerwert" SG_ 1605 ISP_EC_Lichtwert_hinten 63;
BA_ "GenSigSendType" SG_ 1605 ISP_EC_Lichtwert_vorne 3;
BA_ "GenSigStartValue" SG_ 1605 ISP_EC_Lichtwert_vorne 62;
BA_ "Fehlerwert" SG_ 1605 ISP_EC_Lichtwert_vorne 63;
BA_ "GenSigSendType" SG_ 1605 ISP_Himmelsrichtung 3;
BA_ "GenSigStartValue" SG_ 1605 ISP_Himmelsrichtung 30;
BA_ "Fehlerwert" SG_ 1605 ISP_Himmelsrichtung 31;
BA_ "GenSigSendType" SG_ 1605 ISP_Kompass_aktiv 3;
BA_ "GenSigStartValue" SG_ 1605 ISP_Kompass_aktiv 1;
BA_ "GenSigSendType" SG_ 1605 ISP_Taste_betaetigt 3;
BA_ "GenSigSendType" SG_ 2589283684 FoD_Anz_Funktionsabschaltung 3;
BA_ "GenSigSwitchedByIgnition" SG_ 2589283684 FoD_Anz_Funktionsabschaltung 0;
BA_ "GenSigSendType" SG_ 2589283684 FoD_State_IPA_RPA 0;
BA_ "GenSigSwitchedByIgnition" SG_ 2589283684 FoD_State_IPA_RPA 0;
BA_ "GenSigSendType" SG_ 2589283684 FoD_State_TopView_SideView_RVC 0;
BA_ "GenSigSwitchedByIgnition" SG_ 2589283684 FoD_State_TopView_SideView_RVC 0;
BA_ "GenSigSendType" SG_ 2589283684 FoD_State_TPA_rTPA 0;
BA_ "GenSigSwitchedByIgnition" SG_ 2589283684 FoD_State_TPA_rTPA 0;
BA_ "GenSigSendType" SG_ 2589283684 FoD_Transmission_Info 3;
BA_ "GenSigSwitchedByIgnition" SG_ 2589283684 FoD_Transmission_Info 0;
BA_ "GenSigSendType" SG_ 2589283684 GRA_FoD_Status 3;
BA_ "GenSigSwitchedByIgnition" SG_ 2589283684 GRA_FoD_Status 0;
BA_ "GenSigSendType" SG_ 2549875543 FoD_ACC_Req_Data 3;
BA_ "GenSigFuncType" SG_ 2549875543 FoD_ACC_Req_Data 9;
BA_ "GenSigSwitchedByIgnition" SG_ 2549875543 FoD_ACC_Req_Data 0;
BA_ "GenSigSendType" SG_ 2550006615 FoD_ACC_Resp_Data 3;
BA_ "GenSigFuncType" SG_ 2550006615 FoD_ACC_Resp_Data 9;
BA_ "GenSigSwitchedByIgnition" SG_ 2550006615 FoD_ACC_Resp_Data 0;
BA_ "GenSigSendType" SG_ 2549875535 FoD_Kamera_Req_Data 3;
BA_ "GenSigFuncType" SG_ 2549875535 FoD_Kamera_Req_Data 9;
BA_ "GenSigSwitchedByIgnition" SG_ 2549875535 FoD_Kamera_Req_Data 0;
BA_ "GenSigSendType" SG_ 2550006607 FoD_Kamera_Resp_Data 3;
BA_ "GenSigFuncType" SG_ 2550006607 FoD_Kamera_Resp_Data 9;
BA_ "GenSigSwitchedByIgnition" SG_ 2550006607 FoD_Kamera_Resp_Data 0;
BA_ "GenSigSendType" SG_ 987 AAG_Anhaenger_abgesteckt 0;
BA_ "GenSigSwitchedByIgnition" SG_ 987 AAG_Anhaenger_abgesteckt 0;
BA_ "GenSigSendType" SG_ 987 AAG_Anhaenger_erkannt 0;
BA_ "NWM-WakeupAllowed" SG_ 987 AAG_Anhaenger_erkannt 1;
BA_ "GenSigSwitchedByIgnition" SG_ 987 AAG_Anhaenger_erkannt 0;
BA_ "GenSigSendType" SG_ 987 AAG_LED_aktiv 0;
BA_ "GenSigSwitchedByIgnition" SG_ 987 AAG_LED_aktiv 0;
BA_ "GenSigSendType" SG_ 987 Anhaenger_01_alt 0;
BA_ "GenSigStartValue" SG_ 987 Anhaenger_01_alt 1;
BA_ "GenSigFuncType" SG_ 987 Anhaenger_01_alt 5;
BA_ "GenSigSwitchedByIgnition" SG_ 987 Anhaenger_01_alt 0;
BA_ "GenSigSendType" SG_ 987 BCM1_Aussen_Temp_ungef 0;
BA_ "GenSigStartValue" SG_ 987 BCM1_Aussen_Temp_ungef 254;
BA_ "GenSigSwitchedByIgnition" SG_ 987 BCM1_Aussen_Temp_ungef 0;
BA_ "Fehlerwert" SG_ 987 BCM1_Aussen_Temp_ungef 255;
BA_ "GenSigSendType" SG_ 987 BCM1_LDS_Stellung 3;
BA_ "Fehlerwert" SG_ 987 BCM1_LDS_Stellung 7;
BA_ "GenSigSendType" SG_ 987 BCM1_MH_Schalter 3;
BA_ "GenSigSwitchedByIgnition" SG_ 987 BCM1_MH_Schalter 0;
BA_ "GenSigSendType" SG_ 987 BCM1_OBD_FStatus_ATemp 0;
BA_ "GenSigSwitchedByIgnition" SG_ 987 BCM1_OBD_FStatus_ATemp 0;
BA_ "GenSigSendType" SG_ 987 BCM1_Rueckfahrlicht_Schalter 3;
BA_ "GenSigSwitchedByIgnition" SG_ 987 BCM1_Rueckfahrlicht_Schalter 0;
BA_ "GenSigSendType" SG_ 987 BCM_01_alt 0;
BA_ "GenSigStartValue" SG_ 987 BCM_01_alt 1;
BA_ "GenSigFuncType" SG_ 987 BCM_01_alt 5;
BA_ "GenSigSwitchedByIgnition" SG_ 987 BCM_01_alt 0;
BA_ "GenSigSendType" SG_ 987 BCM_Rueckfahrlicht_Anf 0;
BA_ "GenSigSendType" SG_ 987 BCM_Tankklappensteller_Fehler 0;
BA_ "Fehlerwert" SG_ 987 BCM_Tankklappensteller_Fehler 1;
BA_ "GenSigSendType" SG_ 987 BH_Blinker_li 3;
BA_ "GenSigSendType" SG_ 987 BH_Blinker_re 3;
BA_ "GenSigSendType" SG_ 987 BH_Fernlicht 3;
BA_ "GenSigSendType" SG_ 987 BH_Lichthupe 3;
BA_ "GenSigSendType" SG_ 987 KL_Thermomanagement 0;
BA_ "GenSigSendType" SG_ 987 Klima_11_alt 0;
BA_ "GenSigStartValue" SG_ 987 Klima_11_alt 1;
BA_ "GenSigFuncType" SG_ 987 Klima_11_alt 5;
BA_ "GenSigSwitchedByIgnition" SG_ 987 Klima_11_alt 0;
BA_ "GenSigSendType" SG_ 987 Klima_Sensor_02_alt 0;
BA_ "GenSigStartValue" SG_ 987 Klima_Sensor_02_alt 1;
BA_ "GenSigFuncType" SG_ 987 Klima_Sensor_02_alt 5;
BA_ "GenSigSwitchedByIgnition" SG_ 987 Klima_Sensor_02_alt 0;
BA_ "GenSigSendType" SG_ 987 Licht_Anf_01_alt 0;
BA_ "GenSigStartValue" SG_ 987 Licht_Anf_01_alt 1;
BA_ "GenSigFuncType" SG_ 987 Licht_Anf_01_alt 5;
BA_ "GenSigSwitchedByIgnition" SG_ 987 Licht_Anf_01_alt 0;
BA_ "GenSigSendType" SG_ 987 SMLS_01_alt 0;
BA_ "GenSigStartValue" SG_ 987 SMLS_01_alt 1;
BA_ "GenSigFuncType" SG_ 987 SMLS_01_alt 5;
BA_ "GenSigSwitchedByIgnition" SG_ 987 SMLS_01_alt 0;
BA_ "GenSigSendType" SG_ 987 Verdeck_01_alt 0;
BA_ "GenSigStartValue" SG_ 987 Verdeck_01_alt 1;
BA_ "GenSigFuncType" SG_ 987 Verdeck_01_alt 5;
BA_ "GenSigSwitchedByIgnition" SG_ 987 Verdeck_01_alt 0;
BA_ "GenSigSendType" SG_ 987 VS_VD_entriegelt 0;
BA_ "GenSigSendType" SG_ 987 VS_VD_offen_ver 0;
BA_ "GenSigSendType" SG_ 987 VS_VD_zu_ver 0;
BA_ "GenSigSendType" SG_ 987 VS_Verdeck_Anf 0;
BA_ "GenSigSendType" SG_ 987 Waschen_vorne_aktiv 3;
BA_ "GenSigSwitchedByIgnition" SG_ 987 Waschen_vorne_aktiv 0;
BA_ "GenSigSendType" SG_ 987 WFS_01_alt 0;
BA_ "GenSigStartValue" SG_ 987 WFS_01_alt 1;
BA_ "GenSigFuncType" SG_ 987 WFS_01_alt 5;
BA_ "GenSigSwitchedByIgnition" SG_ 987 WFS_01_alt 0;
BA_ "GenSigSendType" SG_ 987 WFS_ID_Geb_autorisiert_in_Kl15 0;
BA_ "GenSigSendType" SG_ 987 WFS_Klemmenfreigabe 0;
BA_ "GenSigSendType" SG_ 987 WFS_Schluessel_Fahrberecht 0;
BA_ "GenSigSendType" SG_ 987 Wischer_01_alt 0;
BA_ "GenSigStartValue" SG_ 987 Wischer_01_alt 1;
BA_ "GenSigFuncType" SG_ 987 Wischer_01_alt 5;
BA_ "GenSigSwitchedByIgnition" SG_ 987 Wischer_01_alt 0;
BA_ "GenSigSendType" SG_ 987 Wischer_vorne_aktiv 3;
BA_ "GenSigSwitchedByIgnition" SG_ 987 Wischer_vorne_aktiv 0;
BA_ "GenSigSendType" SG_ 987 WWSs_01_alt 3;
BA_ "GenSigStartValue" SG_ 987 WWSs_01_alt 1;
BA_ "GenSigFuncType" SG_ 987 WWSs_01_alt 5;
BA_ "GenSigSwitchedByIgnition" SG_ 987 WWSs_01_alt 0;
BA_ "GenSigSendType" SG_ 987 ZV_02_alt 0;
BA_ "GenSigStartValue" SG_ 987 ZV_02_alt 1;
BA_ "GenSigFuncType" SG_ 987 ZV_02_alt 5;
BA_ "GenSigSwitchedByIgnition" SG_ 987 ZV_02_alt 0;
BA_ "GenSigSendType" SG_ 987 ZV_BT_offen 3;
BA_ "GenSigSendType" SG_ 987 ZV_FT_offen 3;
BA_ "GenSigSendType" SG_ 987 ZV_HBFS_offen 3;
BA_ "GenSigSendType" SG_ 987 ZV_HD_offen 3;
BA_ "GenSigSendType" SG_ 987 ZV_HFS_offen 3;
BA_ "GenSigSendType" SG_ 987 ZV_Schluessel_Zugang 0;
BA_ "GenSigSendType" SG_ 987 ZV_Tankklappe_offen 0;
BA_ "GenSigSendType" SG_ 987 ZV_verriegelt_extern_soll 0;
BA_ "GenSigSendType" SG_ 987 ZV_verriegelt_soll 3;
BA_ "GenSigSendType" SG_ 988 ACC_18_alt 0;
BA_ "GenSigStartValue" SG_ 988 ACC_18_alt 1;
BA_ "GenSigFuncType" SG_ 988 ACC_18_alt 5;
BA_ "GenSigSendType" SG_ 988 ACC_Status_ACC 0;
BA_ "GenSigSendType" SG_ 988 EPB_Status_02 0;
BA_ "GenSigStartValue" SG_ 988 EPB_Status_02 6;
BA_ "GenSigSendType" SG_ 988 ESP_07_alt 0;
BA_ "GenSigStartValue" SG_ 988 ESP_07_alt 1;
BA_ "GenSigFuncType" SG_ 988 ESP_07_alt 5;
BA_ "GenSigSwitchedByIgnition" SG_ 988 ESP_07_alt 0;
BA_ "GenSigSendType" SG_ 988 ESP_50_alt 0;
BA_ "GenSigStartValue" SG_ 988 ESP_50_alt 1;
BA_ "GenSigFuncType" SG_ 988 ESP_50_alt 5;
BA_ "GenSigSendType" SG_ 988 ESP_Rollenmodus_Deaktivieren 0;
BA_ "GenSigSwitchedByIgnition" SG_ 988 ESP_Rollenmodus_Deaktivieren 0;
BA_ "GenSigSendType" SG_ 988 ESP_Status_Bremsentemp_02 0;
BA_ "GenSigSendType" SG_ 988 GE_Fahrstufe 3;
BA_ "GenSigStartValue" SG_ 988 GE_Fahrstufe 1;
BA_ "GenSigSwitchedByIgnition" SG_ 988 GE_Fahrstufe 0;
BA_ "Fehlerwert" SG_ 988 GE_Fahrstufe 15;
BA_ "GenSigSendType" SG_ 988 GE_Freilauf_Status 0;
BA_ "Fehlerwert" SG_ 988 GE_Freilauf_Status 7;
BA_ "GenSigSendType" SG_ 988 GE_Notlauf 3;
BA_ "GenSigSendType" SG_ 988 GE_Sperr_Info_WFS 3;
BA_ "GenSigSendType" SG_ 988 GE_Ursache_Fahrstufe_N 0;
BA_ "GenSigSendType" SG_ 988 Getriebe_11_alt 0;
BA_ "GenSigStartValue" SG_ 988 Getriebe_11_alt 1;
BA_ "GenSigFuncType" SG_ 988 Getriebe_11_alt 5;
BA_ "GenSigSwitchedByIgnition" SG_ 988 Getriebe_11_alt 0;
BA_ "GenSigSendType" SG_ 988 Getriebe_13_alt 0;
BA_ "GenSigStartValue" SG_ 988 Getriebe_13_alt 1;
BA_ "GenSigFuncType" SG_ 988 Getriebe_13_alt 5;
BA_ "GenSigSendType" SG_ 988 Getriebe_14_alt 0;
BA_ "GenSigStartValue" SG_ 988 Getriebe_14_alt 1;
BA_ "GenSigFuncType" SG_ 988 Getriebe_14_alt 5;
BA_ "GenSigSendType" SG_ 988 Getriebe_17_alt 0;
BA_ "GenSigStartValue" SG_ 988 Getriebe_17_alt 1;
BA_ "GenSigFuncType" SG_ 988 Getriebe_17_alt 5;
BA_ "GenSigSendType" SG_ 988 MKE_Stufe 0;
BA_ "GenSigSendType" SG_ 988 MKE_Texte 0;
BA_ "GenSigSendType" SG_ 988 MO_Drehzahl_01 0;
BA_ "GenSigSendType" SG_ 988 MO_QBit_Drehzahl_01 0;
BA_ "GenSigStartValue" SG_ 988 MO_QBit_Drehzahl_01 1;
BA_ "GenSigSwitchedByIgnition" SG_ 988 MO_QBit_Drehzahl_01 0;
BA_ "GenSigSendType" SG_ 988 Motor_12_alt 0;
BA_ "GenSigStartValue" SG_ 988 Motor_12_alt 1;
BA_ "GenSigFuncType" SG_ 988 Motor_12_alt 5;
BA_ "GenSigSwitchedByIgnition" SG_ 988 Motor_12_alt 0;
BA_ "GenSigSendType" SG_ 988 TSK_06_alt 0;
BA_ "GenSigStartValue" SG_ 988 TSK_06_alt 1;
BA_ "GenSigSwitchedByIgnition" SG_ 988 TSK_06_alt 0;
BA_ "GenSigSendType" SG_ 988 TSK_Hauptschalter_GRA_ACC 0;
BA_ "GenSigSwitchedByIgnition" SG_ 988 TSK_Hauptschalter_GRA_ACC 0;
BA_ "Fehlerwert" SG_ 988 TSK_Hauptschalter_GRA_ACC 3;
BA_ "GenSigSendType" SG_ 988 TSK_Limiter_ausgewaehlt 0;
BA_ "GenSigSwitchedByIgnition" SG_ 988 TSK_Limiter_ausgewaehlt 0;
BA_ "GenSigSendType" SG_ 173 GE_Fahrstufe 0;
BA_ "GenSigStartValue" SG_ 173 GE_Fahrstufe 1;
BA_ "GenSigSwitchedByIgnition" SG_ 173 GE_Fahrstufe 0;
BA_ "Fehlerwert" SG_ 173 GE_Fahrstufe 15;
BA_ "GenSigSendType" SG_ 173 GE_Freig_MMom_Vorhalt 0;
BA_ "GenSigSwitchedByIgnition" SG_ 173 GE_Freig_MMom_Vorhalt 0;
BA_ "GenSigSendType" SG_ 173 GE_MMom_Soll_02 0;
BA_ "GenSigStartValue" SG_ 173 GE_MMom_Soll_02 1022;
BA_ "GenSigSwitchedByIgnition" SG_ 173 GE_MMom_Soll_02 0;
BA_ "Fehlerwert" SG_ 173 GE_MMom_Soll_02 1023;
BA_ "GenSigSendType" SG_ 173 GE_MMom_Status 0;
BA_ "GenSigSwitchedByIgnition" SG_ 173 GE_MMom_Status 0;
BA_ "GenSigSendType" SG_ 173 GE_MMom_Status_02 0;
BA_ "GenSigSwitchedByIgnition" SG_ 173 GE_MMom_Status_02 0;
BA_ "GenSigSendType" SG_ 173 GE_MMom_Vorhalt_02 0;
BA_ "GenSigStartValue" SG_ 173 GE_MMom_Vorhalt_02 1022;
BA_ "GenSigSwitchedByIgnition" SG_ 173 GE_MMom_Vorhalt_02 0;
BA_ "Fehlerwert" SG_ 173 GE_MMom_Vorhalt_02 1023;
BA_ "GenSigSendType" SG_ 173 GE_Schaltablauf 0;
BA_ "GenSigSwitchedByIgnition" SG_ 173 GE_Schaltablauf 0;
BA_ "GenSigSendType" SG_ 173 GE_Status_Kraftschluss 0;
BA_ "GenSigSwitchedByIgnition" SG_ 173 GE_Status_Kraftschluss 0;
BA_ "GenSigSendType" SG_ 173 GE_Uefkt 0;
BA_ "GenSigSwitchedByIgnition" SG_ 173 GE_Uefkt 0;
BA_ "Fehlerwert" SG_ 173 GE_Uefkt 1023;
BA_ "GenSigSendType" SG_ 173 GE_Uefkt_unplausibel 0;
BA_ "GenSigSwitchedByIgnition" SG_ 173 GE_Uefkt_unplausibel 0;
BA_ "GenSigSendType" SG_ 173 GE_Ursache_Fahrstufe_N 0;
BA_ "GenSigSwitchedByIgnition" SG_ 173 GE_Ursache_Fahrstufe_N 0;
BA_ "GenSigSendType" SG_ 173 GE_Verbot_Ausblendung 0;
BA_ "GenSigSwitchedByIgnition" SG_ 173 GE_Verbot_Ausblendung 0;
BA_ "GenSigSendType" SG_ 173 GE_Zielgang 0;
BA_ "GenSigSwitchedByIgnition" SG_ 173 GE_Zielgang 0;
BA_ "Fehlerwert" SG_ 173 GE_Zielgang 15;
BA_ "GenSigSendType" SG_ 173 Getriebe_11_BZ 0;
BA_ "GenSigFuncType" SG_ 173 Getriebe_11_BZ 1;
BA_ "GenSigSwitchedByIgnition" SG_ 173 Getriebe_11_BZ 0;
BA_ "GenSigSendType" SG_ 173 Getriebe_11_CRC 0;
BA_ "GenSigFuncType" SG_ 173 Getriebe_11_CRC 2;
BA_ "GenSigSwitchedByIgnition" SG_ 173 Getriebe_11_CRC 0;
BA_ "GenSigSendType" SG_ 2463978722 GNSS_DR_Breite_Ortung 0;
BA_ "GenSigStartValue" SG_ 2463978722 GNSS_DR_Breite_Ortung 134217726;
BA_ "GenSigSwitchedByIgnition" SG_ 2463978722 GNSS_DR_Breite_Ortung 0;
BA_ "Fehlerwert" SG_ 2463978722 GNSS_DR_Breite_Ortung 134217727;
BA_ "GenSigSendType" SG_ 2463978722 GNSS_DR_Laenge_Ortung 0;
BA_ "GenSigStartValue" SG_ 2463978722 GNSS_DR_Laenge_Ortung 268435454;
BA_ "GenSigSwitchedByIgnition" SG_ 2463978722 GNSS_DR_Laenge_Ortung 0;
BA_ "Fehlerwert" SG_ 2463978722 GNSS_DR_Laenge_Ortung 268435455;
BA_ "GenSigSendType" SG_ 2463978722 GNSS_DR_Nachrichtenpaket_ID1 0;
BA_ "GenSigSwitchedByIgnition" SG_ 2463978722 GNSS_DR_Nachrichtenpaket_ID1 0;
BA_ "GenSigSendType" SG_ 2463978722 GNSS_DR_Richtung_Breite_Ortung 0;
BA_ "GenSigStartValue" SG_ 2463978722 GNSS_DR_Richtung_Breite_Ortung 1;
BA_ "GenSigSwitchedByIgnition" SG_ 2463978722 GNSS_DR_Richtung_Breite_Ortung 0;
BA_ "GenSigSendType" SG_ 2463978722 GNSS_DR_Richtung_Laenge_Ortung 0;
BA_ "GenSigStartValue" SG_ 2463978722 GNSS_DR_Richtung_Laenge_Ortung 1;
BA_ "GenSigSwitchedByIgnition" SG_ 2463978722 GNSS_DR_Richtung_Laenge_Ortung 0;
BA_ "GenSigSendType" SG_ 2463978723 GNSS_DR_Nachrichtenpaket_ID2 0;
BA_ "GenSigSwitchedByIgnition" SG_ 2463978723 GNSS_DR_Nachrichtenpaket_ID2 0;
BA_ "GenSigSendType" SG_ 2463978723 GNSS_DR_Ortung_2D_Geschw_u_Grund 0;
BA_ "GenSigStartValue" SG_ 2463978723 GNSS_DR_Ortung_2D_Geschw_u_Grund 510;
BA_ "GenSigSwitchedByIgnition" SG_ 2463978723 GNSS_DR_Ortung_2D_Geschw_u_Grund 0;
BA_ "Fehlerwert" SG_ 2463978723 GNSS_DR_Ortung_2D_Geschw_u_Grund 511;
BA_ "GenSigSendType" SG_ 2463978723 GNSS_DR_Ortung_Ausrichtung 0;
BA_ "GenSigStartValue" SG_ 2463978723 GNSS_DR_Ortung_Ausrichtung 4094;
BA_ "GenSigSwitchedByIgnition" SG_ 2463978723 GNSS_DR_Ortung_Ausrichtung 0;
BA_ "Fehlerwert" SG_ 2463978723 GNSS_DR_Ortung_Ausrichtung 4095;
BA_ "GenSigSendType" SG_ 299 GRA_Abbrechen 0;
BA_ "GenSigSendType" SG_ 299 GRA_ACC_01_BZ 0;
BA_ "GenSigFuncType" SG_ 299 GRA_ACC_01_BZ 1;
BA_ "GenSigSendType" SG_ 299 GRA_ACC_01_CRC 0;
BA_ "GenSigFuncType" SG_ 299 GRA_ACC_01_CRC 2;
BA_ "GenSigSendType" SG_ 299 GRA_Codierung 0;
BA_ "GenSigSendType" SG_ 299 GRA_Fehler 0;
BA_ "Fehlerwert" SG_ 299 GRA_Fehler 1;
BA_ "GenSigSendType" SG_ 299 GRA_Hauptschalter 0;
BA_ "GenSigSendType" SG_ 299 GRA_LIM_Taste_verfuegbar 0;
BA_ "GenSigFuncType" SG_ 299 GRA_LIM_Taste_verfuegbar 8;
BA_ "GenSigSendType" SG_ 299 GRA_Limiter 0;
BA_ "GenSigSendType" SG_ 299 GRA_PIT_Limiter 0;
BA_ "GenSigSwitchedByIgnition" SG_ 299 GRA_PIT_Limiter 0;
BA_ "GenSigSendType" SG_ 299 GRA_reserveByte5 0;
BA_ "GenSigSendType" SG_ 299 GRA_reserveByte6 0;
BA_ "GenSigSendType" SG_ 299 GRA_reserveByte7 0;
BA_ "GenSigSendType" SG_ 299 GRA_reserveByte8 0;
BA_ "GenSigSendType" SG_ 299 GRA_Tip_Hoch 0;
BA_ "GenSigSendType" SG_ 299 GRA_Tip_Runter 0;
BA_ "GenSigSendType" SG_ 299 GRA_Tip_Setzen 0;
BA_ "GenSigSendType" SG_ 299 GRA_Tip_Stufe_2 0;
BA_ "GenSigSendType" SG_ 299 GRA_Tip_Wiederaufnahme 0;
BA_ "GenSigSendType" SG_ 299 GRA_TravelAssist 0;
BA_ "GenSigSwitchedByIgnition" SG_ 299 GRA_TravelAssist 0;
BA_ "GenSigSendType" SG_ 299 GRA_Typ_Bedienteil 0;
BA_ "GenSigSendType" SG_ 299 GRA_Typ_Hauptschalter 0;
BA_ "GenSigSendType" SG_ 299 GRA_Verstellung_Zeitluecke 0;
BA_ "GenSigSendType" SG_ 294 HCA_01_BZ 0;
BA_ "GenSigFuncType" SG_ 294 HCA_01_BZ 1;
BA_ "GenSigSendType" SG_ 294 HCA_01_CRC 0;
BA_ "GenSigFuncType" SG_ 294 HCA_01_CRC 2;
BA_ "GenSigSendType" SG_ 294 HCA_01_LM_Offset 0;
BA_ "GenSigSendType" SG_ 294 HCA_01_LM_OffSign 0;
BA_ "GenSigSendType" SG_ 294 HCA_01_Sendestatus 5;
BA_ "GenSigSendType" SG_ 294 HCA_01_Status_HCA 0;
BA_ "GenSigSendType" SG_ 294 HCA_01_Vib_Amp 0;
BA_ "GenSigSendType" SG_ 294 HCA_01_Vib_Freq 0;
BA_ "GenSigSendType" SG_ 771 FoD_DTC_TPA_rTPA_MFK 0;
BA_ "GenSigSwitchedByIgnition" SG_ 771 FoD_DTC_TPA_rTPA_MFK 0;
BA_ "GenSigSendType" SG_ 771 HCA_03_Sendestatus 6;
BA_ "GenSigSendType" SG_ 771 HCA_QFK_AnfStat 0;
BA_ "GenSigStartValue" SG_ 771 HCA_QFK_AnfStat 1;
BA_ "GenSigSendType" SG_ 771 HCA_QFK_Art1 0;
BA_ "GenSigSendType" SG_ 771 HCA_QFK_Art2 0;
BA_ "GenSigSendType" SG_ 771 HCA_QFK_KrSoll 0;
BA_ "GenSigStartValue" SG_ 771 HCA_QFK_KrSoll 65535;
BA_ "GenSigSendType" SG_ 771 HCA_QFK_KrSoll_VZ 0;
BA_ "GenSigSendType" SG_ 771 HCA_QFK_KruemmSoll 0;
BA_ "GenSigSendType" SG_ 771 HCA_QFK_KruemmSoll_VZ 0;
BA_ "GenSigSendType" SG_ 771 HCA_QFK_Signal1 0;
BA_ "GenSigSendType" SG_ 771 HCA_QFK_Signal2 0;
BA_ "GenSigSendType" SG_ 771 HCA_QFK_Spuerb 0;
BA_ "GenSigSendType" SG_ 771 SOK_HCA_03_Signatur 0;
BA_ "GenSigFuncType" SG_ 771 SOK_HCA_03_Signatur 15;
BA_ "GenSigSwitchedByIgnition" SG_ 771 SOK_HCA_03_Signatur 0;
BA_REL_ "GenSigTimeoutTime" BU_SG_REL_ FASFrontradar SG_ 258 ESC_50_CRC 500;
BA_REL_ "GenSigTimeoutTime" BU_SG_REL_ FASFrontradar SG_ 258 ESC_50_BZ 500;
BA_REL_ "GenSigTimeoutTime" BU_SG_REL_ FASFrontradar SG_ 258 ESP_QBit_Gierrate 500;
BA_REL_ "GenSigTimeoutTime" BU_SG_REL_ FASFrontradar SG_ 258 ESP_QBit_Laengsbeschl 500;
BA_REL_ "GenSigTimeoutTime" BU_SG_REL_ FASFrontradar SG_ 258 ESP_QBit_Querb 500;
BA_REL_ "GenSigTimeoutTime" BU_SG_REL_ FASFrontradar SG_ 258 ESP_Querbeschleunigung 500;
BA_REL_ "GenSigTimeoutTime" BU_SG_REL_ FASFrontradar SG_ 258 ESP_Laengsbeschl 500;
BA_REL_ "GenSigTimeoutTime" BU_SG_REL_ FASFrontradar SG_ 258 ESP_Gierrate 500;
BA_REL_ "GenSigTimeoutTime" BU_SG_REL_ FASFrontradar SG_ 258 ESP_VZ_Gierrate 500;
BA_REL_ "GenSigTimeoutTime" BU_SG_REL_ FASFrontradar SG_ 258 ESP_QBit_Bremsdruck 500;
BA_REL_ "GenSigTimeoutTime" BU_SG_REL_ FASFrontradar SG_ 258 ESP_Bremsdruck 500;
BA_REL_ "GenSigTimeoutTime" BU_SG_REL_ FASFrontradar SG_ 258 ESP_Autohold_Standby 500;
BA_REL_ "GenSigTimeoutTime" BU_SG_REL_ FASFrontradar SG_ 258 ESC_QBit_Fahrerbremswunsch 500;
BA_REL_ "GenSigTimeoutTime" BU_SG_REL_ FASFrontradar SG_ 258 ESC_Fahrerbremswunsch 500;
BA_REL_ "GenSigTimeoutTime" BU_SG_REL_ FASFrontradar SG_ 258 EPB_Schalterposition 500;
BA_REL_ "GenSigTimeoutTime" BU_SG_REL_ FASFrontradar SG_ 258 EPB_QBit_Schalterpos 500;
BA_REL_ "GenSigTimeoutTime" BU_SG_REL_ FASFrontradar SG_ 258 EPB_Status_02 500;
BA_REL_ "GenSigTimeoutTime" BU_SG_REL_ FASFrontradar SG_ 258 ESP_Status_Bremsentemp_02 500;
BA_REL_ "GenSigTimeoutTime" BU_SG_REL_ FASFrontradar SG_ 252 ESC_51_CRC 500;
BA_REL_ "GenSigTimeoutTime" BU_SG_REL_ FASFrontradar SG_ 252 ESC_51_BZ 500;
BA_REL_ "GenSigTimeoutTime" BU_SG_REL_ FASFrontradar SG_ 252 ESP_HL_Radgeschw_02 500;
BA_REL_ "GenSigTimeoutTime" BU_SG_REL_ FASFrontradar SG_ 252 ESP_HR_Radgeschw_02 500;
BA_REL_ "GenSigTimeoutTime" BU_SG_REL_ FASFrontradar SG_ 252 ESP_VL_Radgeschw_02 500;
BA_REL_ "GenSigTimeoutTime" BU_SG_REL_ FASFrontradar SG_ 252 ESP_VR_Radgeschw_02 500;
BA_REL_ "GenSigTimeoutTime" BU_SG_REL_ FASFrontradar SG_ 252 ESP_FZR_uebersteuern 500;
BA_REL_ "GenSigTimeoutTime" BU_SG_REL_ FASFrontradar SG_ 252 ESP_FZR_untersteuern 500;
BA_REL_ "GenSigTimeoutTime" BU_SG_REL_ FASFrontradar SG_ 252 ESC_GMV_aktiv 500;
BA_REL_ "GenSigTimeoutTime" BU_SG_REL_ FASFrontradar SG_ 278 ESP_10_CRC 500;
BA_REL_ "GenSigTimeoutTime" BU_SG_REL_ FASFrontradar SG_ 278 ESP_10_BZ 500;
BA_REL_ "GenSigTimeoutTime" BU_SG_REL_ FASFrontradar SG_ 278 ESP_QBit_Wegimpuls_VL 500;
BA_REL_ "GenSigTimeoutTime" BU_SG_REL_ FASFrontradar SG_ 278 ESP_QBit_Wegimpuls_VR 500;
BA_REL_ "GenSigTimeoutTime" BU_SG_REL_ FASFrontradar SG_ 278 ESP_QBit_Wegimpuls_HL 500;
BA_REL_ "GenSigTimeoutTime" BU_SG_REL_ FASFrontradar SG_ 278 ESP_QBit_Wegimpuls_HR 500;
BA_REL_ "GenSigTimeoutTime" BU_SG_REL_ FASFrontradar SG_ 278 ESP_Wegimpuls_VL 500;
BA_REL_ "GenSigTimeoutTime" BU_SG_REL_ FASFrontradar SG_ 278 ESP_Wegimpuls_VR 500;
BA_REL_ "GenSigTimeoutTime" BU_SG_REL_ FASFrontradar SG_ 278 ESP_Wegimpuls_HL 500;
BA_REL_ "GenSigTimeoutTime" BU_SG_REL_ FASFrontradar SG_ 278 ESP_Wegimpuls_HR 500;
BA_REL_ "GenSigTimeoutTime" BU_SG_REL_ FASFrontradar SG_ 278 ESP_VL_Fahrtrichtung 500;
BA_REL_ "GenSigTimeoutTime" BU_SG_REL_ FASFrontradar SG_ 278 ESP_VR_Fahrtrichtung 500;
BA_REL_ "GenSigTimeoutTime" BU_SG_REL_ FASFrontradar SG_ 278 ESP_HL_Fahrtrichtung 500;
BA_REL_ "GenSigTimeoutTime" BU_SG_REL_ FASFrontradar SG_ 278 ESP_HR_Fahrtrichtung 500;
BA_REL_ "GenSigTimeoutTime" BU_SG_REL_ FASFrontradar SG_ 1629 ESP_Zaehnezahl 5000;
BA_REL_ "GenSigTimeoutTime" BU_SG_REL_ FASFrontradar SG_ 253 ESP_21_CRC 500;
BA_REL_ "GenSigTimeoutTime" BU_SG_REL_ FASFrontradar SG_ 253 ESP_21_BZ 500;
BA_REL_ "GenSigTimeoutTime" BU_SG_REL_ FASFrontradar SG_ 253 ESP_Diagnose 500;
BA_REL_ "GenSigTimeoutTime" BU_SG_REL_ FASFrontradar SG_ 253 ESC_v_Signal_Qualifier_High_Low 500;
BA_REL_ "GenSigTimeoutTime" BU_SG_REL_ FASFrontradar SG_ 253 ESP_Vorsteuerung 500;
BA_REL_ "GenSigTimeoutTime" BU_SG_REL_ FASFrontradar SG_ 253 ESP_v_Signal 500;
BA_REL_ "GenSigTimeoutTime" BU_SG_REL_ FASFrontradar SG_ 253 ASR_Tastung_passiv 500;
BA_REL_ "GenSigTimeoutTime" BU_SG_REL_ FASFrontradar SG_ 253 ESP_Tastung_passiv 500;
BA_REL_ "GenSigTimeoutTime" BU_SG_REL_ FASFrontradar SG_ 253 ESP_Systemstatus 500;
BA_REL_ "GenSigTimeoutTime" BU_SG_REL_ FASFrontradar SG_ 253 ESP_QBit_v_Signal 500;
BA_REL_ "GenSigTimeoutTime" BU_SG_REL_ FASFrontradar SG_ 253 ABS_Bremsung 500;
BA_REL_ "GenSigTimeoutTime" BU_SG_REL_ FASFrontradar SG_ 253 ASR_Anf 500;
BA_REL_ "GenSigTimeoutTime" BU_SG_REL_ FASFrontradar SG_ 253 MSR_Anf 500;
BA_REL_ "GenSigTimeoutTime" BU_SG_REL_ FASFrontradar SG_ 253 EBV_Eingriff 500;
BA_REL_ "GenSigTimeoutTime" BU_SG_REL_ FASFrontradar SG_ 253 EDS_Eingriff 500;
BA_REL_ "GenSigTimeoutTime" BU_SG_REL_ FASFrontradar SG_ 253 ESP_Eingriff 500;
BA_REL_ "GenSigTimeoutTime" BU_SG_REL_ FASFrontradar SG_ 253 ESP_ASP 500;
BA_REL_ "GenSigTimeoutTime" BU_SG_REL_ FASFrontradar SG_ 2527679740 KBI_aktive_Laengsfunktion_02 2000;
BA_REL_ "GenSigTimeoutTime" BU_SG_REL_ FASFrontradar SG_ 2527679740 KBI_Anzeigestatus_ACC 2000;
BA_REL_ "GenSigTimeoutTime" BU_SG_REL_ FASFrontradar SG_ 2527679740 KBI_Konsistenz_ACC 2000;
BA_REL_ "GenSigTimeoutTime" BU_SG_REL_ FASFrontradar SG_ 2527679740 KBI_Fehler_Anzeige_ACC 2000;
BA_REL_ "GenSigTimeoutTime" BU_SG_REL_ FASFrontradar SG_ 2589283684 FoD_Transmission_Info 5000;
BA_REL_ "GenSigTimeoutTime" BU_SG_REL_ FASFrontradar SG_ 987 BCM_01_alt 1000;
BA_REL_ "GenSigTimeoutTime" BU_SG_REL_ FASFrontradar SG_ 987 Wischer_01_alt 1000;
BA_REL_ "GenSigTimeoutTime" BU_SG_REL_ FASFrontradar SG_ 987 Klima_Sensor_02_alt 1000;
BA_REL_ "GenSigTimeoutTime" BU_SG_REL_ FASFrontradar SG_ 987 Wischer_vorne_aktiv 1000;
BA_REL_ "GenSigTimeoutTime" BU_SG_REL_ FASFrontradar SG_ 987 BCM1_MH_Schalter 1000;
BA_REL_ "GenSigTimeoutTime" BU_SG_REL_ FASFrontradar SG_ 987 BCM1_Aussen_Temp_ungef 1000;
BA_REL_ "GenSigTimeoutTime" BU_SG_REL_ FASFrontradar SG_ 988 Motor_12_alt 500;
BA_REL_ "GenSigTimeoutTime" BU_SG_REL_ FASFrontradar SG_ 988 ESP_07_alt 500;
BA_REL_ "GenSigTimeoutTime" BU_SG_REL_ FASFrontradar SG_ 988 Getriebe_11_alt 500;
BA_REL_ "GenSigTimeoutTime" BU_SG_REL_ FASFrontradar SG_ 988 MO_QBit_Drehzahl_01 500;
BA_REL_ "GenSigTimeoutTime" BU_SG_REL_ FASFrontradar SG_ 988 GE_Fahrstufe 500;
BA_REL_ "GenSigTimeoutTime" BU_SG_REL_ FASFrontradar SG_ 988 ESP_Rollenmodus_Deaktivieren 500;
BA_REL_ "GenSigTimeoutTime" BU_SG_REL_ FASFrontradar SG_ 2463978722 GNSS_DR_Breite_Ortung 1000;
BA_REL_ "GenSigTimeoutTime" BU_SG_REL_ FASFrontradar SG_ 2463978722 GNSS_DR_Richtung_Breite_Ortung 1000;
BA_REL_ "GenSigTimeoutTime" BU_SG_REL_ FASFrontradar SG_ 2463978722 GNSS_DR_Laenge_Ortung 1000;
BA_REL_ "GenSigTimeoutTime" BU_SG_REL_ FASFrontradar SG_ 2463978722 GNSS_DR_Richtung_Laenge_Ortung 1000;
BA_REL_ "GenSigTimeoutTime" BU_SG_REL_ FASFrontradar SG_ 2463978723 GNSS_DR_Ortung_Ausrichtung 1000;
BA_REL_ "GenSigTimeoutTime" BU_SG_REL_ FASFrontradar SG_ 299 GRA_ACC_01_CRC 500;
BA_REL_ "GenSigTimeoutTime" BU_SG_REL_ FASFrontradar SG_ 299 GRA_ACC_01_BZ 500;
BA_REL_ "GenSigTimeoutTime" BU_SG_REL_ FASFrontradar SG_ 299 GRA_Hauptschalter 500;
BA_REL_ "GenSigTimeoutTime" BU_SG_REL_ FASFrontradar SG_ 299 GRA_Abbrechen 500;
BA_REL_ "GenSigTimeoutTime" BU_SG_REL_ FASFrontradar SG_ 299 GRA_Tip_Setzen 500;
BA_REL_ "GenSigTimeoutTime" BU_SG_REL_ FASFrontradar SG_ 299 GRA_Tip_Hoch 500;
BA_REL_ "GenSigTimeoutTime" BU_SG_REL_ FASFrontradar SG_ 299 GRA_Tip_Runter 500;
BA_REL_ "GenSigTimeoutTime" BU_SG_REL_ FASFrontradar SG_ 299 GRA_Tip_Wiederaufnahme 500;
BA_REL_ "GenSigTimeoutTime" BU_SG_REL_ FASFrontradar SG_ 299 GRA_Verstellung_Zeitluecke 500;
BA_REL_ "GenSigTimeoutTime" BU_SG_REL_ FASFrontradar SG_ 299 GRA_Codierung 500;
BA_REL_ "GenSigTimeoutTime" BU_SG_REL_ FASFrontradar SG_ 299 GRA_Fehler 500;
BA_REL_ "GenSigTimeoutTime" BU_SG_REL_ FASFrontradar SG_ 299 GRA_Tip_Stufe_2 500;
BA_REL_ "GenSigTimeoutTime" BU_SG_REL_ FASFrontradar SG_ 299 GRA_Typ_Bedienteil 500;
BA_REL_ "GenSigTimeoutTime" BU_SG_REL_ FASFrontradar SG_ 299 GRA_TravelAssist 500;
BA_REL_ "GenSigTimeoutTime" BU_SG_REL_ ICAS1_X_Gateway SG_ 771 FoD_DTC_TPA_rTPA_MFK 5000;
BA_REL_ "GenSigTimeoutTime" BU_SG_REL_ MFK SG_ 258 ESC_50_CRC 500;
BA_REL_ "GenSigTimeoutTime" BU_SG_REL_ MFK SG_ 258 ESC_50_BZ 500;
BA_REL_ "GenSigTimeoutTime" BU_SG_REL_ MFK SG_ 258 ESP_QBit_Gierrate 500;
BA_REL_ "GenSigTimeoutTime" BU_SG_REL_ MFK SG_ 258 ESP_QBit_Laengsbeschl 500;
BA_REL_ "GenSigTimeoutTime" BU_SG_REL_ MFK SG_ 258 ESP_QBit_Querb 500;
BA_REL_ "GenSigTimeoutTime" BU_SG_REL_ MFK SG_ 258 ESP_Querbeschleunigung 500;
BA_REL_ "GenSigTimeoutTime" BU_SG_REL_ MFK SG_ 258 ESP_Laengsbeschl 500;
BA_REL_ "GenSigTimeoutTime" BU_SG_REL_ MFK SG_ 258 ESP_Gierrate 500;
BA_REL_ "GenSigTimeoutTime" BU_SG_REL_ MFK SG_ 258 ESP_VZ_Gierrate 500;
BA_REL_ "GenSigTimeoutTime" BU_SG_REL_ MFK SG_ 258 ESP_QBit_Bremsdruck 500;
BA_REL_ "GenSigTimeoutTime" BU_SG_REL_ MFK SG_ 258 ESP_Bremsdruck 500;
BA_REL_ "GenSigTimeoutTime" BU_SG_REL_ MFK SG_ 258 ESP_Fahrer_bremst 500;
BA_REL_ "GenSigTimeoutTime" BU_SG_REL_ MFK SG_ 258 ESP_Prefill_ausgeloest 500;
BA_REL_ "GenSigTimeoutTime" BU_SG_REL_ MFK SG_ 258 ECD_Bremslicht 500;
BA_REL_ "GenSigTimeoutTime" BU_SG_REL_ MFK SG_ 258 ESP_QBit_v_ref 500;
BA_REL_ "GenSigTimeoutTime" BU_SG_REL_ MFK SG_ 258 ESP_v_ref_Fahrtrichtung 500;
BA_REL_ "GenSigTimeoutTime" BU_SG_REL_ MFK SG_ 258 ESP_v_ref 500;
BA_REL_ "GenSigTimeoutTime" BU_SG_REL_ MFK SG_ 258 ESC_QBit_Fahrerbremswunsch 500;
BA_REL_ "GenSigTimeoutTime" BU_SG_REL_ MFK SG_ 258 ESC_Fahrerbremswunsch 500;
BA_REL_ "GenSigTimeoutTime" BU_SG_REL_ MFK SG_ 258 EPB_Schalterposition 500;
BA_REL_ "GenSigTimeoutTime" BU_SG_REL_ MFK SG_ 252 ESP_HL_Radgeschw_02 500;
BA_REL_ "GenSigTimeoutTime" BU_SG_REL_ MFK SG_ 252 ESP_HR_Radgeschw_02 500;
BA_REL_ "GenSigTimeoutTime" BU_SG_REL_ MFK SG_ 252 ESP_VL_Radgeschw_02 500;
BA_REL_ "GenSigTimeoutTime" BU_SG_REL_ MFK SG_ 252 ESP_VR_Radgeschw_02 500;
BA_REL_ "GenSigTimeoutTime" BU_SG_REL_ MFK SG_ 278 ESP_QBit_Wegimpuls_VL 500;
BA_REL_ "GenSigTimeoutTime" BU_SG_REL_ MFK SG_ 278 ESP_QBit_Wegimpuls_VR 500;
BA_REL_ "GenSigTimeoutTime" BU_SG_REL_ MFK SG_ 278 ESP_QBit_Wegimpuls_HL 500;
BA_REL_ "GenSigTimeoutTime" BU_SG_REL_ MFK SG_ 278 ESP_QBit_Wegimpuls_HR 500;
BA_REL_ "GenSigTimeoutTime" BU_SG_REL_ MFK SG_ 278 ESP_Wegimpuls_VL 500;
BA_REL_ "GenSigTimeoutTime" BU_SG_REL_ MFK SG_ 278 ESP_Wegimpuls_VR 500;
BA_REL_ "GenSigTimeoutTime" BU_SG_REL_ MFK SG_ 278 ESP_Wegimpuls_HL 500;
BA_REL_ "GenSigTimeoutTime" BU_SG_REL_ MFK SG_ 278 ESP_Wegimpuls_HR 500;
BA_REL_ "GenSigTimeoutTime" BU_SG_REL_ MFK SG_ 278 ESP_VL_Fahrtrichtung 500;
BA_REL_ "GenSigTimeoutTime" BU_SG_REL_ MFK SG_ 278 ESP_VR_Fahrtrichtung 500;
BA_REL_ "GenSigTimeoutTime" BU_SG_REL_ MFK SG_ 278 ESP_HL_Fahrtrichtung 500;
BA_REL_ "GenSigTimeoutTime" BU_SG_REL_ MFK SG_ 278 ESP_HR_Fahrtrichtung 500;
BA_REL_ "GenSigTimeoutTime" BU_SG_REL_ MFK SG_ 1629 BR_QBit_Reifenumfang 5000;
BA_REL_ "GenSigTimeoutTime" BU_SG_REL_ MFK SG_ 1629 BR_Reifenumfang 5000;
BA_REL_ "GenSigTimeoutTime" BU_SG_REL_ MFK SG_ 253 ESP_21_CRC 500;
BA_REL_ "GenSigTimeoutTime" BU_SG_REL_ MFK SG_ 253 ESP_21_BZ 500;
BA_REL_ "GenSigTimeoutTime" BU_SG_REL_ MFK SG_ 253 ESC_v_Signal_Qualifier_High_Low 500;
BA_REL_ "GenSigTimeoutTime" BU_SG_REL_ MFK SG_ 253 ESP_v_Signal 500;
BA_REL_ "GenSigTimeoutTime" BU_SG_REL_ MFK SG_ 253 ASR_Tastung_passiv 500;
BA_REL_ "GenSigTimeoutTime" BU_SG_REL_ MFK SG_ 253 ESP_Tastung_passiv 500;
BA_REL_ "GenSigTimeoutTime" BU_SG_REL_ MFK SG_ 253 ESP_Systemstatus 500;
BA_REL_ "GenSigTimeoutTime" BU_SG_REL_ MFK SG_ 253 ESP_QBit_v_Signal 500;
BA_REL_ "GenSigTimeoutTime" BU_SG_REL_ MFK SG_ 253 ABS_Bremsung 500;
BA_REL_ "GenSigTimeoutTime" BU_SG_REL_ MFK SG_ 253 ASR_Anf 500;
BA_REL_ "GenSigTimeoutTime" BU_SG_REL_ MFK SG_ 253 MSR_Anf 500;
BA_REL_ "GenSigTimeoutTime" BU_SG_REL_ MFK SG_ 253 EDS_Eingriff 500;
BA_REL_ "GenSigTimeoutTime" BU_SG_REL_ MFK SG_ 253 ESP_Eingriff 500;
BA_REL_ "GenSigTimeoutTime" BU_SG_REL_ MFK SG_ 253 ESP_ASP 500;
BA_REL_ "GenSigTimeoutTime" BU_SG_REL_ MFK SG_ 2527679740 KBI_aktive_Laengsfunktion_02 2000;
BA_REL_ "GenSigTimeoutTime" BU_SG_REL_ MFK SG_ 2527679740 KBI_Anzeigefehler_LDW 2000;
BA_REL_ "GenSigTimeoutTime" BU_SG_REL_ MFK SG_ 2589283684 FoD_State_TPA_rTPA 5000;
BA_REL_ "GenSigTimeoutTime" BU_SG_REL_ MFK SG_ 2589283684 FoD_Transmission_Info 5000;
BA_REL_ "GenSigTimeoutTime" BU_SG_REL_ MFK SG_ 987 Wischer_01_alt 1000;
BA_REL_ "GenSigTimeoutTime" BU_SG_REL_ MFK SG_ 987 Klima_Sensor_02_alt 1000;
BA_REL_ "GenSigTimeoutTime" BU_SG_REL_ MFK SG_ 987 Wischer_vorne_aktiv 1000;
BA_REL_ "GenSigTimeoutTime" BU_SG_REL_ MFK SG_ 987 WWSs_01_alt 1000;
BA_REL_ "GenSigTimeoutTime" BU_SG_REL_ MFK SG_ 987 BCM1_Aussen_Temp_ungef 1000;
BA_REL_ "GenSigTimeoutTime" BU_SG_REL_ MFK SG_ 988 Getriebe_11_alt 500;
BA_REL_ "GenSigTimeoutTime" BU_SG_REL_ MFK SG_ 988 GE_Fahrstufe 500;
BA_REL_ "GenSigTimeoutTime" BU_SG_REL_ MFK SG_ 988 ESP_Rollenmodus_Deaktivieren 500;
BA_REL_ "GenSigTimeoutTime" BU_SG_REL_ MFK SG_ 299 GRA_Hauptschalter 500;
BA_REL_ "GenSigTimeoutTime" BU_SG_REL_ MFK SG_ 299 GRA_Abbrechen 500;
BA_REL_ "GenSigTimeoutTime" BU_SG_REL_ MFK SG_ 299 GRA_Tip_Setzen 500;
BA_REL_ "GenSigTimeoutTime" BU_SG_REL_ MFK SG_ 299 GRA_Tip_Hoch 500;
BA_REL_ "GenSigTimeoutTime" BU_SG_REL_ MFK SG_ 299 GRA_Tip_Runter 500;
BA_REL_ "GenSigTimeoutTime" BU_SG_REL_ MFK SG_ 299 GRA_Tip_Wiederaufnahme 500;
BA_REL_ "GenSigTimeoutTime" BU_SG_REL_ MFK SG_ 299 GRA_Verstellung_Zeitluecke 500;
BA_REL_ "GenSigTimeoutTime" BU_SG_REL_ MFK120 SG_ 258 ESC_50_CRC 500;
BA_REL_ "GenSigTimeoutTime" BU_SG_REL_ MFK120 SG_ 258 ESC_50_BZ 500;
BA_REL_ "GenSigTimeoutTime" BU_SG_REL_ MFK120 SG_ 258 ESP_QBit_Gierrate 500;
BA_REL_ "GenSigTimeoutTime" BU_SG_REL_ MFK120 SG_ 258 ESP_QBit_Laengsbeschl 500;
BA_REL_ "GenSigTimeoutTime" BU_SG_REL_ MFK120 SG_ 258 ESP_QBit_Querb 500;
BA_REL_ "GenSigTimeoutTime" BU_SG_REL_ MFK120 SG_ 258 ESP_Querbeschleunigung 500;
BA_REL_ "GenSigTimeoutTime" BU_SG_REL_ MFK120 SG_ 258 ESP_Laengsbeschl 500;
BA_REL_ "GenSigTimeoutTime" BU_SG_REL_ MFK120 SG_ 258 ESP_Gierrate 500;
BA_REL_ "GenSigTimeoutTime" BU_SG_REL_ MFK120 SG_ 258 ESP_VZ_Gierrate 500;
BA_REL_ "GenSigTimeoutTime" BU_SG_REL_ MFK120 SG_ 258 ESP_QBit_Bremsdruck 500;
BA_REL_ "GenSigTimeoutTime" BU_SG_REL_ MFK120 SG_ 258 ESP_Bremsdruck 500;
BA_REL_ "GenSigTimeoutTime" BU_SG_REL_ MFK120 SG_ 258 ESP_Fahrer_bremst 500;
BA_REL_ "GenSigTimeoutTime" BU_SG_REL_ MFK120 SG_ 258 ESP_Prefill_ausgeloest 500;
BA_REL_ "GenSigTimeoutTime" BU_SG_REL_ MFK120 SG_ 258 ECD_Bremslicht 500;
BA_REL_ "GenSigTimeoutTime" BU_SG_REL_ MFK120 SG_ 258 ESC_QBit_Fahrerbremswunsch 500;
BA_REL_ "GenSigTimeoutTime" BU_SG_REL_ MFK120 SG_ 258 ESC_Fahrerbremswunsch 500;
BA_REL_ "GenSigTimeoutTime" BU_SG_REL_ MFK120 SG_ 258 EPB_Fehlerstatus_02 500;
BA_REL_ "GenSigTimeoutTime" BU_SG_REL_ MFK120 SG_ 258 EPB_Schalterposition 500;
BA_REL_ "GenSigTimeoutTime" BU_SG_REL_ MFK120 SG_ 258 EPB_QBit_Schalterpos 500;
BA_REL_ "GenSigTimeoutTime" BU_SG_REL_ MFK120 SG_ 252 ESP_HL_Radgeschw_02 500;
BA_REL_ "GenSigTimeoutTime" BU_SG_REL_ MFK120 SG_ 252 ESP_HR_Radgeschw_02 500;
BA_REL_ "GenSigTimeoutTime" BU_SG_REL_ MFK120 SG_ 252 ESP_VL_Radgeschw_02 500;
BA_REL_ "GenSigTimeoutTime" BU_SG_REL_ MFK120 SG_ 252 ESP_VR_Radgeschw_02 500;
BA_REL_ "GenSigTimeoutTime" BU_SG_REL_ MFK120 SG_ 252 ESC_Status_Eingriff 500;
BA_REL_ "GenSigTimeoutTime" BU_SG_REL_ MFK120 SG_ 278 ESP_QBit_Wegimpuls_VL 500;
BA_REL_ "GenSigTimeoutTime" BU_SG_REL_ MFK120 SG_ 278 ESP_QBit_Wegimpuls_VR 500;
BA_REL_ "GenSigTimeoutTime" BU_SG_REL_ MFK120 SG_ 278 ESP_QBit_Wegimpuls_HL 500;
BA_REL_ "GenSigTimeoutTime" BU_SG_REL_ MFK120 SG_ 278 ESP_QBit_Wegimpuls_HR 500;
BA_REL_ "GenSigTimeoutTime" BU_SG_REL_ MFK120 SG_ 278 ESP_Wegimpuls_VL 500;
BA_REL_ "GenSigTimeoutTime" BU_SG_REL_ MFK120 SG_ 278 ESP_Wegimpuls_VR 500;
BA_REL_ "GenSigTimeoutTime" BU_SG_REL_ MFK120 SG_ 278 ESP_Wegimpuls_HL 500;
BA_REL_ "GenSigTimeoutTime" BU_SG_REL_ MFK120 SG_ 278 ESP_Wegimpuls_HR 500;
BA_REL_ "GenSigTimeoutTime" BU_SG_REL_ MFK120 SG_ 278 ESP_VL_Fahrtrichtung 500;
BA_REL_ "GenSigTimeoutTime" BU_SG_REL_ MFK120 SG_ 278 ESP_VR_Fahrtrichtung 500;
BA_REL_ "GenSigTimeoutTime" BU_SG_REL_ MFK120 SG_ 278 ESP_HL_Fahrtrichtung 500;
BA_REL_ "GenSigTimeoutTime" BU_SG_REL_ MFK120 SG_ 278 ESP_HR_Fahrtrichtung 500;
BA_REL_ "GenSigTimeoutTime" BU_SG_REL_ MFK120 SG_ 1629 ESP_Zaehnezahl 5000;
BA_REL_ "GenSigTimeoutTime" BU_SG_REL_ MFK120 SG_ 1629 BR_QBit_Reifenumfang 5000;
BA_REL_ "GenSigTimeoutTime" BU_SG_REL_ MFK120 SG_ 1629 BR_Reifenumfang 5000;
BA_REL_ "GenSigTimeoutTime" BU_SG_REL_ MFK120 SG_ 253 ESP_21_CRC 500;
BA_REL_ "GenSigTimeoutTime" BU_SG_REL_ MFK120 SG_ 253 ESP_21_BZ 500;
BA_REL_ "GenSigTimeoutTime" BU_SG_REL_ MFK120 SG_ 253 ESC_v_Signal_Qualifier_High_Low 500;
BA_REL_ "GenSigTimeoutTime" BU_SG_REL_ MFK120 SG_ 253 ESP_v_Signal 500;
BA_REL_ "GenSigTimeoutTime" BU_SG_REL_ MFK120 SG_ 253 ASR_Tastung_passiv 500;
BA_REL_ "GenSigTimeoutTime" BU_SG_REL_ MFK120 SG_ 253 ESP_Tastung_passiv 500;
BA_REL_ "GenSigTimeoutTime" BU_SG_REL_ MFK120 SG_ 253 ESP_Systemstatus 500;
BA_REL_ "GenSigTimeoutTime" BU_SG_REL_ MFK120 SG_ 253 ESP_QBit_v_Signal 500;
BA_REL_ "GenSigTimeoutTime" BU_SG_REL_ MFK120 SG_ 253 ABS_Bremsung 500;
BA_REL_ "GenSigTimeoutTime" BU_SG_REL_ MFK120 SG_ 253 ASR_Anf 500;
BA_REL_ "GenSigTimeoutTime" BU_SG_REL_ MFK120 SG_ 253 MSR_Anf 500;
BA_REL_ "GenSigTimeoutTime" BU_SG_REL_ MFK120 SG_ 253 ESP_Eingriff 500;
BA_REL_ "GenSigTimeoutTime" BU_SG_REL_ MFK120 SG_ 253 ESP_ASP 500;
BA_REL_ "GenSigTimeoutTime" BU_SG_REL_ MFK120 SG_ 2527679740 KBI_aktive_Laengsfunktion_02 2000;
BA_REL_ "GenSigTimeoutTime" BU_SG_REL_ MFK120 SG_ 2589283684 FoD_State_TPA_rTPA 5000;
BA_REL_ "GenSigTimeoutTime" BU_SG_REL_ MFK120 SG_ 987 Wischer_vorne_aktiv 1000;
BA_REL_ "GenSigTimeoutTime" BU_SG_REL_ MFK120 SG_ 987 BCM1_Aussen_Temp_ungef 1000;
BA_REL_ "GenSigTimeoutTime" BU_SG_REL_ MFK120 SG_ 173 GE_Fahrstufe 500;
BA_REL_ "GenSigTimeoutTime" BU_SG_REL_ MFK120 SG_ 299 GRA_Hauptschalter 500;
BA_REL_ "GenSigTimeoutTime" BU_SG_REL_ MFK120 SG_ 299 GRA_Abbrechen 500;
BA_REL_ "GenSigTimeoutTime" BU_SG_REL_ MFK120 SG_ 299 GRA_Tip_Setzen 500;
BA_REL_ "GenSigTimeoutTime" BU_SG_REL_ MFK120 SG_ 299 GRA_Tip_Hoch 500;
BA_REL_ "GenSigTimeoutTime" BU_SG_REL_ MFK120 SG_ 299 GRA_Tip_Runter 500;
BA_REL_ "GenSigTimeoutTime" BU_SG_REL_ MFK120 SG_ 299 GRA_Tip_Wiederaufnahme 500;
BA_REL_ "GenSigTimeoutTime" BU_SG_REL_ MFK120 SG_ 299 GRA_Verstellung_Zeitluecke 500;
BA_REL_ "GenSigTimeoutTime" BU_SG_REL_ MIK SG_ 253 ESC_v_Signal_Qualifier_High_Low 500;
BA_REL_ "GenSigTimeoutTime" BU_SG_REL_ MIK SG_ 253 ESP_v_Signal 500;
BA_REL_ "GenSigTimeoutTime" BU_SG_REL_ MIK SG_ 253 ESP_QBit_v_Signal 500;
BA_REL_ "GenSigTimeoutTime" BU_SG_REL_ MRR2023 SG_ 258 ESC_50_CRC 500;
BA_REL_ "GenSigTimeoutTime" BU_SG_REL_ MRR2023 SG_ 258 ESC_50_BZ 500;
BA_REL_ "GenSigTimeoutTime" BU_SG_REL_ MRR2023 SG_ 258 ESP_QBit_Gierrate 500;
BA_REL_ "GenSigTimeoutTime" BU_SG_REL_ MRR2023 SG_ 258 ESP_QBit_Laengsbeschl 500;
BA_REL_ "GenSigTimeoutTime" BU_SG_REL_ MRR2023 SG_ 258 ESP_QBit_Querb 500;
BA_REL_ "GenSigTimeoutTime" BU_SG_REL_ MRR2023 SG_ 258 ESP_Querbeschleunigung 500;
BA_REL_ "GenSigTimeoutTime" BU_SG_REL_ MRR2023 SG_ 258 ESP_Laengsbeschl 500;
BA_REL_ "GenSigTimeoutTime" BU_SG_REL_ MRR2023 SG_ 258 ESP_Gierrate 500;
BA_REL_ "GenSigTimeoutTime" BU_SG_REL_ MRR2023 SG_ 258 ESP_VZ_Gierrate 500;
BA_REL_ "GenSigTimeoutTime" BU_SG_REL_ MRR2023 SG_ 258 ESP_QBit_Bremsdruck 500;
BA_REL_ "GenSigTimeoutTime" BU_SG_REL_ MRR2023 SG_ 258 ESP_Bremsdruck 500;
BA_REL_ "GenSigTimeoutTime" BU_SG_REL_ MRR2023 SG_ 258 ESP_Fahrer_bremst 500;
BA_REL_ "GenSigTimeoutTime" BU_SG_REL_ MRR2023 SG_ 258 ESP_Autohold_Standby 500;
BA_REL_ "GenSigTimeoutTime" BU_SG_REL_ MRR2023 SG_ 258 ESP_Systemstatus_03 500;
BA_REL_ "GenSigTimeoutTime" BU_SG_REL_ MRR2023 SG_ 258 ESC_QBit_Fahrerbremswunsch 500;
BA_REL_ "GenSigTimeoutTime" BU_SG_REL_ MRR2023 SG_ 258 ESC_Fahrerbremswunsch 500;
BA_REL_ "GenSigTimeoutTime" BU_SG_REL_ MRR2023 SG_ 258 EPB_Schalterposition 500;
BA_REL_ "GenSigTimeoutTime" BU_SG_REL_ MRR2023 SG_ 258 EPB_QBit_Schalterpos 500;
BA_REL_ "GenSigTimeoutTime" BU_SG_REL_ MRR2023 SG_ 258 EPB_Status_02 500;
BA_REL_ "GenSigTimeoutTime" BU_SG_REL_ MRR2023 SG_ 258 ESP_Status_Bremsentemp_02 500;
BA_REL_ "GenSigTimeoutTime" BU_SG_REL_ MRR2023 SG_ 252 ESC_51_CRC 500;
BA_REL_ "GenSigTimeoutTime" BU_SG_REL_ MRR2023 SG_ 252 ESC_51_BZ 500;
BA_REL_ "GenSigTimeoutTime" BU_SG_REL_ MRR2023 SG_ 252 ESP_HL_Radgeschw_02 500;
BA_REL_ "GenSigTimeoutTime" BU_SG_REL_ MRR2023 SG_ 252 ESP_HR_Radgeschw_02 500;
BA_REL_ "GenSigTimeoutTime" BU_SG_REL_ MRR2023 SG_ 252 ESP_VL_Radgeschw_02 500;
BA_REL_ "GenSigTimeoutTime" BU_SG_REL_ MRR2023 SG_ 252 ESP_VR_Radgeschw_02 500;
BA_REL_ "GenSigTimeoutTime" BU_SG_REL_ MRR2023 SG_ 252 ESP_FZR_uebersteuern 500;
BA_REL_ "GenSigTimeoutTime" BU_SG_REL_ MRR2023 SG_ 252 ESP_FZR_untersteuern 500;
BA_REL_ "GenSigTimeoutTime" BU_SG_REL_ MRR2023 SG_ 252 ESC_GMV_aktiv 500;
BA_REL_ "GenSigTimeoutTime" BU_SG_REL_ MRR2023 SG_ 252 ESC_GMV_nicht_verfuegbar 500;
BA_REL_ "GenSigTimeoutTime" BU_SG_REL_ MRR2023 SG_ 278 ESP_10_CRC 500;
BA_REL_ "GenSigTimeoutTime" BU_SG_REL_ MRR2023 SG_ 278 ESP_10_BZ 500;
BA_REL_ "GenSigTimeoutTime" BU_SG_REL_ MRR2023 SG_ 278 ESP_QBit_Wegimpuls_VL 500;
BA_REL_ "GenSigTimeoutTime" BU_SG_REL_ MRR2023 SG_ 278 ESP_QBit_Wegimpuls_VR 500;
BA_REL_ "GenSigTimeoutTime" BU_SG_REL_ MRR2023 SG_ 278 ESP_QBit_Wegimpuls_HL 500;
BA_REL_ "GenSigTimeoutTime" BU_SG_REL_ MRR2023 SG_ 278 ESP_QBit_Wegimpuls_HR 500;
BA_REL_ "GenSigTimeoutTime" BU_SG_REL_ MRR2023 SG_ 278 ESP_Wegimpuls_VL 500;
BA_REL_ "GenSigTimeoutTime" BU_SG_REL_ MRR2023 SG_ 278 ESP_Wegimpuls_VR 500;
BA_REL_ "GenSigTimeoutTime" BU_SG_REL_ MRR2023 SG_ 278 ESP_Wegimpuls_HL 500;
BA_REL_ "GenSigTimeoutTime" BU_SG_REL_ MRR2023 SG_ 278 ESP_Wegimpuls_HR 500;
BA_REL_ "GenSigTimeoutTime" BU_SG_REL_ MRR2023 SG_ 278 ESP_VL_Fahrtrichtung 500;
BA_REL_ "GenSigTimeoutTime" BU_SG_REL_ MRR2023 SG_ 278 ESP_VR_Fahrtrichtung 500;
BA_REL_ "GenSigTimeoutTime" BU_SG_REL_ MRR2023 SG_ 278 ESP_HL_Fahrtrichtung 500;
BA_REL_ "GenSigTimeoutTime" BU_SG_REL_ MRR2023 SG_ 278 ESP_HR_Fahrtrichtung 500;
BA_REL_ "GenSigTimeoutTime" BU_SG_REL_ MRR2023 SG_ 1629 ESP_20_CRC 5000;
BA_REL_ "GenSigTimeoutTime" BU_SG_REL_ MRR2023 SG_ 1629 ESP_20_BZ 5000;
BA_REL_ "GenSigTimeoutTime" BU_SG_REL_ MRR2023 SG_ 1629 ESP_Zaehnezahl 5000;
BA_REL_ "GenSigTimeoutTime" BU_SG_REL_ MRR2023 SG_ 253 ESP_21_CRC 500;
BA_REL_ "GenSigTimeoutTime" BU_SG_REL_ MRR2023 SG_ 253 ESP_21_BZ 500;
BA_REL_ "GenSigTimeoutTime" BU_SG_REL_ MRR2023 SG_ 253 ESP_Diagnose 500;
BA_REL_ "GenSigTimeoutTime" BU_SG_REL_ MRR2023 SG_ 253 ESC_v_Signal_Qualifier_High_Low 500;
BA_REL_ "GenSigTimeoutTime" BU_SG_REL_ MRR2023 SG_ 253 ESP_Vorsteuerung 500;
BA_REL_ "GenSigTimeoutTime" BU_SG_REL_ MRR2023 SG_ 253 ESP_v_Signal 500;
BA_REL_ "GenSigTimeoutTime" BU_SG_REL_ MRR2023 SG_ 253 ASR_Tastung_passiv 500;
BA_REL_ "GenSigTimeoutTime" BU_SG_REL_ MRR2023 SG_ 253 ESP_Tastung_passiv 500;
BA_REL_ "GenSigTimeoutTime" BU_SG_REL_ MRR2023 SG_ 253 ESP_Systemstatus 500;
BA_REL_ "GenSigTimeoutTime" BU_SG_REL_ MRR2023 SG_ 253 ESP_QBit_v_Signal 500;
BA_REL_ "GenSigTimeoutTime" BU_SG_REL_ MRR2023 SG_ 253 ABS_Bremsung 500;
BA_REL_ "GenSigTimeoutTime" BU_SG_REL_ MRR2023 SG_ 253 ASR_Anf 500;
BA_REL_ "GenSigTimeoutTime" BU_SG_REL_ MRR2023 SG_ 253 MSR_Anf 500;
BA_REL_ "GenSigTimeoutTime" BU_SG_REL_ MRR2023 SG_ 253 EBV_Eingriff 500;
BA_REL_ "GenSigTimeoutTime" BU_SG_REL_ MRR2023 SG_ 253 EDS_Eingriff 500;
BA_REL_ "GenSigTimeoutTime" BU_SG_REL_ MRR2023 SG_ 253 ESP_Eingriff 500;
BA_REL_ "GenSigTimeoutTime" BU_SG_REL_ MRR2023 SG_ 253 ESP_ASP 500;
BA_REL_ "GenSigTimeoutTime" BU_SG_REL_ MRR2023 SG_ 2527679740 KBI_aktive_Laengsfunktion_02 2000;
BA_REL_ "GenSigTimeoutTime" BU_SG_REL_ MRR2023 SG_ 2527679740 KBI_Anzeigestatus_ACC 2000;
BA_REL_ "GenSigTimeoutTime" BU_SG_REL_ MRR2023 SG_ 2527679740 KBI_Konsistenz_ACC 2000;
BA_REL_ "GenSigTimeoutTime" BU_SG_REL_ MRR2023 SG_ 2527679740 KBI_Fehler_Anzeige_ACC 2000;
BA_REL_ "GenSigTimeoutTime" BU_SG_REL_ MRR2023 SG_ 2589283684 FoD_Transmission_Info 5000;
BA_REL_ "GenSigTimeoutTime" BU_SG_REL_ MRR2023 SG_ 987 BCM_01_alt 1000;
BA_REL_ "GenSigTimeoutTime" BU_SG_REL_ MRR2023 SG_ 987 Wischer_01_alt 1000;
BA_REL_ "GenSigTimeoutTime" BU_SG_REL_ MRR2023 SG_ 987 Klima_Sensor_02_alt 1000;
BA_REL_ "GenSigTimeoutTime" BU_SG_REL_ MRR2023 SG_ 987 Wischer_vorne_aktiv 1000;
BA_REL_ "GenSigTimeoutTime" BU_SG_REL_ MRR2023 SG_ 987 BCM1_MH_Schalter 1000;
BA_REL_ "GenSigTimeoutTime" BU_SG_REL_ MRR2023 SG_ 987 BCM1_Aussen_Temp_ungef 1000;
BA_REL_ "GenSigTimeoutTime" BU_SG_REL_ MRR2023 SG_ 988 Motor_12_alt 500;
BA_REL_ "GenSigTimeoutTime" BU_SG_REL_ MRR2023 SG_ 988 ESP_07_alt 500;
BA_REL_ "GenSigTimeoutTime" BU_SG_REL_ MRR2023 SG_ 988 MO_QBit_Drehzahl_01 500;
BA_REL_ "GenSigTimeoutTime" BU_SG_REL_ MRR2023 SG_ 988 ESP_Rollenmodus_Deaktivieren 500;
BA_REL_ "GenSigTimeoutTime" BU_SG_REL_ MRR2023 SG_ 173 GE_Fahrstufe 500;
BA_REL_ "GenSigTimeoutTime" BU_SG_REL_ MRR2023 SG_ 2463978722 GNSS_DR_Breite_Ortung 1000;
BA_REL_ "GenSigTimeoutTime" BU_SG_REL_ MRR2023 SG_ 2463978722 GNSS_DR_Richtung_Breite_Ortung 1000;
BA_REL_ "GenSigTimeoutTime" BU_SG_REL_ MRR2023 SG_ 2463978722 GNSS_DR_Laenge_Ortung 1000;
BA_REL_ "GenSigTimeoutTime" BU_SG_REL_ MRR2023 SG_ 2463978722 GNSS_DR_Richtung_Laenge_Ortung 1000;
BA_REL_ "GenSigTimeoutTime" BU_SG_REL_ MRR2023 SG_ 2463978723 GNSS_DR_Ortung_Ausrichtung 1000;
BA_REL_ "GenSigTimeoutTime" BU_SG_REL_ MRR2023 SG_ 299 GRA_ACC_01_CRC 500;
BA_REL_ "GenSigTimeoutTime" BU_SG_REL_ MRR2023 SG_ 299 GRA_ACC_01_BZ 500;
BA_REL_ "GenSigTimeoutTime" BU_SG_REL_ MRR2023 SG_ 299 GRA_Hauptschalter 500;
BA_REL_ "GenSigTimeoutTime" BU_SG_REL_ MRR2023 SG_ 299 GRA_Abbrechen 500;
BA_REL_ "GenSigTimeoutTime" BU_SG_REL_ MRR2023 SG_ 299 GRA_Tip_Setzen 500;
BA_REL_ "GenSigTimeoutTime" BU_SG_REL_ MRR2023 SG_ 299 GRA_Tip_Hoch 500;
BA_REL_ "GenSigTimeoutTime" BU_SG_REL_ MRR2023 SG_ 299 GRA_Tip_Runter 500;
BA_REL_ "GenSigTimeoutTime" BU_SG_REL_ MRR2023 SG_ 299 GRA_Tip_Wiederaufnahme 500;
BA_REL_ "GenSigTimeoutTime" BU_SG_REL_ MRR2023 SG_ 299 GRA_Verstellung_Zeitluecke 500;
BA_REL_ "GenSigTimeoutTime" BU_SG_REL_ MRR2023 SG_ 299 GRA_Codierung 500;
BA_REL_ "GenSigTimeoutTime" BU_SG_REL_ MRR2023 SG_ 299 GRA_Fehler 500;
BA_REL_ "GenSigTimeoutTime" BU_SG_REL_ MRR2023 SG_ 299 GRA_Tip_Stufe_2 500;
BA_REL_ "GenSigTimeoutTime" BU_SG_REL_ MRR2023 SG_ 299 GRA_Typ_Bedienteil 500;
BA_REL_ "GenSigTimeoutTime" BU_SG_REL_ MRR2023 SG_ 299 GRA_TravelAssist 500;
VAL_ 258 ESP_QBit_Gierrate 0 "gueltiger_Wert" 1 "Ersatz_Init_oder_Fehlerwert" ;
VAL_ 258 ESP_QBit_Laengsbeschl 0 "gueltiger_Wert" 1 "Ersatz_Init_oder_Fehlerwert" ;
VAL_ 258 ESP_QBit_Querb 0 "gueltiger_Wert" 1 "Ersatz_Init_oder_Fehlerwert" ;
VAL_ 258 ESP_Querbeschleunigung 255 "Fehler" ;
VAL_ 258 ESP_Laengsbeschl 1022 "Signal_nicht_vorhanden" 1023 "Fehler" ;
VAL_ 258 ESC_Motorstartverzoegerung 0 "Startfreigabe" 1 "Anforderung_Startverzoegerung" ;
VAL_ 258 ESC_SeitenwindAssistent_Eingriff 0 "Kein_SWA_Eingriff_und_Init" 1 "SWA_Eingriff_aktiv" ;
VAL_ 258 ESP_Anschleppstart_Freigabe 0 "kein_Schleppstart_oder_NotSchleppstart_erlaubt" 1 "NotSchleppstart_erlaubt" 2 "Schleppstart_und_NotSchleppStart_erlaubt" ;
VAL_ 258 ESC_Unterdruckmangel_erkannt 0 "kein_Unterdruckmangel_erkannt" 1 "Unterdruckmangel_erkannt" ;
VAL_ 258 ESP_Gierrate 16383 "Fehler" ;
VAL_ 258 ESP_VZ_Gierrate 0 "positiv" 1 "negativ" ;
VAL_ 258 ESP_Notbremsanzeige 0 "keine_Notbremsung_erkannt" 1 "Notbremsung_erkannt" ;
VAL_ 258 ESP_SpannungsAnf 0 "keine_Anforderung" 1 "Anforderung_Spannungswert_1" ;
VAL_ 258 ESP_PLA_Abbruch 0 "Init" 1 "Geschwindigkeitsueberschreitung" 2 "Falscher_PLA_Status" 3 "Deaktivierung_durch_Abbruch_Lenkung" 4 "PLA_Bremsanforderung_nach_Stillstand" 5 "Abbruch_durch_Kl15_aus" 6 "Abbruch_durch_FT_offen" ;
VAL_ 258 ESP_Status_ESP_PLA 0 "ESP_PLA_deaktiv" 1 "ESP_PLA_Init" 2 "ESP_PLA_Fehler" 4 "ESP_PLA_aktivierbar" 6 "ESP_PLA_Bremse_aktiv" 8 "ESP_PLA_funktionsbereit" 9 "ESP_PLA_Neustart" 10 "ESP_PLA_Abbruch" ;
VAL_ 258 ESP_QBit_Bremsdruck 0 "gueltiger_Wert" 1 "Ersatz_Init_oder_Fehlerwert" ;
VAL_ 258 ESP_QBit_Fahrer_bremst 0 "gueltiger_Wert" 1 "Ersatz_Init_oder_Fehlerwert" ;
VAL_ 258 ESP_Schwelle_Unterdruck 0 "kein_Signal" 1 "Unterdruck_kleiner_gleich_450_mbar" 2 "Unterdruck_groesser_450_mbar" 3 "Fehler_Unterdrucksensor" ;
VAL_ 258 ESP_Bremsdruck 1023 "Fehler" ;
VAL_ 258 ESP_Fahrer_bremst 0 "Bremsdruckschwelle_nicht_ueberschritten" 1 "Bremsdruckschwelle_ueberschritten" ;
VAL_ 258 ESP_Verz_TSK_aktiv 0 "TSK_Verzoegerung_inaktiv" 1 "TSK_Verzoegerung_aktiv" ;
VAL_ 258 ESP_Lenkeingriff_ADS 0 "kein_Lenkeingriff" 1 "stabilisierender_Lenkeingriff" ;
VAL_ 258 ESP_Konsistenz_TSK 0 "Botschaft_fuer_Verzoegerungsanforderung_konsistent" 1 "Botschaft_fuer_Verzoegerungsanforderung_nicht_konsistent" ;
VAL_ 258 ESP_Bremsruck_AWV2 0 "kein_Bremsruck_ausgefuehrt" 1 "Bremsruck_ausgefuehrt" ;
VAL_ 258 ESP_Konsistenz_AWV2 0 "Botschaft_fuer_AWV2_konsistent" 1 "Botschaft_fuer_AWV2_nicht_konsistent" ;
VAL_ 258 ECD_Fehler 0 "ECD_iO" 1 "ECD_Fehler" ;
VAL_ 258 ECD_nicht_verfuegbar 0 "ECD_Funktion_verfuegbar" 1 "ECD_Funktion_nicht_verfuegbar" ;
VAL_ 258 ESP_Status_Bremsentemp 0 "Bremse_nicht_ueberhitzt" 1 "Bremse_ueberhitzt" ;
VAL_ 258 ESP_Autohold_Standby 0 "Autohold_nicht_im_Standby" 1 "Autohold_im_Standby" ;
VAL_ 258 ESP_HDC_Standby 0 "HDC_Funktion_nicht_im_Standby" 1 "HDC_Funktion_im_Standby" ;
VAL_ 258 ESP_HBA_aktiv 0 "HBA_nicht_aktiv" 1 "HBA_aktiv" ;
VAL_ 258 ESP_Prefill_ausgeloest 0 "nicht_ausgeloest" 1 "Prefill_ausgeloest" ;
VAL_ 258 ESP_Rueckwaertsfahrt_erkannt 0 "keine_Rueckwaetsfahrt" 1 "Rueckwaertsfahrt_sicher_erkannt" ;
VAL_ 258 ESP_Status_Anfahrhilfe 0 "Aus" 1 "Ein" ;
VAL_ 258 ESP_HDC_aktiv 0 "inaktiv" 1 "aktiv" ;
VAL_ 258 ESP_StartStopp_Info 0 "Motorlauf_nicht_notwendig_(Stoppfreigabe)" 1 "Motoranlauf_nicht_zwingend_notwendig_(Stoppverbot,keine_Startanforderung)" 2 "Motoranlauf_zwingend_notwendig_(Startanforderung)" 3 "Systemfehler" ;
VAL_ 258 ESP_Eingr_HL 0 "kein_Eingriff" 1 "ESP_Eingriff_HL" ;
VAL_ 258 ESP_Eingr_HR 0 "kein_Eingriff" 1 "ESP_Eingriff_HR" ;
VAL_ 258 ESP_Eingr_VL 0 "kein_Eingriff" 1 "ESP_Eingriff_VL" ;
VAL_ 258 ESP_Eingr_VR 0 "kein_Eingriff" 1 "ESP_Eingriff_VR" ;
VAL_ 258 ESP_BKV_Unterdruck 0 "nicht_verbaut_oder_nicht_kodiert" 254 "Init" 255 "Fehler" ;
VAL_ 258 ESP_Autohold_aktiv 0 "Autohold_inaktiv" 1 "Autohold_aktiv" ;
VAL_ 258 ESP_FStatus_Anfahrhilfe 0 "kein_Fehler" 1 "Fehler" ;
VAL_ 258 ESP_Verz_EPB_aktiv 0 "nicht_aktiviert" 1 "aktiviert" ;
VAL_ 258 ECD_Bremslicht 0 "Aus" 1 "Ein" ;
VAL_ 258 ESP_Verzoeg_EPB_verf 0 "nicht_verfuegbar" 1 "System_verfuegbar" ;
VAL_ 258 ESP_Status_Bremsdruck 0 "Bremse_drucklos" 1 "mit_Bremsdruck" ;
VAL_ 258 ESP_Anforderung_EPB 0 "keine_Anforderung" 1 "Anforderung_Oeffnen" 2 "Anforderung_Schliessen" 3 "reserviert" ;
VAL_ 258 ESC_Fahrerradbremswunschmoment 4094 "Init" 4095 "Fehler" ;
VAL_ 258 ESP_ANB_CM_Rueckk_Umsetz 0 "keine_Ausfuehrung" 1 "Ausfuehrung" ;
VAL_ 258 ESP_Konsistenz_ACC_Botschaft 0 "Botschaft_fuer_ACC_konsistent" 1 "Botschaft_fuer_ACC_nicht_konsistent" ;
VAL_ 258 ESP_Stillstandsphase_erschoepft 0 "sicheres_Halten_moeglich" 1 "kein_sicheres_Halten_moeglich" ;
VAL_ 258 ESP_ZT_Rueckk_Umsetz 0 "keine_Ausfuehrung" 1 "Ausfuehrung" ;
VAL_ 258 ESP_Tuerkontakt_Fahrertuer 0 "Schalter_geschlossen" 1 "Schalter_offen" ;
VAL_ 258 ESP_Abrutschen_Stillstand 0 "kein_Abrutschen_erkannt" 1 "Abrutschen_erkannt" ;
VAL_ 258 ESP_Fahrer_tritt_ZBR_Schw 0 "Fahrer_uebertritt_ZBR_Schwelle_nicht" 1 "Fahrer_uebertritt_ZBR_Schwelle" ;
VAL_ 258 ESP_Systemstatus_03 0 "ESC_passiv_getastet" 1 "ESC_Schwellen_geaendert" 2 "ESC_aktiviert" 3 "Fehler" ;
VAL_ 258 ASR_Systemstatus 0 "ASR_passiv_getastet" 1 "ASR_Schwellen_geaendert" 2 "ASR_aktiviert" 3 "ASR_Stoerung" ;
VAL_ 258 ESP_QBit_v_ref 0 "gueltiger_Wert" 1 "Ersatz_Init_oder_Fehlerwert" ;
VAL_ 258 ESP_v_ref_Fahrtrichtung 0 "Fahrtrichtung_nicht_definiert" 1 "Vorwaerts" 2 "Rueckwaerts" 3 "Stillstand" ;
VAL_ 258 ESC_Bremsdruckgradient 251 "groesser_2500_bar_per_sec" 254 "Init" 255 "Fehler" ;
VAL_ 258 ESP_v_ref 4093 "Unterspannung" 4094 "Init" 4095 "Fehler" ;
VAL_ 258 ESP_HBA_Empfindlichkeit 0 "Init" 1 "unempfindlich" 2 "normal" 3 "empfindlich" 4 "sehr_empfindlich" 5 "reserviert" 6 "reserviert" 7 "Fehler" ;
VAL_ 258 ESC_Hydr_Fkt_aktiv 0 "keine_Aktivitaet" 1 "ESC_Druckaufbau_HBx_HFC_aktiv" 2 "Warnrucklevel_Summand_1" 3 "Warnrucklevel_Summand_3" ;
VAL_ 258 ESC_QBit_Fahrerbremswunsch 0 "gueltiger_Wert" 1 "Ersatz_Init_oder_Fehlerwert" ;
VAL_ 258 ESC_Fahrerbremswunsch 1023 "Fehler" ;
VAL_ 258 ESCGeneratorSollMoment 4094 "Init" 4095 "Fehler" ;
VAL_ 258 ESC_Raddruck_max 254 "Init" 255 "Fehler" ;
VAL_ 258 EPB_QBit_Pedalweg_Kuppl 0 "gültiger Wert" 1 "Ersatz-, Init- oder Fehlerwert" ;
VAL_ 258 EPB_Freig_Verzoeg_Anf 0 "nicht freigegeben" 1 "freigegeben" ;
VAL_ 258 EPB_Pedalweg_Kuppl 0 "Init" 255 "Fehler" ;
VAL_ 258 EPB_DAA_Randbed_erf 0 "Randbed_nicht_erfuellt" 1 "Randbed_erfuellt" ;
VAL_ 258 EPB_Fehlerstatus_02 0 "kein_Fehler" 1 "Fehler_ausserhalb_apply_release" 2 "Fehler_einseitig_apply_release" 3 "Fehler_beidseitig_apply_release" ;
VAL_ 258 EPB_Schalterposition 0 "keine Fahreranforderung" 1 "Fahreranforderung Öffnen" 2 "Fahreranforderung Schließen" 3 "Fehler" ;
VAL_ 258 EPB_QBit_Schalterpos 0 "gültiger Wert (volle Funktion)" 1 " Ersatz-, Init- oder Fehlerwert (Schalter ausser Funktion)" ;
VAL_ 258 EPB_Spannkraft 30 "Init" 31 "Fehler" ;
VAL_ 258 EPB_Status_02 0 "offen" 1 "geschlossen_Parken" 2 "teilgespannt_Halten" 3 "im_Lauf_oeffnen" 4 "im_Lauf_schliessen" 5 "tbd" 6 "Init" 7 "unbekannt" ;
VAL_ 258 EPB_Status 0 "offen" 1 "Bremse_geschl_(Spannkraft_voll/reduziert)" 2 "Aktuator_im_Lauf" 3 "Fehler_oder_unbekannt" ;
VAL_ 258 ESP_Status_Bremsentemp_02 0 "nicht_erhoeht" 1 "Schwelle_1" 2 "Schwelle_2" ;
VAL_ 252 ESC_aktBR_Modus_02 0 "Aktivbremsung_Aus" 1 "Aktivbremsung_FastInit" 2 "Aktivbremsung_Aktiv" 3 "Aktivbremsung_NoLimitAktiv" ;
VAL_ 252 ESC_Blending_Solldruck 1022 "Init" 1023 "Fehler" ;
VAL_ 252 ESC_EBKV_Kraftblending_Modus 0 "Inactive" 1 "Hold" 2 "Active" ;
VAL_ 252 ESC_Bremsdruck_Modell 1022 "Init" 1023 "Fehler" ;
VAL_ 252 ESC_Bremsdruck_02 1023 "Fehler" ;
VAL_ 252 ESC_QBit_Bremsdruck_02 0 "gueltiger_Wert" 1 "Ersatz_Init_oder_Fehlerwert" ;
VAL_ 252 ESC_Allradverteilung_aktiv 0 "kein_Eingriff" 1 "Allradeingriff_aktiv" ;
VAL_ 252 ESP_HL_Radgeschw_02 65533 "Unterspannung" 65534 "Init" 65535 "Fehler" ;
VAL_ 252 ESP_HR_Radgeschw_02 65533 "Unterspannung" 65534 "Init" 65535 "Fehler" ;
VAL_ 252 ESP_VL_Radgeschw_02 65533 "Unterspannung" 65534 "Init" 65535 "Fehler" ;
VAL_ 252 ESP_VR_Radgeschw_02 65533 "Unterspannung" 65534 "Init" 65535 "Fehler" ;
VAL_ 252 ESP_FZR_uebersteuern 254 "Init" 255 "Fehler" ;
VAL_ 252 ESP_FZR_untersteuern 254 "Init" 255 "Fehler" ;
VAL_ 252 ESC_Anf_Mindestreku 0 "nicht_angefordert" 1 "angefordert" ;
VAL_ 252 ESC_GMV_aktiv 0 "keine_Aktivitaet" 1 "Aktivitaet_durch_AWA" ;
VAL_ 252 ESC_GMV_nicht_verfuegbar 0 "verfuegbar" 1 "nicht_verfuegbar" ;
VAL_ 252 ESC_Status_vRef_Stuetzeingriff 0 "kein_Eingriff" 1 "Stuetzungseingriff" ;
VAL_ 252 FDR_Allradverteilung_aktiv 0 "kein_Eingriff" 1 "Allradeingriff_aktiv" ;
VAL_ 252 FDR_Anf_Allradbetrieb 0 "keine_Anforderung" 1 "Kraftschluss_an_beiden_Achsen_herstellen" ;
VAL_ 252 ESP_HL_Bremsmoment 254 "Init" 255 "Fehler" ;
VAL_ 252 ESP_HR_Bremsmoment 254 "Init" 255 "Fehler" ;
VAL_ 252 ESP_VR_Bremsmoment 254 "Init" 255 "Fehler" ;
VAL_ 252 ESP_VL_Bremsmoment 254 "Init" 255 "Fehler" ;
VAL_ 252 ESP_FDR_uebersteuern 254 "Init" 255 "Fehler" ;
VAL_ 252 ESP_FDR_untersteuern 254 "Init" 255 "Fehler" ;
VAL_ 252 TSMomBegrenzung 4094 "Init" 4095 "Fehler" ;
VAL_ 252 ESC_Allrad_Anteil_max_sek 510 "Init" 511 "Fehler" ;
VAL_ 252 ESC_Allrad_Anteil_min_sek 510 "Init" 511 "Fehler" ;
VAL_ 252 ESC_Status_Eingriff 0 "kein Eingriff" 1 "ASR-Eingriff" 2 "MSR-Eingriff" 3 "nicht belegt " ;
VAL_ 252 ESC_Status_Eingriff_sek 0 "kein Eingriff" 1 "ASR-Eingriff" 2 "MSR-Eingriff" 3 "nicht belegt " ;
VAL_ 252 ESC_MomRad_Eingriff 8190 "Init" 8191 "Fehler" ;
VAL_ 252 ESC_MomRad_Eingriff_sek 8190 "Init" 8191 "Fehler" ;
VAL_ 252 ESC_Achsdrehzahl_Max 16382 "Init" 16383 "Fehler" ;
VAL_ 252 ESC_Achsdrehzahl_Min 16382 "Init" 16383 "Fehler" ;
VAL_ 252 ESC_Achsdrehzahl_Max_sek 16382 "Init" 16383 "Fehler" ;
VAL_ 252 ESC_Achsdrehzahl_Min_sek 16382 "Init" 16383 "Fehler" ;
VAL_ 278 ESP_QBit_Wegimpuls_VL 0 "gueltiger_Wert" 1 "Ersatz_Init_oder_Fehlerwert" ;
VAL_ 278 ESP_QBit_Wegimpuls_VR 0 "gueltiger_Wert" 1 "Ersatz_Init_oder_Fehlerwert" ;
VAL_ 278 ESP_QBit_Wegimpuls_HL 0 "gueltiger_Wert" 1 "Ersatz_Init_oder_Fehlerwert" ;
VAL_ 278 ESP_QBit_Wegimpuls_HR 0 "gueltiger_Wert" 1 "Ersatz_Init_oder_Fehlerwert" ;
VAL_ 278 ESP_Wegimpuls_VL 1021 "Init" 1022 "Unterspannung" 1023 "Fehler" ;
VAL_ 278 ESP_Wegimpuls_VR 1021 "Init" 1022 "Unterspannung" 1023 "Fehler" ;
VAL_ 278 ESP_Wegimpuls_HL 1021 "Init" 1022 "Unterspannung" 1023 "Fehler" ;
VAL_ 278 ESP_Wegimpuls_HR 1021 "Init" 1022 "Unterspannung" 1023 "Fehler" ;
VAL_ 278 ESP_VL_Fahrtrichtung 0 "Vorwaerts" 1 "Rueckwaerts" 2 "Init" 3 "ungueltig_oder_nicht_verbaut" ;
VAL_ 278 ESP_VR_Fahrtrichtung 0 "Vorwaerts" 1 "Rueckwaerts" 2 "Init" 3 "ungueltig_oder_nicht_verbaut" ;
VAL_ 278 ESP_HL_Fahrtrichtung 0 "Vorwaerts" 1 "Rueckwaerts" 2 "Init" 3 "ungueltig_oder_nicht_verbaut" ;
VAL_ 278 ESP_HR_Fahrtrichtung 0 "Vorwaerts" 1 "Rueckwaerts" 2 "Init" 3 "ungueltig_oder_nicht_verbaut" ;
VAL_ 1629 BR_Systemart 0 "ABS" 1 "ABS_ASR" 2 "ESP" 3 "ESP_mit_integrierter_EPB" ;
VAL_ 1629 ESP_SpannungsAnf_02 0 "keine_Anforderung" 1 "Anforderung_Stufe1" 2 "Anforderung_Stufe2" 3 "Anforderung_Stufe3" ;
VAL_ 1629 ESP_Charisma_FahrPr 0 "keine_Funktion" 1 "Programm_1" 2 "Programm_2" 3 "Programm_3" 4 "Programm_4" 5 "Programm_5" 6 "Programm_6" 7 "Programm_7" 8 "Programm_8" 9 "Programm_9" 10 "Programm_10" 11 "Programm_11" 12 "Programm_12" 13 "Programm_13" 14 "Programm_14" 15 "Programm_15" ;
VAL_ 1629 ESP_Charisma_Status 0 "Init" 1 "verfuegbar" 2 "nicht_verfuegbar" 3 "asynchron_durch_Fahrerwunsch" ;
VAL_ 1629 ESP_Wiederstart_Anz_01 0 "keine_Anzeige" 1 "Rueckwaertsrollen" ;
VAL_ 1629 ESP_Wiederstart_Anz_02 0 "keine_Anzeige" 1 "Autohold_Rutschen" ;
VAL_ 1629 ESP_Wiederstart_Anz_03 0 "keine_Anzeige" 1 "Offroad_HDC" ;
VAL_ 1629 ESP_Wiederstart_Anz_04 0 "keine_Anzeige" 1 "ESC_Off" ;
VAL_ 1629 ESP_Stoppverbot_Anz_01 0 "keine_Anzeige" 1 "Notbremsung_aktiv" ;
VAL_ 1629 ESP_Stoppverbot_Anz_02 0 "keine_Anzeige" 1 "Autohold_AVH_Rutschen" ;
VAL_ 1629 ESP_Stoppverbot_Anz_03 0 "keine_Anzeige" 1 "Rueckwaertsrollen" ;
VAL_ 1629 ESP_Stoppverbot_Anz_04 0 "keine_Anzeige" 1 "ESP_Pumpenlauf" ;
VAL_ 1629 ESP_Stoppverbot_Anz_05 0 "keine_Anzeige" 1 "ESP_OFF" ;
VAL_ 1629 ESP_Stoppverbot_Anz_06 0 "keine_Anzeige" 1 "Offroad_HDC" ;
VAL_ 1629 ESP_Stoppverbot_Anz_07 0 "keine_Anzeige" 1 "ESP_Haltefunktion_nicht_verfuegbar" ;
VAL_ 1629 ESP_Stoppverbot_Anz_Std 0 "keine_Anzeige" 1 "Standard_Stoppvetogrund" ;
VAL_ 1629 ESP_Dachrelingsensor 0 "Sensor_nicht_verbaut" 1 "Quertraeger_montiert" 2 "Quertraeger_nicht_montiert" 3 "Fehler" ;
VAL_ 1629 ESP_Stoppverbot_Anz_08 0 "keine_Anzeige" 1 "Neigungsbegrenzung" ;
VAL_ 1629 HDC_Charisma_FahrPr 0 "keine_Funktion" 1 "Programm_1" 2 "Programm_2" 3 "Programm_3" 4 "Programm_4" 5 "Programm_5" 6 "Programm_6" 7 "Programm_7" 8 "Programm_8" 9 "Programm_9" 10 "Programm_10" 11 "Programm_11" 12 "Programm_12" 13 "Programm_13" 14 "Programm_14" 15 "Programm_15" ;
VAL_ 1629 HDC_Charisma_Status 0 "Init" 1 "verfuegbar" 2 "nicht_verfuegbar" 3 "asynchron_durch_Fahrerwunsch" ;
VAL_ 1629 BR_QBit_Reifenumfang 0 "gueltiger_Wert" 1 "Ersatz_Init_oder_Fehlerwert" ;
VAL_ 253 BR_Eingriffsmoment 1022 "Init" 1023 "Fehler" ;
VAL_ 253 ESP_PLA_Bremseingriff 0 "inaktiv" 1 "aktiv" ;
VAL_ 253 ESP_Diagnose 0 "ESP_nicht_in_Diagnose" 1 "ESP_in_Diagnose" ;
VAL_ 253 ESC_Reku_Freigabe 0 "keine_Freigabe_der_Rekuperation" 1 "Freigabe_der_Rekuperation" ;
VAL_ 253 ESC_v_Signal_Qualifier_High_Low 0 "Gueteschwelle_kleiner_1kmh" 1 "Gueteschwelle_kleiner_3kmh" 2 "Gueteschwelle_kleiner_5kmh" 3 "Gueteschwelle_kleiner_10kmh" 4 "Gueteschwelle_kleiner_20kmh" 5 "Gueteschwelle_groessergleich_20kmh" 6 "Init" 7 "Fehler" ;
VAL_ 253 ESP_Vorsteuerung 0 "keine_Vorsteuerung_aktiv" 1 "Vorsteuerung_aktiv" ;
VAL_ 253 ESP_AWV3_Brems_aktiv 0 "inaktiv" 1 "aktiv" ;
VAL_ 253 OBD_Schlechtweg 0 "kein_Schlechtweg_erkannt" 1 "Schlechtweg_erkannt" ;
VAL_ 253 OBD_QBit_Schlechtweg 0 "gueltiger_Wert" 1 "Ersatz_Init_oder_Fehlerwert" ;
VAL_ 253 ESP_v_Signal 65533 "Unterspannung" 65534 "Init" 65535 "Fehler" ;
VAL_ 253 ASR_Tastung_passiv 0 "ASR_aktiviert" 1 "ASR_passiv_getastet_oder_Schwellen_geaendert" ;
VAL_ 253 ESP_Tastung_passiv 0 "ESP_aktiviert" 1 "ESP_passiv_getastet_oder_Schwellen_geaendert" ;
VAL_ 253 ESP_Systemstatus 0 "iO" 1 "Fehler" ;
VAL_ 253 ASR_Schalteingriff 0 "keine_Anforderung" 1 "ASR_Schaltkennfeld" 2 "Rueckschaltung" 3 "Schaltverbot" ;
VAL_ 253 ESP_Haltebestaetigung 0 "kein_sicheres_Halten" 1 "sicheres_Halten" ;
VAL_ 253 ESP_MKB_Abbruch_Geschw 0 "MKB_nicht_beendet_wg_v_Schwelle" 1 "MKB_beendet_wg_v_Schwelle" ;
VAL_ 253 ESP_QBit_v_Signal 0 "gueltiger_Wert" 1 "Ersatz_Init_oder_Fehlerwert" ;
VAL_ 253 ABS_Bremsung 0 "keine_ABS_Regelung" 1 "ABS_Regelung_aktiv" ;
VAL_ 253 ASR_Anf 0 "keine_Anforderung" 1 "ASR_Anforderung" ;
VAL_ 253 MSR_Anf 0 "keine Anfoderung" 1 "MSR-Anforderung" ;
VAL_ 253 EBV_Eingriff 0 "kein_EBV_Eingriff" 1 "EBV_Eingriff" ;
VAL_ 253 EDS_Eingriff 0 "kein_EDS_Eingriff" 1 "EDS_Eingriff" ;
VAL_ 253 ESP_Eingriff 0 "kein_ESP_Eingriff" 1 "ESP_Eingriff_aktiv" ;
VAL_ 253 ESP_ASP 0 "inaktiv" 1 "aktiv" ;
VAL_ 253 ESP_Anhaltevorgang_ACC_aktiv 0 "inaktiv" 1 "aktiv" ;
VAL_ 2527679740 KBI_aktive_Laengsfunktion_02 0 "Init" 1 "Speedlimiter" 2 "GRA_oder_ACC" 3 "PACCh" 4 "HDC" 5 "p_GRA" 6 "p_Lim" 7 "ACC_im_GRA_Modus" 8 "Travel_Assist" 9 "RHP" ;
VAL_ 2527679740 KBI_Anzeigestatus_GRA 0 "nicht_vorhanden" 1 "Anzeigemoeglichkeit_vorhanden" 2 "reserviert" 3 "Fehler" ;
VAL_ 2527679740 KBI_Anzeigestatus_LIM 0 "nicht_vorhanden" 1 "Anzeigemoeglichkeit_vorhanden" 2 "reserviert" 3 "Fehler" ;
VAL_ 2527679740 KBI_Anzeigestatus_ACC 0 "keine_ACC_Anzeige" 1 "ACC_Anzeige_aktiv" ;
VAL_ 2527679740 KBI_Konsistenz_ACC 0 "ACC Botschaft konsistent" 1 "ACC Botschaft inkonsistent" ;
VAL_ 2527679740 KBI_Fehler_Anzeige_ACC 0 " iO" 1 "Anzeigefehler ACC" ;
VAL_ 2527679740 KBI_Anzeigefehler_LDW 0 "nicht vorhanden bzw. unterstützt" 1 "Anzeige iO" 2 "Anzeigefehler" 3 "nicht definiert" ;
VAL_ 1605 FLA_aktiv 0 "inaktiv" 1 "aktiv" ;
VAL_ 1605 FLA_ISP_defekt 0 "iO" 1 "defekt" ;
VAL_ 1605 FLA_Sensor_blockiert 0 "Sensor in Ordnung" 1 "Sensor blockiert" ;
VAL_ 1605 FLA_Abblendursache 0 "nichts erkannt (Init-Wert)" 1 "enentgegenkommendes Fahrzeug (Scheinwerfer erkannt)" 2 "vorausfahrendes Fahrzeug (Heckleuchten erkannt)" 4 "Geschwindigkeitslimit unterschritten" 8 "Ort_oder_Infrastruktur_erkannt" 16 "Umgebungshelligkeit_generell_zu_hell" 32 "Nebel_oder_Sensor_blockiert" 64 "Übertemperatur Imager" 128 "Verzögerungsbedingung" 255 "Fehler" ;
VAL_ 1605 FLA_Fernlicht_PWM 127 "Fehler" ;
VAL_ 1605 ISP_EC_Lichtwert_vorne 62 "Init" 63 "Fehler" ;
VAL_ 1605 ISP_EC_Lichtwert_hinten 62 "Init" 63 "Fehler" ;
VAL_ 1605 ISP_Himmelsrichtung 30 "nicht verfuegbar bzw. Init" 31 "Fehler" ;
VAL_ 1605 ISP_Taste_betaetigt 0 "nicht_betaetigt" 1 "betaetigt" ;
VAL_ 1605 ISP_EC_aktiv 0 "inaktiv" 1 "aktiv" ;
VAL_ 1605 ISP_Kompass_aktiv 0 "inaktiv" 1 "aktiv" ;
VAL_ 1605 FLA_Aufblenden 0 "nicht_aufblenden" 1 "aufblenden" ;
VAL_ 1605 FLA_SAE_Mode 0 "Init" 1 "FLA_Icon_invertiert" ;
VAL_ 2589283684 FoD_State_TopView_SideView_RVC 0 "default" 1 "RVC_TopView_SideView_nicht_aktiv" 2 "RVC_aktiv" 3 "RVC_nicht_aktiv" 4 "TopView_SideView_nicht_aktiv" 5 "RVC_TopView_aktiv" 6 "SideView_aktiv" 7 "RVC_SideView_aktiv" 8 "RVC_TopView_SideView_aktiv" ;
VAL_ 2589283684 FoD_State_IPA_RPA 0 "default" 1 "nicht_aktiv" 2 "IPA_aktiv" 3 "IPA_und_RPA_aktiv" ;
VAL_ 2589283684 FoD_State_TPA_rTPA 0 "default" 1 "nicht_aktiv" 2 "TPA_aktiv" 3 "TPA_und_rTPA_aktiv" ;
VAL_ 2589283684 GRA_FoD_Status 0 "Init" 1 "Funktion_inaktiv" 2 "Funktion_aktiv" ;
VAL_ 2589283684 FoD_Transmission_Info 0 "Initwert" 1 "start_transmission" 2 "finish_transmission" ;
VAL_ 2589283684 FoD_Anz_Funktionsabschaltung 0 "Init" 1 "Popup_aufschalten" ;
VAL_ 987 BCM_01_alt 0 "aktuell" 1 "veraltet" ;
VAL_ 987 SMLS_01_alt 0 "aktuell" 1 "veraltet" ;
VAL_ 987 ZV_02_alt 0 "aktuell" 1 "veraltet" ;
VAL_ 987 Wischer_01_alt 0 "aktuell" 1 "veraltet" ;
VAL_ 987 Anhaenger_01_alt 0 "aktuell" 1 "veraltet" ;
VAL_ 987 Klima_Sensor_02_alt 0 "aktuell" 1 "veraltet" ;
VAL_ 987 Verdeck_01_alt 0 "aktuell" 1 "veraltet" ;
VAL_ 987 Klima_11_alt 0 "aktuell" 1 "veraltet" ;
VAL_ 987 WFS_01_alt 0 "aktuell" 1 "veraltet" ;
VAL_ 987 Licht_Anf_01_alt 0 "aktuell" 1 "veraltet" ;
VAL_ 987 ZV_verriegelt_extern_soll 1 "Fahrzeug verriegelt extern; Sollzusstand" ;
VAL_ 987 BH_Lichthupe 0 "nicht_betaetigt" 1 "Blinkerhebel in Richtung Lichthupe betaetigt" ;
VAL_ 987 WFS_Klemmenfreigabe 0 "keine_Freigabe" 1 "Freigabe" ;
VAL_ 987 ZV_Tankklappe_offen 0 "Tankklappe_geschlossen" 1 "Tankklappe_offen" ;
VAL_ 987 AAG_Anhaenger_abgesteckt 1 "Anhaenger_wurde_bei_KL15_aus_abgesteckt" ;
VAL_ 987 BCM1_LDS_Stellung 0 "Init" 1 "Stellung_0" 2 "Auto" 3 "Standlicht" 4 "Abblendlicht" 7 "Fehler" ;
VAL_ 987 VS_Verdeck_Anf 0 "init_nicht_aktiv" 1 "aktiv" ;
VAL_ 987 VS_VD_entriegelt 0 "Init" 1 "Zustand_des_Verdeck_entriegelt" ;
VAL_ 987 ZV_HFS_offen 0 "geschlossen" 1 "offen" ;
VAL_ 987 ZV_HBFS_offen 0 "geschlossen" 1 "offen" ;
VAL_ 987 VS_VD_offen_ver 0 "Init" 1 "Verdeck_verriegelt_und_offen" ;
VAL_ 987 VS_VD_zu_ver 1 "Zustand des Verdecks verriegelt und geschlossen" ;
VAL_ 987 ZV_BT_offen 0 "BT_geschlossen" 1 "BT_geoeffnet" ;
VAL_ 987 BCM1_Rueckfahrlicht_Schalter 0 "nicht_betaetigt" 1 "betaetigt" ;
VAL_ 987 ZV_FT_offen 0 "FT_geschlossen" 1 "FT_geoeffnet" ;
VAL_ 987 Wischer_vorne_aktiv 0 "Init" 1 "Wischer_vorne_laeuft" ;
VAL_ 987 AAG_Anhaenger_erkannt 0 "kein_Anhaenger_erkannt" 1 "AAG_Anhaenger_erkannt" ;
VAL_ 987 BCM1_MH_Schalter 0 "MH_geschlossen" 1 "MH_offen" ;
VAL_ 987 ZV_HD_offen 1 "Heckdeckel_auf" ;
VAL_ 987 Waschen_vorne_aktiv 0 "inaktiv" 1 "Waschen_aktiv" ;
VAL_ 987 KL_Thermomanagement 0 "keine_Freigabe_TMM__max_Heizbedarf" 1 "kleine_Freigabe_TMM" 2 "mittlere_Freigabe_TMM" 3 "volle_Freigabe_TMM__kein_Heizbedarf" ;
VAL_ 987 WFS_Schluessel_Fahrberecht 0 "kein authorisierter Schluessel erkannt" 1 "aktive_Funkschluessel_Nr_01" 2 "aktive_Funkschluessel_Nr_02" 3 "aktive_Funkschluessel_Nr_03" 4 "aktive_Funkschluessel_Nr_04" 5 "aktive_Funkschluessel_Nr_05" 6 "aktive_Funkschluessel_Nr_06" 7 "aktive_Funkschluessel_Nr_07" 8 "aktive_Funkschluessel_Nr_08" 9 "ungueltig_09" 10 "ungueltig_10" 11 "ungueltig_11" 12 "ungueltig_12" 13 "ungueltig_13" 14 "ungueltig_14" 15 "digitaler_Schluessel_aktiv" ;
VAL_ 987 BCM_Rueckfahrlicht_Anf 0 "Licht_nicht_angefordert" 1 "Licht_angefordert" ;
VAL_ 987 WWSs_01_alt 0 "aktuell" 1 "veraltet" ;
VAL_ 987 BCM_Tankklappensteller_Fehler 0 "kein_Fehler" 1 "Fehler" ;
VAL_ 987 AAG_LED_aktiv 0 "Lampen" 1 "LED" ;
VAL_ 987 ZV_verriegelt_soll 0 "Init" 1 "nicht_verriegelt" 2 "verriegelt" ;
VAL_ 987 ZV_Schluessel_Zugang 0 "kein_auth_Schluessel_erkannt" 1 "aktive_Funkschluessel_Nr_01" 2 "aktive_Funkschluessel_Nr_02" 3 "aktive_Funkschluessel_Nr_03" 4 "aktive_Funkschluessel_Nr_04" 5 "aktive_Funkschluessel_Nr_05" 6 "aktive_Funkschluessel_Nr_06" 7 "aktive_Funkschluessel_Nr_07" 8 "aktive_Funkschluessel_Nr_08" 9 "aktive_SmartDevice_Nr_09" 10 "ungueltig_10" 11 "ungueltig_11" 12 "ungueltig_12" 13 "ungueltig_13" 14 "ungueltig_14" 15 "ungueltig_15" ;
VAL_ 987 WFS_ID_Geb_autorisiert_in_Kl15 0 "nicht_authorisiert_in_Kl15" 1 "authorisiert_in_Kl15" ;
VAL_ 987 BH_Fernlicht 0 "nicht_betaetigt" 1 "Blinkerhebel_in_Richtung_Fernlicht_betaetigt" ;
VAL_ 987 BH_Blinker_li 0 "nicht_betaetigt" 1 "Blinkerhebel_Pos_li_betaetigt" ;
VAL_ 987 BH_Blinker_re 0 "nicht_betaetigt" 1 "Blinkerhebel_Pos_re_betaetigt" ;
VAL_ 987 BCM1_OBD_FStatus_ATemp 0 "kein Fehler / Init / nicht verbaut" 1 "KS- (Kurzschluss nach minus)" 2 "KS+ (Kurzschluss nach plus)" 3 "OC (Leitungsunterbrechung)" 4 "OOR+ (Signal zu gross)" 5 "OOR- (Signal zu klein)" 6 "RC+ (Signal unplausibel zu gross)" 7 "RC- (Signal unplausibel zu klein)" 8 "KS+/OC (Kurzschluss nach plus/Unterbrechung)" 9 "KS-/OC  (Kurzschluss nach minus/Unterbrechung)" 10 "KS-/KS+  (Kurzschluss nach minus/plus)" 11 "KS-/KS+/OC (Kurzschluss nach minus/plus/Unterbrechung)" 12 "frei" 13 "frei" 14 "frei" 15 "frei" ;
VAL_ 987 BCM1_Aussen_Temp_ungef 253 "nicht_verbaut" 254 "Initwert" 255 "Fehler" ;
VAL_ 988 Motor_12_alt 0 "aktuell" 1 "veraltet" ;
VAL_ 988 ESP_07_alt 0 "aktuell" 1 "veraltet" ;
VAL_ 988 Getriebe_11_alt 0 "aktuell" 1 "veraltet" ;
VAL_ 988 Getriebe_13_alt 0 "aktuell" 1 "veraltet" ;
VAL_ 988 Getriebe_17_alt 0 "aktuell" 1 "veraltet" ;
VAL_ 988 TSK_06_alt 0 "aktuell" 1 "veraltet" ;
VAL_ 988 Getriebe_14_alt 0 "aktuell" 1 "veraltet" ;
VAL_ 988 ESP_50_alt 0 "aktuell" 1 "veraltet" ;
VAL_ 988 MO_QBit_Drehzahl_01 0 "gueltiger_Wert" 1 "Ersatz_Init_oder_Fehlerwert" ;
VAL_ 988 MKE_Texte 0 "keine_Anzeige" 1 "Warnstufe_1" 2 "Warnstufe_2" ;
VAL_ 988 MKE_Stufe 0 "deaktiviert" 1 "nicht_verfügbar" 2 "Stufe_1" 3 "Stufe_2" 4 "Stufe_3" 5 "Stufe_4" 6 "reserviert" 7 "reserviert" ;
VAL_ 988 TSK_Hauptschalter_GRA_ACC 0 "Init" 1 "Aus" 2 "Ein" 3 "Fehler" ;
VAL_ 988 GE_Fahrstufe 0 "Zwischenstellung" 1 "Init" 5 "Position_P" 6 "Position_R" 7 "Position_N" 8 "Position_D" 9 "Position_S" 10 "Effizienz" 13 "Tipp_in_S" 14 "Tipp_in_D" 15 "Fehler" ;
VAL_ 988 GE_Ursache_Fahrstufe_N 0 "Fahrstufe_N_mit_Fahrerwunsch" 1 "Fahrstufe_N_ohne_Fahrerwunsch" ;
VAL_ 988 GE_Notlauf 0 "kein Notlauf / Init" 1 "Getriebe im Notlauf" ;
VAL_ 988 ESP_Rollenmodus_Deaktivieren 0 "keine_Aenderung" 1 "Abbruch" ;
VAL_ 988 GE_Freilauf_Status 0 "Freilauf_inaktiv_aber_moeglich" 1 "Freilauf_aktiv" 2 "Freilauf_nicht_moegl_1Verhinderer" 3 "Freilauf_nicht_moegl_gr_1Verhinderer" 7 "Fehler" ;
VAL_ 988 GE_Sperr_Info_WFS 0 "nicht_gesperrt" 1 "gesperrt" ;
VAL_ 988 TSK_Limiter_ausgewaehlt 0 "kein_Limiter_ausgewaehlt" 1 "Limiter_ausgewaehlt" ;
VAL_ 988 EPB_Status_02 0 "offen" 1 "geschlossen_Parken" 2 "teilgespannt_Halten" 3 "im_Lauf_oeffnen" 4 "im_Lauf_schliessen" 5 "tbd" 6 "Init" 7 "unbekannt" ;
VAL_ 988 ACC_Status_ACC 0 "ACC_OFF_Hauptschalter_aus" 1 "ACC_INIT" 2 "ACC_STANDBY" 3 "ACC_AKTIV_regelt" 4 "ACC_OVERRIDE" 5 "ACC_Abschaltreaktion" 6 "reversibler_Fehler_im_ACC_System" 7 "irreversibler_Fehler_im_ACC_System" ;
VAL_ 988 ACC_18_alt 0 "aktuell" 1 "veraltet" ;
VAL_ 988 ESP_Status_Bremsentemp_02 0 "nicht_erhoeht" 1 "Schwelle_1" 2 "Schwelle_2" ;
VAL_ 173 GE_MMom_Soll_02 1022 "keine_Anforderung_Init" 1023 "Fehler" ;
VAL_ 173 GE_MMom_Vorhalt_02 1022 "Init" 1023 "Fehler" ;
VAL_ 173 GE_Uefkt 1023 "Fehler" ;
VAL_ 173 GE_Fahrstufe 0 "Zwischenstellung" 1 "Init" 5 "Position_P" 6 "Position_R" 7 "Position_N" 8 "Position_D" 9 "Position_S" 10 "Effizienz" 13 "Tipp_in_S" 14 "Tipp_in_D" 15 "Fehler" ;
VAL_ 173 GE_Ursache_Fahrstufe_N 0 "Fahrstufe_N_mit_Fahrerwunsch" 1 "Fahrstufe_N_ohne_Fahrerwunsch" ;
VAL_ 173 GE_Schaltablauf 0 "keine_Schaltung" 1 "Momentenueberschneidung" 2 "Befuellphase" 3 "Drehzahlueberfuehrung" ;
VAL_ 173 GE_Uefkt_unplausibel 0 "Uefkt_plausibel" 1 "Uefkt_unplausibel" ;
VAL_ 173 GE_MMom_Status_02 0 "kein_Eingriff" 1 "abs_reduzierender_Eingriff_auf_Gesamt_Antrieb_nur_schneller_Pfad" 2 "abs_erhoehender_Eingriff_auf_Gesamt_Antrieb" 3 "relativer_Eingriff_auf_Gesamt_Antrieb" 4 "relativer_Eingriff_auf_E_Maschine" 5 "abs_red_Eingr_auf_Gesamt_Antrieb_nur_Luftpfad" 6 "abs_red_Eingr_auf_Gesamt_Antrieb_Luft-_und_schnellen_Pfad" 7 "abs_Eingriff_auf_Gesamtantrieb_erhoehend_und_reduzierend" ;
VAL_ 173 GE_Status_Kraftschluss 0 "offen_kein_Kraftschluss" 1 "offen_mit_Kraftschluss" 2 "schlupfend_geregelt" 3 "abgesichert_offen_kein_Kraftschl" 4 "geschlossen_mit_Mikroschlupf" 5 "geschlossen_mit_Ueberanpressung" 6 "sonstige_Fehler" 7 "fehlerhaft_geschlossen" ;
VAL_ 173 GE_MMom_Status 0 "keine Anforderung" 1 "reduzierender Getriebeeingriff" 2 "erhöhender Getriebeeingriff" 3 "Änderung mit Sprung" ;
VAL_ 173 GE_Freig_MMom_Vorhalt 0 "nicht_freigegeben" 1 "freigegeben" ;
VAL_ 173 GE_Verbot_Ausblendung 0 "kein_Verbot" 1 "Verbot" ;
VAL_ 173 GE_Zielgang 0 "Gang P/N (ausgekuppelt)" 1 "Gang 1" 2 "Gang 2" 3 "Gang 3" 4 "Gang 4" 5 "Gang 5" 6 "Gang 6" 7 "Gang 7" 8 "Gang R" 11 "Gang 8" 12 "Gang 9" 13 "Gang10" 14 "Istgang nicht definiert" 15 "Fehler" ;
VAL_ 2463978722 GNSS_DR_Breite_Ortung 134217726 "Init" 134217727 "Fehler" ;
VAL_ 2463978722 GNSS_DR_Richtung_Breite_Ortung 0 "Nord" 1 "Sued" ;
VAL_ 2463978722 GNSS_DR_Laenge_Ortung 268435454 "Init" 268435455 "Fehler" ;
VAL_ 2463978722 GNSS_DR_Richtung_Laenge_Ortung 0 "Ost" 1 "West" ;
VAL_ 2463978723 GNSS_DR_Ortung_Ausrichtung 4094 "Init" 4095 "Fehler" ;
VAL_ 2463978723 GNSS_DR_Ortung_2D_Geschw_u_Grund 510 "Init" 511 "Fehler" ;
VAL_ 299 GRA_Hauptschalter 0 "Aus_Taster_nicht_betaetigt" 1 "Ein_Taster_betaetigt" ;
VAL_ 299 GRA_Abbrechen 0 "nicht_betaetigt" 1 "betaetigt" ;
VAL_ 299 GRA_Typ_Hauptschalter 0 "gerasteter_Lenkstockschalter" 1 "getasteter_Lenkstockschalter" ;
VAL_ 299 GRA_Limiter 0 "nicht_betaetigt" 1 "betaetigt" ;
VAL_ 299 GRA_Tip_Setzen 0 "nicht_betaetigt" 1 "betaetigt" ;
VAL_ 299 GRA_Tip_Hoch 0 "nicht_betaetigt" 1 "betaetigt" ;
VAL_ 299 GRA_Tip_Runter 0 "nicht_betaetigt" 1 "betaetigt" ;
VAL_ 299 GRA_Tip_Wiederaufnahme 0 "nicht_betaetigt" 1 "betaetigt" ;
VAL_ 299 GRA_Verstellung_Zeitluecke 0 "Taste_nicht_betaetigt" 1 "Dist_minus_1" 2 "Dist_plus_1" 3 "Dist_Toggle" ;
VAL_ 299 GRA_Codierung 0 "kein_Hebel" 1 "GRA_Hebel" 2 "ACC_Hebel" 3 "Limiter_Only" ;
VAL_ 299 GRA_Fehler 0 "kein_Fehler" 1 "Fehler" ;
VAL_ 299 GRA_LIM_Taste_verfuegbar 0 "Limiter_Taste_nicht_vorhanden" 1 "Limiter_Taste_vorhanden" ;
VAL_ 299 GRA_Tip_Stufe_2 0 "Tip_Stufe_1_keine_Betaetigung" 1 "Tip_Stufe_2" ;
VAL_ 299 GRA_Typ_Bedienteil 0 "Init" 1 "4_Positions_Bedienteil" 2 "6_Positions_Bedienteil" 3 "8_Positions_Bedienteil" 4 "PAG_5_Positions_Bedienteil" 5 "VW_MFL_Gen2" 6 "VW_MFL_Gen3" 7 "PAG_DX1_Bedienteil" ;
VAL_ 299 GRA_TravelAssist 0 "nicht_betaetigt" 1 "betaetigt" ;
VAL_ 299 GRA_PIT_Limiter 0 "nicht_betaetigt" 1 "betaetigt" ;
VAL_ 294 HCA_01_Sendestatus 0 "HCA_sendet_mit_1000ms" 1 "HCA_sendet_mit_20ms" ;
VAL_ 294 HCA_01_LM_OffSign 0 "positives_Vorzeichen" 1 "negatives_Vorzeichen" ;
VAL_ 294 HCA_01_Status_HCA 0 "deaktiviert" 1 "reserviert" 2 "reserviert" 3 "funktionsbereit" 4 "reserviert" 5 "HCA_Momenteneingriff_1" 6 "MA_Aktiv" 7 "HCA_Momenteneingriff_2" 8 "HCA_Momenteneingriff_3" 9 "reserviert" 10 "reserviert" 11 "reserviert" 12 "reserviert" 13 "reserviert" 14 "reserviert" 15 "reserviert" ;
VAL_ 771 HCA_QFK_AnfStat 1 "Init" 2 "Bereit" 4 "Eingriff" ;
VAL_ 771 HCA_QFK_KruemmSoll_VZ 0 "positiv" 1 "negativ" ;
VAL_ 771 HCA_03_Sendestatus 0 "langsamer_Zyklus" 1 "schneller_Zyklus" ;
VAL_ 771 HCA_QFK_KrSoll_VZ 0 "positiv" 1 "negativ" ;
VAL_ 771 FoD_DTC_TPA_rTPA_MFK 0 "Kein_DTC" 1 "TPA_DTC_vorhanden" 2 "rTPA_DTC_vorhanden" 3 "TPA_und_rTPA_DTC_vorhanden" ;
VAL_ 771 HCA_QFK_KrSoll 65535 "Init" ;
